VERSION ""

NS_ :

BS_:

BU_: ATCM_FFSM GENERIC_GWMWakeup IPMB Generic_BCM GWM _delete ABS_ESC HUD IPMA CCM PSCM SCCM TBM OCS TCCM TSTR RCM

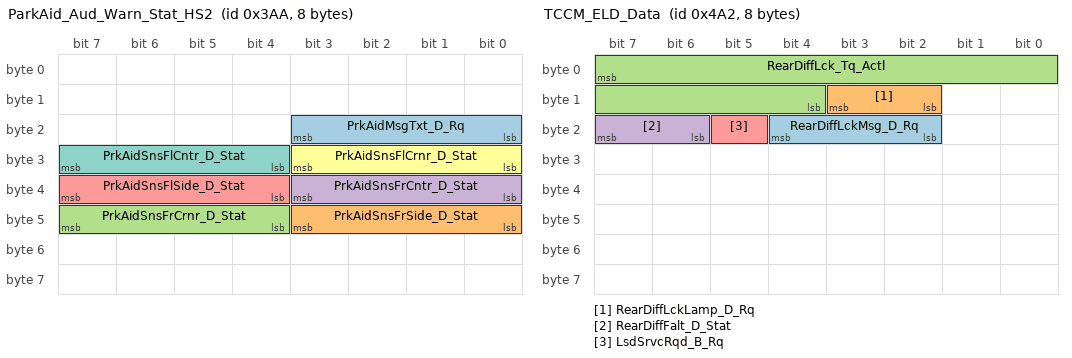
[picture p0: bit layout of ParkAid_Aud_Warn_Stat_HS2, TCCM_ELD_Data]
BO_ 938 ParkAid_Aud_Warn_Stat_HS2: 8 GWM
 SG_ PrkAidMsgTxt_D_Rq : 19|4@0+ (1,0) [0|15] "SED"  IPMB
 SG_ PrkAidSnsFrSide_D_Stat : 43|4@0+ (1,0) [0|15] "SED"  IPMB
 SG_ PrkAidSnsFrCrnr_D_Stat : 47|4@0+ (1,0) [0|15] "SED"  IPMB
 SG_ PrkAidSnsFrCntr_D_Stat : 35|4@0+ (1,0) [0|15] "SED"  IPMB
 SG_ PrkAidSnsFlSide_D_Stat : 39|4@0+ (1,0) [0|15] "SED"  IPMB
 SG_ PrkAidSnsFlCrnr_D_Stat : 27|4@0+ (1,0) [0|15] "SED"  IPMB
 SG_ PrkAidSnsFlCntr_D_Stat : 31|4@0+ (1,0) [0|15] "SED"  IPMB

BO_ 1441 TCCM_AutoSar_Network_Mgmt: 8 TCCM
 SG_ TCCM_AutoSar_Network_Mgmt : 7|64@0+ (1,0) [0|1.844674407371E+019] "unitless"  ABS_ESC,SCCM,TBM,GWM

BO_ 1472 TBM_AutoSar_Network_Mgmt: 8 TBM
 SG_ TBM_AutoSar_Network_Mgmt : 7|64@0+ (1,0) [0|1.844674407371E+019] "unitless"  TCCM,GWM,ABS_ESC

BO_ 1186 TCCM_ELD_Data: 8 TCCM
 SG_ RearDiffLckMsg_D_Rq : 20|3@0+ (1,0) [0|7] "SED"  GWM
 SG_ RearDiffLckLamp_D_Rq : 11|2@0+ (1,0) [0|3] "SED"  ATCM_FFSM,GWM
 SG_ RearDiffLck_Tq_Actl : 7|12@0+ (1,0) [0|4093] "Nm"  ABS_ESC,GWM
 SG_ RearDiffFalt_D_Stat : 23|2@0+ (1,0) [0|3] "SED"  GWM,ABS_ESC
 SG_ LsdSrvcRqd_B_Rq : 21|1@0+ (1,0) [0|1] "SED"  GWM

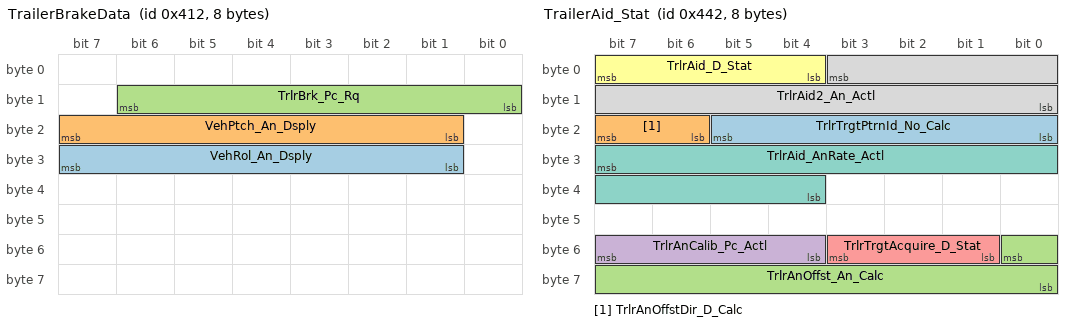
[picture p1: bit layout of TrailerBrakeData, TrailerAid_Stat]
BO_ 1042 TrailerBrakeData: 8 ABS_ESC
 SG_ VehRol_An_Dsply : 31|7@0+ (1,-64) [-64|61] "degrees"  GWM
 SG_ VehPtch_An_Dsply : 23|7@0+ (1,-64) [-64|61] "degrees"  GWM
 SG_ TrlrBrk_Pc_Rq : 14|7@0+ (1,0) [0|127] "percent"  TBM

BO_ 1090 TrailerAid_Stat: 8 IPMB
 SG_ TrlrTrgtPtrnId_No_Calc : 21|6@0+ (1,0) [0|63] "unitless"  GWM
 SG_ TrlrAnOffstDir_D_Calc : 23|2@0+ (1,0) [0|3] "SED"  PSCM,GWM
 SG_ TrlrAnOffst_An_Calc : 48|9@0+ (0.1,0) [0|51.1] "degrees"  PSCM,GWM
 SG_ TrlrAnCalib_Pc_Actl : 55|4@0+ (10,0) [0|140] "percent"  PSCM,GWM
 SG_ TrlrTrgtAcquire_D_Stat : 51|3@0+ (1,0) [0|7] "SED"  PSCM,GWM
 SG_ TrlrAid_D_Stat : 7|4@0+ (1,0) [0|15] "SED"  PSCM
 SG_ TrlrAid_AnRate_Actl : 31|12@0+ (0.1,-50) [-50|359.4] "degrees/sec"  PSCM
 SG_ TrlrAid2_An_Actl : 3|12@0+ (0.1,-90) [-90|319.4] "degrees"  PSCM

BO_ 1977 TesterPhysicalResIPMB: 8 IPMB
 SG_ TesterPhysicalResIPMB : 7|64@0+ (1,0) [0|1.84467E+019] "unitless"  TSTR

BO_ 1969 TesterPhysicalReqIPMB: 8 TSTR
 SG_ TesterPhysicalReqIPMB : 7|64@0+ (1,0) [0|1.84467E+019] "unitless"  IPMB

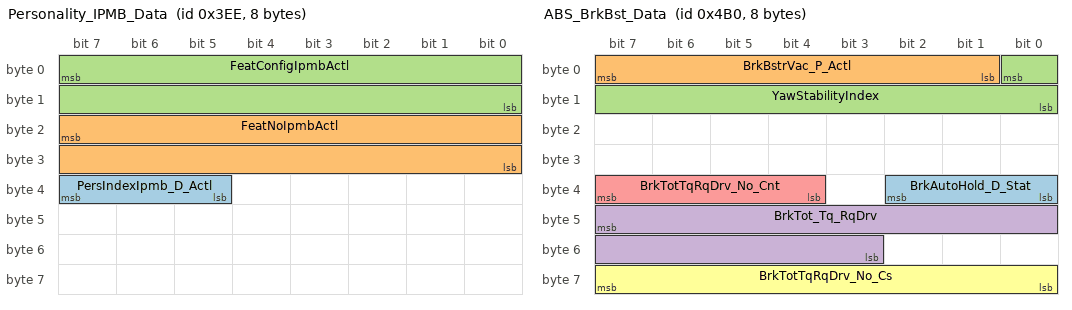
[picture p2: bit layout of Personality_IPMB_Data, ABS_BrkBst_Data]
BO_ 1006 Personality_IPMB_Data: 8 IPMB
 SG_ PersIndexIpmb_D_Actl : 39|3@0+ (1,0) [0|7] "SED"  GWM
 SG_ FeatNoIpmbActl : 23|16@0+ (1,0) [0|65535] "Number"  GWM
 SG_ FeatConfigIpmbActl : 7|16@0+ (1,0) [0|65535] "Undefined"  GWM

BO_ 1200 ABS_BrkBst_Data: 8 ABS_ESC
 SG_ BrkAutoHold_D_Stat : 34|3@0+ (1,0) [0|7] "SED"  GWM
 SG_ BrkBstrVac_P_Actl : 7|7@0+ (8,0) [0|1008] "Millibar"  GWM
 SG_ YawStabilityIndex : 0|9@0+ (1,-256) [-256|255] "%"  GWM,PSCM
 SG_ BrkTot_Tq_RqDrv : 47|13@0+ (4,0) [0|32760] "Nm"  IPMA,GWM
 SG_ BrkTotTqRqDrv_No_Cnt : 39|4@0+ (1,0) [0|15] "unitless"  GWM
 SG_ BrkTotTqRqDrv_No_Cs : 63|8@0+ (1,0) [0|255] "unitless"  GWM

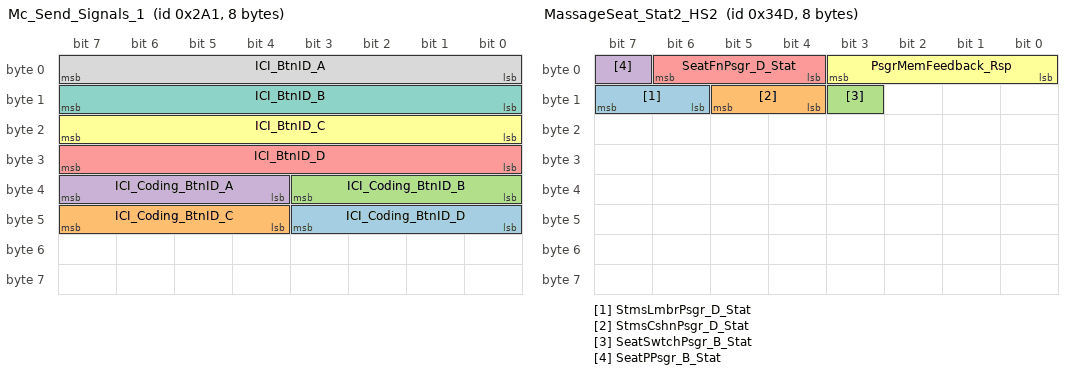
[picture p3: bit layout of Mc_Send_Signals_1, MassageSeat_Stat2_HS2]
BO_ 673 Mc_Send_Signals_1: 8 SCCM
 SG_ ICI_Coding_BtnID_D : 43|4@0+ (1,0) [0|15] "SED"  GWM
 SG_ ICI_Coding_BtnID_C : 47|4@0+ (1,0) [0|15] "SED"  GWM
 SG_ ICI_Coding_BtnID_B : 35|4@0+ (1,0) [0|15] "SED"  GWM
 SG_ ICI_Coding_BtnID_A : 39|4@0+ (1,0) [0|15] "SED"  GWM
 SG_ ICI_BtnID_D : 31|8@0+ (1,0) [0|255] "unitless"  GWM
 SG_ ICI_BtnID_C : 23|8@0+ (1,0) [0|255] "unitless"  GWM
 SG_ ICI_BtnID_B : 15|8@0+ (1,0) [0|255] "unitless"  GWM
 SG_ ICI_BtnID_A : 7|8@0+ (1,0) [0|255] "unitless"  GWM

BO_ 845 MassageSeat_Stat2_HS2: 8 GWM
 SG_ StmsLmbrPsgr_D_Stat : 15|2@0+ (1,0) [0|3] "SED"  OCS
 SG_ StmsCshnPsgr_D_Stat : 13|2@0+ (1,0) [0|3] "SED"  OCS
 SG_ SeatSwtchPsgr_B_Stat : 11|1@0+ (1,0) [0|1] "SED"  OCS
 SG_ SeatPPsgr_B_Stat : 7|1@0+ (1,0) [0|1] "SED"  OCS
 SG_ SeatFnPsgr_D_Stat : 6|3@0+ (1,0) [0|7] "SED"  OCS
 SG_ PsgrMemFeedback_Rsp : 3|4@0+ (1,0) [0|15] "SED" Vector__XXX

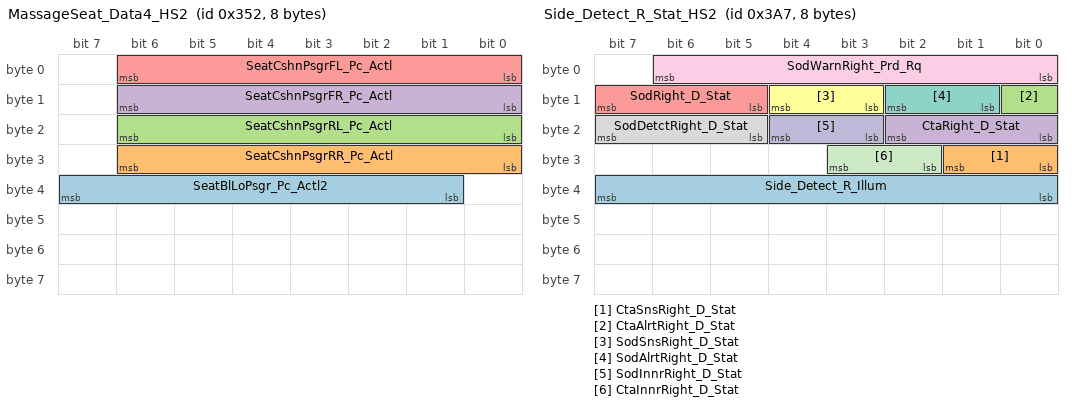
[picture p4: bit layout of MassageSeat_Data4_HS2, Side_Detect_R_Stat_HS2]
BO_ 850 MassageSeat_Data4_HS2: 8 GWM
 SG_ SeatBlLoPsgr_Pc_Actl2 : 39|7@0+ (1,0) [0|126] "Percent"  OCS
 SG_ SeatCshnPsgrRR_Pc_Actl : 30|7@0+ (1,0) [0|126] "Percent"  OCS
 SG_ SeatCshnPsgrRL_Pc_Actl : 22|7@0+ (1,0) [0|126] "Percent"  OCS
 SG_ SeatCshnPsgrFR_Pc_Actl : 14|7@0+ (1,0) [0|126] "Percent"  OCS
 SG_ SeatCshnPsgrFL_Pc_Actl : 6|7@0+ (1,0) [0|126] "Percent"  OCS

BO_ 935 Side_Detect_R_Stat_HS2: 8 GWM
 SG_ Side_Detect_R_Illum : 39|8@0+ (1,0) [0|255] "Percent" Vector__XXX
 SG_ CtaSnsRight_D_Stat : 25|2@0+ (1,0) [0|3] "SED" Vector__XXX
 SG_ CtaAlrtRight_D_Stat : 8|1@0+ (1,0) [0|1] "SED" Vector__XXX
 SG_ CtaRight_D_Stat : 18|3@0+ (1,0) [0|7] "SED" Vector__XXX
 SG_ SodRight_D_Stat : 15|3@0+ (1,0) [0|7] "SED" Vector__XXX
 SG_ SodSnsRight_D_Stat : 12|2@0+ (1,0) [0|3] "SED" Vector__XXX
 SG_ SodAlrtRight_D_Stat : 10|2@0+ (1,0) [0|3] "SED" Vector__XXX
 SG_ SodDetctRight_D_Stat : 23|3@0+ (1,0) [0|7] "SED" Vector__XXX
 SG_ SodWarnRight_Prd_Rq : 6|7@0+ (1,0) [0|127] "millisecond" Vector__XXX
 SG_ SodInnrRight_D_Stat : 20|2@0+ (1,0) [0|3] "SED" Vector__XXX
 SG_ CtaInnrRight_D_Stat : 27|2@0+ (1,0) [0|3] "SED" Vector__XXX

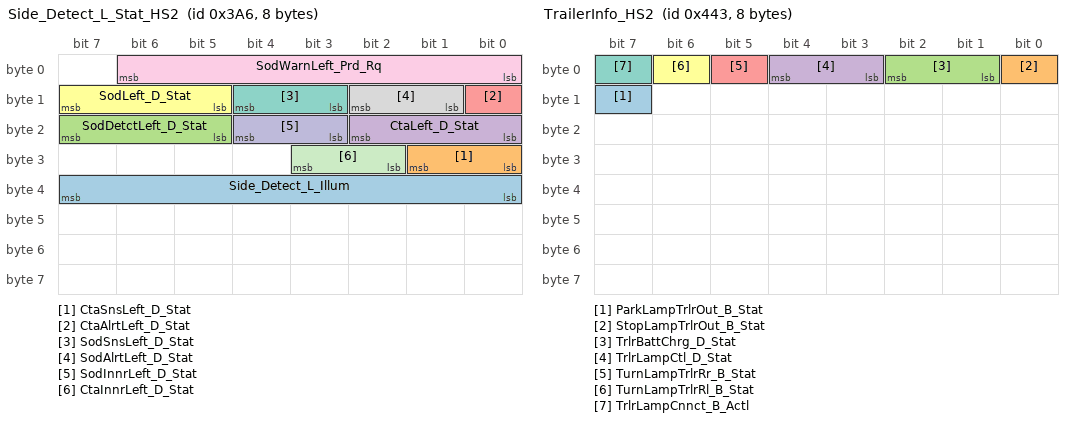
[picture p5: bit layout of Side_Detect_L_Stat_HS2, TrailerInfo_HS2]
BO_ 934 Side_Detect_L_Stat_HS2: 8 GWM
 SG_ Side_Detect_L_Illum : 39|8@0+ (1,0) [0|255] "Percent" Vector__XXX
 SG_ CtaSnsLeft_D_Stat : 25|2@0+ (1,0) [0|3] "SED" Vector__XXX
 SG_ SodDetctLeft_D_Stat : 23|3@0+ (1,0) [0|7] "SED" Vector__XXX
 SG_ CtaLeft_D_Stat : 18|3@0+ (1,0) [0|7] "SED" Vector__XXX
 SG_ CtaAlrtLeft_D_Stat : 8|1@0+ (1,0) [0|1] "SED" Vector__XXX
 SG_ SodLeft_D_Stat : 15|3@0+ (1,0) [0|7] "SED" Vector__XXX
 SG_ SodSnsLeft_D_Stat : 12|2@0+ (1,0) [0|3] "SED" Vector__XXX
 SG_ SodAlrtLeft_D_Stat : 10|2@0+ (1,0) [0|3] "SED" Vector__XXX
 SG_ SodWarnLeft_Prd_Rq : 6|7@0+ (1,0) [0|127] "millisecond" Vector__XXX
 SG_ SodInnrLeft_D_Stat : 20|2@0+ (1,0) [0|3] "SED" Vector__XXX
 SG_ CtaInnrLeft_D_Stat : 27|2@0+ (1,0) [0|3] "SED" Vector__XXX

BO_ 1091 TrailerInfo_HS2: 8 GWM
 SG_ ParkLampTrlrOut_B_Stat : 15|1@0+ (1,0) [0|1] "SED" Vector__XXX
 SG_ StopLampTrlrOut_B_Stat : 0|1@0+ (1,0) [0|1] "SED" Vector__XXX
 SG_ TrlrBattChrg_D_Stat : 2|2@0+ (1,0) [0|3] "SED" Vector__XXX
 SG_ TrlrLampCtl_D_Stat : 4|2@0+ (1,0) [0|3] "SED" Vector__XXX
 SG_ TurnLampTrlrRr_B_Stat : 5|1@0+ (1,0) [0|1] "SED" Vector__XXX
 SG_ TurnLampTrlrRl_B_Stat : 6|1@0+ (1,0) [0|1] "SED" Vector__XXX
 SG_ TrlrLampCnnct_B_Actl : 7|1@0+ (1,0) [0|1] "SED"  SCCM,PSCM,IPMB,IPMA

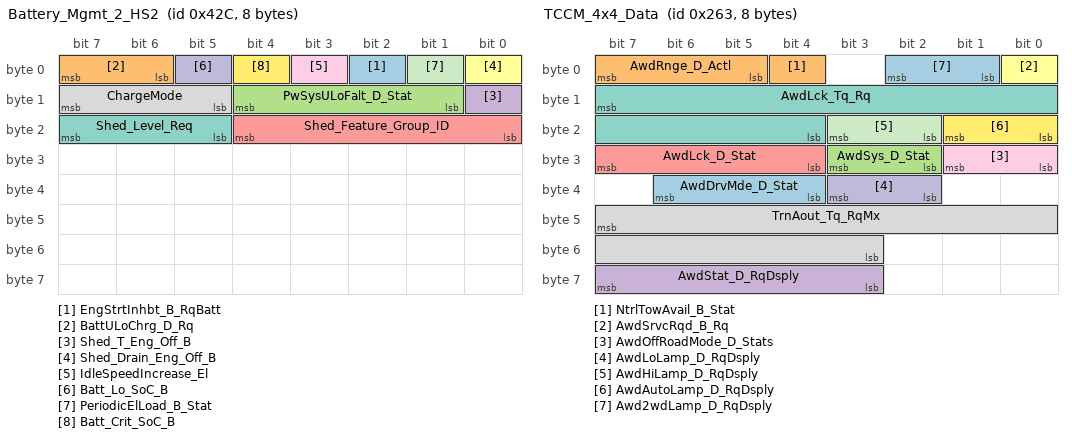
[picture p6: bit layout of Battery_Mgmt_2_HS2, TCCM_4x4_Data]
BO_ 1068 Battery_Mgmt_2_HS2: 8 GWM
 SG_ EngStrtInhbt_B_RqBatt : 2|1@0+ (1,0) [0|1] "SED" Vector__XXX
 SG_ BattULoChrg_D_Rq : 7|2@0+ (1,0) [0|3] "SED" Vector__XXX
 SG_ PwSysULoFalt_D_Stat : 12|4@0+ (1,0) [0|15] "SED"  PSCM
 SG_ Shed_T_Eng_Off_B : 8|1@0+ (1,0) [0|1] "SED"  SCCM
 SG_ Shed_Feature_Group_ID : 20|5@0+ (1,0) [0|31] "SED"  SCCM
 SG_ Shed_Drain_Eng_Off_B : 0|1@0+ (1,0) [0|1] "SED"  SCCM
 SG_ Shed_Level_Req : 23|3@0+ (1,0) [0|7] "SED"  SCCM
 SG_ ChargeMode : 15|3@0+ (1,0) [0|7] "SED" Vector__XXX
 SG_ IdleSpeedIncrease_El : 3|1@0+ (1,0) [0|1] "SED" Vector__XXX
 SG_ Batt_Lo_SoC_B : 5|1@0+ (1,0) [0|1] "SED" Vector__XXX
 SG_ PeriodicElLoad_B_Stat : 1|1@0+ (1,0) [0|1] "SED" Vector__XXX
 SG_ Batt_Crit_SoC_B : 4|1@0+ (1,0) [0|1] "SED" Vector__XXX

BO_ 611 TCCM_4x4_Data: 8 TCCM
 SG_ AwdDrvMde_D_Stat : 38|3@0+ (1,0) [0|7] "SED"  GWM
 SG_ NtrlTowAvail_B_Stat : 4|1@0+ (1,0) [0|1] "SED"  GWM
 SG_ AwdSys_D_Stat : 27|2@0+ (1,0) [0|3] "SED"  GWM
 SG_ AwdStat_D_RqDsply : 63|5@0+ (1,0) [0|31] "SED"  ABS_ESC,GWM
 SG_ AwdLck_D_Stat : 31|4@0+ (1,0) [0|15] "SED"  GWM,ABS_ESC
 SG_ AwdSrvcRqd_B_Rq : 0|1@0+ (1,0) [0|1] "SED"  ABS_ESC,GWM,RCM
 SG_ AwdLck_Tq_Rq : 15|12@0+ (1,0) [0|4093] "Nm"  ABS_ESC,GWM
 SG_ TrnAout_Tq_RqMx : 47|13@0+ (1,-1250) [-1250|6941] "Nm"  GWM
 SG_ AwdOffRoadMode_D_Stats : 25|2@0+ (1,0) [0|3] "SED"  IPMB,GWM
 SG_ AwdLoLamp_D_RqDsply : 35|2@0+ (1,0) [0|3] "SED"  ATCM_FFSM,GWM
 SG_ AwdHiLamp_D_RqDsply : 19|2@0+ (1,0) [0|3] "SED"  ATCM_FFSM,GWM
 SG_ AwdAutoLamp_D_RqDsply : 17|2@0+ (1,0) [0|3] "SED"  ATCM_FFSM,GWM
 SG_ Awd2wdLamp_D_RqDsply : 2|2@0+ (1,0) [0|3] "SED"  ATCM_FFSM,GWM
 SG_ AwdRnge_D_Actl : 7|3@0+ (1,0) [0|7] "SED"  IPMB,PSCM,ABS_ESC,GWM

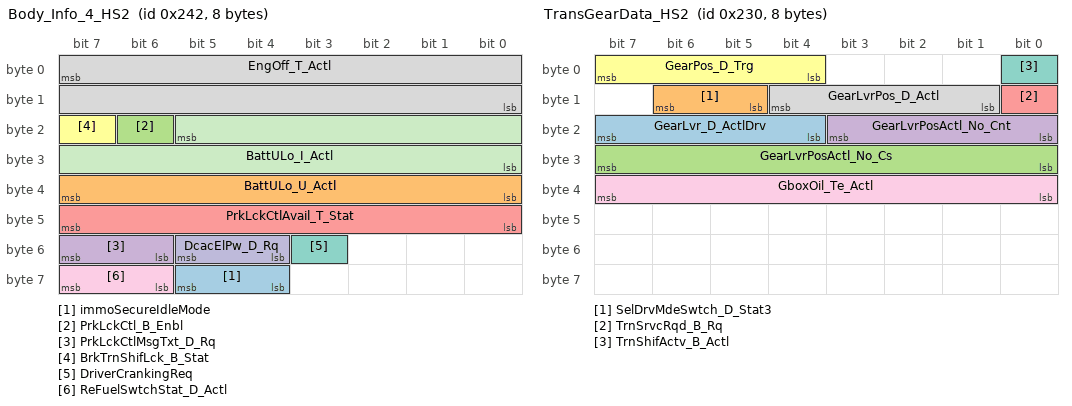
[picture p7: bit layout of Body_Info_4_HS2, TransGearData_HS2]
BO_ 578 Body_Info_4_HS2: 8 GWM
 SG_ immoSecureIdleMode : 61|2@0+ (1,0) [0|3] "SED" Vector__XXX
 SG_ BattULo_U_Actl : 39|8@0+ (0.0625,0) [0|15.875] "volt"  IPMA
 SG_ PrkLckCtl_B_Enbl : 22|1@0+ (1,0) [0|1] "SED" Vector__XXX
 SG_ PrkLckCtlMsgTxt_D_Rq : 55|2@0+ (1,0) [0|3] "SED" Vector__XXX
 SG_ PrkLckCtlAvail_T_Stat : 47|8@0+ (1,0) [0|255] "second" Vector__XXX
 SG_ BrkTrnShifLck_B_Stat : 23|1@0+ (1,0) [0|1] "SED" Vector__XXX
 SG_ DriverCrankingReq : 51|1@0+ (1,0) [0|1] "SED" Vector__XXX
 SG_ EngOff_T_Actl : 7|16@0+ (1,0) [0|65534] "second^0.5"  ABS_ESC,IPMA
 SG_ ReFuelSwtchStat_D_Actl : 63|2@0+ (1,0) [0|3] "SED" Vector__XXX
 SG_ DcacElPw_D_Rq : 53|2@0+ (1,0) [0|3] "SED" Vector__XXX
 SG_ BattULo_I_Actl : 21|14@0+ (0.0625,-512) [-512|511.875] "ampere" Vector__XXX

BO_ 560 TransGearData_HS2: 8 GWM
 SG_ GearLvr_D_ActlDrv : 23|4@0+ (1,0) [0|15] "SED"  IPMB
 SG_ SelDrvMdeSwtch_D_Stat3 : 14|2@0+ (1,0) [0|3] "SED"  ABS_ESC
 SG_ GearLvrPosActl_No_Cs : 31|8@0+ (1,0) [0|255] "Unitless" Vector__XXX
 SG_ GearLvrPosActl_No_Cnt : 19|4@0+ (1,0) [0|15] "Unitless" Vector__XXX
 SG_ TrnSrvcRqd_B_Rq : 8|1@0+ (1,0) [0|1] "SED"  RCM
 SG_ GearPos_D_Trg : 7|4@0+ (1,0) [0|15] "SED"  ABS_ESC,TCCM
 SG_ TrnShifActv_B_Actl : 0|1@0+ (1,0) [0|1] "SED"  ABS_ESC
 SG_ GearLvrPos_D_Actl : 12|4@0+ (1,0) [0|15] "SED"  IPMB,IPMA,PSCM,SCCM,RCM,CCM,ABS_ESC,TCCM
 SG_ GboxOil_Te_Actl : 39|8@0+ (1,-60) [-60|193] "degC"  TCCM

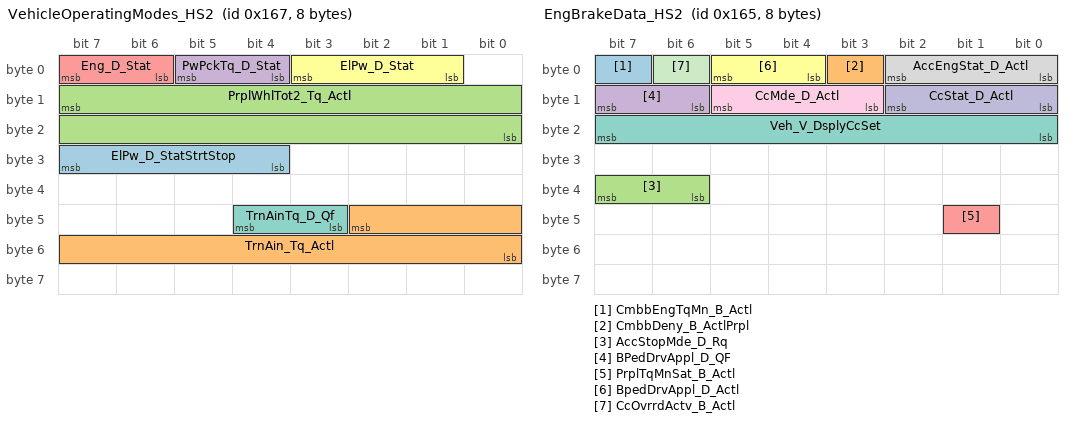
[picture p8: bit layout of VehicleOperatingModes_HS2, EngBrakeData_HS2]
BO_ 359 VehicleOperatingModes_HS2: 8 GWM
 SG_ ElPw_D_StatStrtStop : 31|4@0+ (1,0) [0|15] "SED"  SCCM,PSCM
 SG_ TrnAin_Tq_Actl : 42|11@0+ (1,-500) [-500|1547] "Nm" Vector__XXX
 SG_ PrplWhlTot2_Tq_Actl : 15|16@0+ (4,-131072) [-131072|131060] "Nm"  RCM,ABS_ESC,TCCM
 SG_ PwPckTq_D_Stat : 5|2@0+ (1,0) [0|3] "SED"  IPMB,TCCM,TBM,SCCM,PSCM,OCS,IPMA,HUD,CCM,ABS_ESC
 SG_ Eng_D_Stat : 7|2@0+ (1,0) [0|3] "SED"  ABS_ESC
 SG_ ElPw_D_Stat : 3|3@0+ (1,0) [0|7] "SED"  IPMA,PSCM,ABS_ESC,CCM,HUD,OCS,SCCM,TBM,TCCM
 SG_ TrnAinTq_D_Qf : 44|2@0+ (1,0) [0|3] "SED" Vector__XXX

BO_ 357 EngBrakeData_HS2: 8 GWM
 SG_ CmbbEngTqMn_B_Actl : 7|1@0+ (1,0) [0|1] "SED"  IPMA
 SG_ CmbbDeny_B_ActlPrpl : 3|1@0+ (1,0) [0|1] "SED"  IPMA
 SG_ AccStopMde_D_Rq : 39|2@0+ (1,0) [0|3] "SED"  ABS_ESC,IPMA
 SG_ BPedDrvAppl_D_QF : 15|2@0+ (1,0) [0|3] "SED"  OCS,RCM,ABS_ESC,CCM
 SG_ PrplTqMnSat_B_Actl : 41|1@0+ (1,0) [0|1] "SED"  IPMA,CCM
 SG_ BpedDrvAppl_D_Actl : 5|2@0+ (1,0) [0|3] "SED"  IPMA,OCS,TBM,TCCM,ABS_ESC,CCM,RCM
 SG_ Veh_V_DsplyCcSet : 23|8@0+ (1,0) [0|253] "Unitless" Vector__XXX
 SG_ AccEngStat_D_Actl : 2|3@0+ (1,0) [0|7] "SED"  IPMA,CCM
 SG_ CcMde_D_Actl : 13|3@0+ (1,0) [0|7] "SED"  ABS_ESC
 SG_ CcStat_D_Actl : 10|3@0+ (1,0) [0|7] "SED"  IPMA,TCCM,ABS_ESC,CCM,OCS,RCM
 SG_ CcOvrrdActv_B_Actl : 6|1@0+ (1,0) [0|1] "SED"  IPMA,TCCM,ABS_ESC,CCM,RCM

BO_ 1461 PSCM_AutoSar_Network_Mgmt: 8 PSCM
 SG_ PSCM_AutoSar_Network_Mgmt : 7|64@0+ (1,0) [0|1.844674407371E+019] "unitless"  TCCM,SCCM,GWM,ABS_ESC

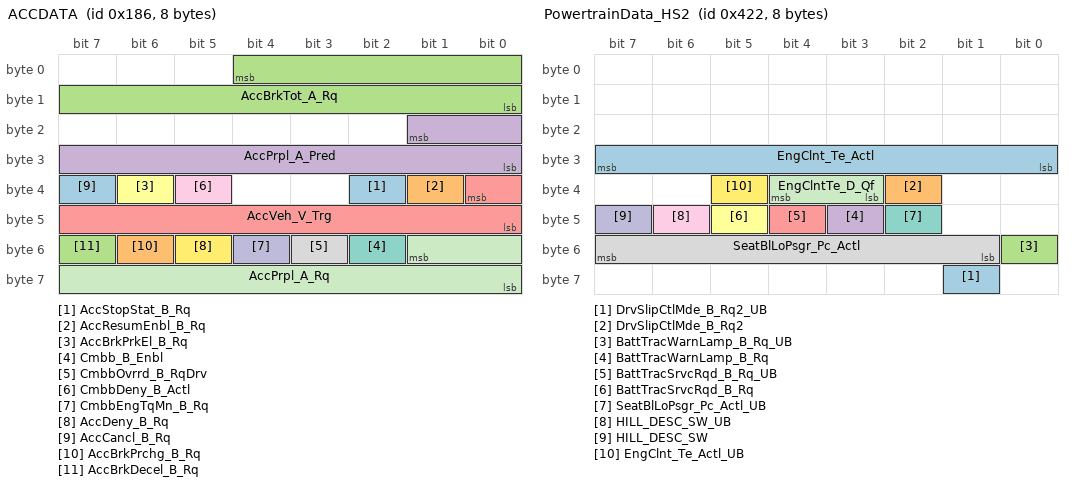
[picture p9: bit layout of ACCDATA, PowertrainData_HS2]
BO_ 390 ACCDATA: 8 CCM
 SG_ AccStopStat_B_Rq : 34|1@0+ (1,0) [0|1] "SED"  ABS_ESC,GWM
 SG_ AccResumEnbl_B_Rq : 33|1@0+ (1,0) [0|1] "SED"  GWM
 SG_ AccBrkTot_A_Rq : 4|13@0+ (0.0039,-20) [-20|11.9449] "m/s^2"  ABS_ESC,GWM
 SG_ AccPrpl_A_Pred : 17|10@0+ (0.01,-5) [-5|5.23] "m/s^2"  GWM
 SG_ AccVeh_V_Trg : 32|9@0+ (0.5,0) [0|255.5] "kph"  GWM
 SG_ AccBrkPrkEl_B_Rq : 38|1@0+ (1,0) [0|1] "SED"  ABS_ESC,GWM
 SG_ Cmbb_B_Enbl : 50|1@0+ (1,0) [0|1] "SED"  RCM,GWM
 SG_ CmbbOvrrd_B_RqDrv : 51|1@0+ (1,0) [0|1] "SED"  RCM,GWM
 SG_ CmbbDeny_B_Actl : 37|1@0+ (1,0) [0|1] "SED"  ABS_ESC,RCM,GWM
 SG_ CmbbEngTqMn_B_Rq : 52|1@0+ (1,0) [0|1] "SED"  GWM
 SG_ AccPrpl_A_Rq : 49|10@0+ (0.01,-5) [-5|5.23] "m/s^2"  GWM
 SG_ AccDeny_B_Rq : 53|1@0+ (1,0) [0|1] "SED"  GWM
 SG_ AccCancl_B_Rq : 39|1@0+ (1,0) [0|1] "SED"  ABS_ESC,GWM
 SG_ AccBrkPrchg_B_Rq : 54|1@0+ (1,0) [0|1] "SED"  ABS_ESC,GWM
 SG_ AccBrkDecel_B_Rq : 55|1@0+ (1,0) [0|1] "SED"  GWM,ABS_ESC

BO_ 1072 Cluster_Info1_HS2: 8 GWM
 SG_ TrlrAidCancl_B_Rq_UB : 56|1@0+ (1,0) [0|1] "SED"  PSCM
 SG_ TrlrAidCancl_B_Rq : 57|1@0+ (1,0) [0|1] "SED"  IPMB,PSCM
 SG_ HsaMde_D_Rq : 51|2@0+ (1,0) [0|3] "SED" Vector__XXX
 SG_ HsaMde_D_Rq_UB : 49|1@0+ (1,0) [0|1] "SED" Vector__XXX
 SG_ Multimedia_System_UB : 55|1@0+ (1,0) [0|1] "SED" Vector__XXX
 SG_ Multimedia_System : 39|1@0+ (1,0) [0|1] "SED" Vector__XXX
 SG_ LscmbbStat_B_Actl : 53|1@0+ (1,0) [0|1] "SED" Vector__XXX
 SG_ LscmbbStat_B_Actl_UB : 52|1@0+ (1,0) [0|1] "SED" Vector__XXX
 SG_ Outside_Air_Temp_Stat_UB : 3|1@0+ (1,0) [0|1] "SED"  IPMA,CCM
 SG_ Outside_Air_Temp_Stat : 47|8@0+ (0.5,-40) [-40|86.5] "Degrees C"  IPMA,CCM
 SG_ BulbChkActv_B_Stat_UB : 5|1@0+ (1,0) [0|1] "SED"  HUD
 SG_ BulbChkActv_B_Stat : 6|1@0+ (1,0) [0|1] "SED"  HUD
 SG_ Fda_B_Stat_UB : 4|1@0+ (1,0) [0|1] "SED"  IPMA,CCM
 SG_ AccEnbl_B_RqDrv_UB : 2|1@0+ (1,0) [0|1] "SED"  IPMA,CCM
 SG_ AccDeny_B_RqIpc_UB : 1|1@0+ (1,0) [0|1] "SED"  IPMA,CCM
 SG_ OdometerMasterValue_UB : 0|1@0+ (1,0) [0|1] "SED"  ABS_ESC,IPMA,PSCM
 SG_ OdometerMasterValue : 15|24@0+ (1,0) [0|16777214] "km"  ABS_ESC,IPMA,PSCM
 SG_ Fda_B_Stat : 36|1@0+ (1,0) [0|1] "SED"  IPMA,CCM
 SG_ AccDeny_B_RqIpc : 7|1@0+ (1,0) [0|1] "SED"  IPMA,CCM
 SG_ AccEnbl_B_RqDrv : 35|1@0+ (1,0) [0|1] "SED"  IPMA,CCM
 SG_ DrvSlipCtlMde_D_Rq_UB : 38|1@0+ (1,0) [0|1] "SED" Vector__XXX
 SG_ DrvSlipCtlMde_D_Rq : 33|2@0+ (1,0) [0|3] "SED" Vector__XXX
 SG_ DrvSlipCtlMde_B_Rq_UB : 37|1@0+ (1,0) [0|1] "SED" Vector__XXX
 SG_ DrvSlipCtlMde_B_Rq : 34|1@0+ (1,0) [0|1] "SED"  ABS_ESC
 SG_ ePRNDL_MODE_UB : 48|1@0+ (1,0) [0|1] "SED" Vector__XXX
 SG_ ePRNDL_MODE : 54|1@0+ (1,0) [0|1] "SED" Vector__XXX
 SG_ TrlrBrkMde_D_Rq : 63|1@0+ (1,0) [0|1] "SED"  TBM
 SG_ TRLR_SWAY_CONFIG_CMD : 62|1@0+ (1,0) [0|1] "SED"  ABS_ESC
 SG_ TRAILER_BRAKE_CONFIG : 61|1@0+ (1,0) [0|1] "SED"  TBM
 SG_ TrlrBrkMde_D_Rq_UB : 60|1@0+ (1,0) [0|1] "SED"  TBM
 SG_ TRLR_SWAY_CONFIG_CMD_UB : 59|1@0+ (1,0) [0|1] "SED"  ABS_ESC
 SG_ TRAILER_BRAKE_CONFIG_UB : 58|1@0+ (1,0) [0|1] "SED"  TBM

BO_ 1058 PowertrainData_HS2: 8 GWM
 SG_ DrvSlipCtlMde_B_Rq2_UB : 57|1@0+ (1,0) [0|1] "SED"  ABS_ESC
 SG_ DrvSlipCtlMde_B_Rq2 : 34|1@0+ (1,0) [0|1] "SED"  ABS_ESC
 SG_ BattTracWarnLamp_B_Rq_UB : 48|1@0+ (1,0) [0|1] "SED" Vector__XXX
 SG_ BattTracWarnLamp_B_Rq : 43|1@0+ (1,0) [0|1] "SED" Vector__XXX
 SG_ BattTracSrvcRqd_B_Rq_UB : 44|1@0+ (1,0) [0|1] "SED" Vector__XXX
 SG_ BattTracSrvcRqd_B_Rq : 45|1@0+ (1,0) [0|1] "SED" Vector__XXX
 SG_ SeatBlLoPsgr_Pc_Actl_UB : 42|1@0+ (1,0) [0|1] "SED" Vector__XXX
 SG_ SeatBlLoPsgr_Pc_Actl : 55|7@0+ (1,0) [0|126] "Percent" Vector__XXX
 SG_ HILL_DESC_SW_UB : 46|1@0+ (1,0) [0|1] "SED"  ABS_ESC
 SG_ HILL_DESC_SW : 47|1@0+ (1,0) [0|1] "SED"  ABS_ESC
 SG_ EngClntTe_D_Qf : 36|2@0+ (1,0) [0|3] "SED" Vector__XXX
 SG_ EngClnt_Te_Actl_UB : 37|1@0+ (1,0) [0|1] "SED" Vector__XXX
 SG_ EngClnt_Te_Actl : 31|8@0+ (1,-60) [-60|195] "degC" Vector__XXX

BO_ 1430 ABS_AutoSar_Network_Mgmt: 8 ABS_ESC
 SG_ ABS_AutoSar_Network_Mgmt : 7|64@0+ (1,0) [0|1.844674407371E+019] "unitless"  TCCM,TBM,SCCM,GWM

BO_ 1889 TesterPhysicalReqTCCM: 8 TSTR
 SG_ TesterPhysicalReqTCCM : 7|64@0+ (1,0) [0|1.84467E+019] "unitless"  TCCM

BO_ 1897 TesterPhysicalResTCCM: 8 TCCM
 SG_ TesterPhysicalResTCCM : 7|64@0+ (1,0) [0|1.84467E+019] "unitless"  TSTR

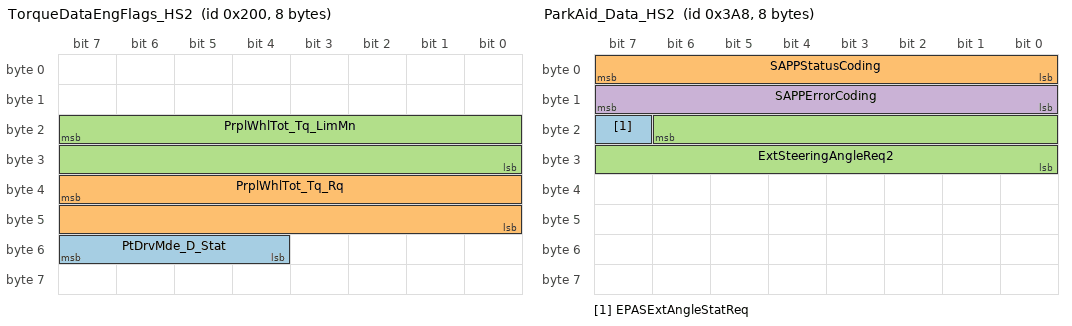
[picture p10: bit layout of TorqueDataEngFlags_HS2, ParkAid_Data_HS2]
BO_ 512 TorqueDataEngFlags_HS2: 8 GWM
 SG_ PtDrvMde_D_Stat : 55|4@0+ (1,0) [0|15] "SED"  IPMA
 SG_ PrplWhlTot_Tq_Rq : 39|16@0+ (4,-131072) [-131072|131068] "Nm"  TCCM,ABS_ESC
 SG_ PrplWhlTot_Tq_LimMn : 23|16@0+ (4,-131072) [-131072|131068] "Nm" Vector__XXX

BO_ 936 ParkAid_Data_HS2: 8 GWM
 SG_ EPASExtAngleStatReq : 23|1@0+ (1,0) [0|1] "SED"  ABS_ESC,PSCM
 SG_ SAPPStatusCoding : 7|8@0+ (1,0) [0|255] "unitless"  IPMB,PSCM
 SG_ ExtSteeringAngleReq2 : 22|15@0+ (0.1,-1000) [-1000|2276.5] "Degrees"  PSCM
 SG_ SAPPErrorCoding : 15|8@0+ (1,0) [0|255] "SED" Vector__XXX

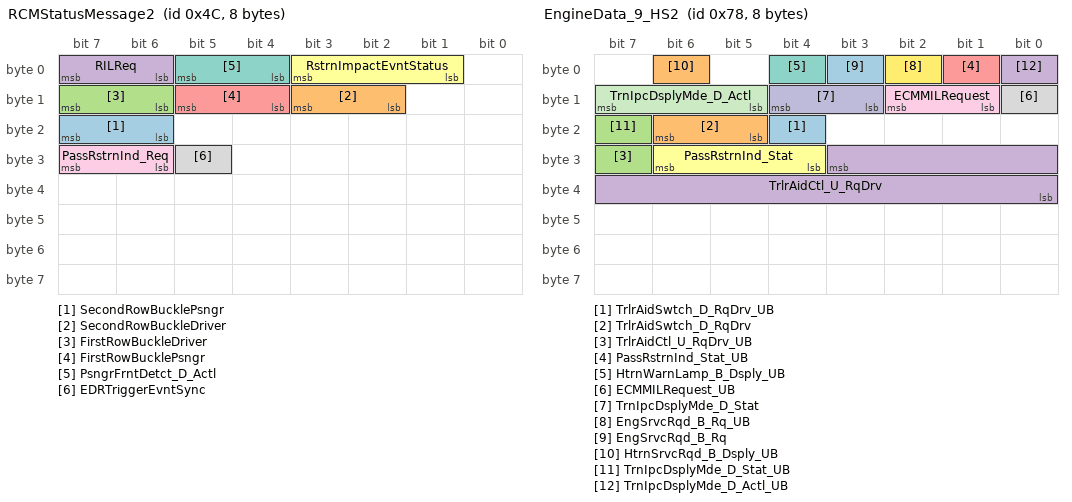
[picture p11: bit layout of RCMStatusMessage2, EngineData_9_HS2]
BO_ 76 RCMStatusMessage2: 8 RCM
 SG_ SecondRowBucklePsngr : 23|2@0+ (1,0) [0|3] "SED"  GWM
 SG_ SecondRowBuckleDriver : 11|2@0+ (1,0) [0|3] "SED"  GWM
 SG_ FirstRowBuckleDriver : 15|2@0+ (1,0) [0|3] "SED"  ABS_ESC,IPMA,CCM,GWM
 SG_ RILReq : 7|2@0+ (1,0) [0|3] "SED"  GWM
 SG_ FirstRowBucklePsngr : 13|2@0+ (1,0) [0|3] "SED"  OCS,GWM
 SG_ RstrnImpactEvntStatus : 3|3@0+ (1,0) [0|7] "SED"  OCS,CCM,GWM,IPMA
 SG_ PsngrFrntDetct_D_Actl : 5|2@0+ (1,0) [0|3] "SED"  GWM
 SG_ EDRTriggerEvntSync : 29|1@0+ (1,0) [0|1] "SED"  IPMA,GWM,CCM
 SG_ PassRstrnInd_Req : 31|2@0+ (1,0) [0|3] "SED"  GWM

BO_ 120 EngineData_9_HS2: 8 GWM
 SG_ TrlrAidSwtch_D_RqDrv_UB : 20|1@0+ (1,0) [0|1] "SED"  PSCM
 SG_ TrlrAidSwtch_D_RqDrv : 22|2@0+ (1,0) [0|3] "SED"  PSCM
 SG_ TrlrAidCtl_U_RqDrv_UB : 31|1@0+ (1,0) [0|1] "SED"  PSCM
 SG_ TrlrAidCtl_U_RqDrv : 27|12@0+ (0.00125,0) [0|5.11625] "volt"  PSCM
 SG_ PassRstrnInd_Stat_UB : 1|1@0+ (1,0) [0|1] "SED"  RCM
 SG_ PassRstrnInd_Stat : 30|3@0+ (1,0) [0|7] "SED"  RCM
 SG_ HtrnWarnLamp_B_Dsply_UB : 4|1@0+ (1,0) [0|1] "SED" Vector__XXX
 SG_ ECMMILRequest_UB : 8|1@0+ (1,0) [0|1] "SED"  RCM
 SG_ ECMMILRequest : 10|2@0+ (1,0) [0|3] "SED"  RCM
 SG_ TrnIpcDsplyMde_D_Stat : 12|2@0+ (1,0) [0|3] "SED" Vector__XXX
 SG_ TrnIpcDsplyMde_D_Actl : 15|3@0+ (1,0) [0|7] "SED" Vector__XXX
 SG_ EngSrvcRqd_B_Rq_UB : 2|1@0+ (1,0) [0|1] "SED" Vector__XXX
 SG_ EngSrvcRqd_B_Rq : 3|1@0+ (1,0) [0|1] "SED"  RCM
 SG_ HtrnSrvcRqd_B_Dsply_UB : 6|1@0+ (1,0) [0|1] "SED" Vector__XXX
 SG_ TrnIpcDsplyMde_D_Stat_UB : 23|1@0+ (1,0) [0|1] "SED" Vector__XXX
 SG_ TrnIpcDsplyMde_D_Actl_UB : 0|1@0+ (1,0) [0|1] "SED" Vector__XXX

BO_ 1665 RCM_Rapid_Data_Response_2: 8 RCM
 SG_ UUDTRCMResponse2 : 7|64@0+ (1,0) [0|1.844674407371E+019] "unitless"  TSTR

BO_ 2041 TesterPhysicalResPCU: 8 RCM
 SG_ TesterPhysicalResPCU : 7|64@0+ (1,0) [0|1.84467E+019] "unitless"  TSTR

BO_ 1438 GWM_AutoSar_NetMgmt_HS2: 8 GWM
 SG_ GWM_AutoSar_NetworkMgmt_H2 : 7|64@0+ (1,0) [0|1.844674407371E+019] "unitless"  ATCM_FFSM,TCCM,TBM,ABS_ESC,SCCM

BO_ 1034 GGCC_Config_Mgmt_ID_1_HS2: 8 GWM
 SG_ VehicleGGCCData : 7|64@0+ (1,0) [0|1.84467E+019] "mixed"  IPMA,TCCM,ABS_ESC,OCS,RCM,CCM,TBM,HUD,PSCM,SCCM

BO_TX_BU_ 390 : IPMA,CCM;
CM_ BO_ 673 "Do not use this Frame for other Cluster Interaction";
CM_ SG_ 673 ICI_Coding_BtnID_D "Object InputControlInterface ICI ButtonCoding_D
(Parameter2)";
CM_ SG_ 673 ICI_Coding_BtnID_C "Object InputControlInterface ICI ButtonCoding_C
(Parameter2)";
CM_ SG_ 673 ICI_Coding_BtnID_B "Object InputControlInterface ICI ButtonCoding_B
(Parameter2)";
CM_ SG_ 673 ICI_Coding_BtnID_A "Object InputControlInterface ICI ButtonCoding_A
(Parameter2)";
CM_ SG_ 673 ICI_BtnID_D "Object InputControlInterface ICI ButtonID_D
(Parameter1)
for detailed Information refer to ICI Reference document";
CM_ SG_ 673 ICI_BtnID_C "Object InputControlInterface ICI ButtonID_C
(Parameter1)
for detailed Information refer to ICI Reference document";
CM_ SG_ 673 ICI_BtnID_B "Object InputControlInterface ICI ButtonID_B
(Parameter1)
for detailed Information refer to ICI Reference document";
CM_ SG_ 673 ICI_BtnID_A "Object InputControlInterface ICI ButtonID_A
(Parameter1)
for detailed Information refer to ICI Reference document";
CM_ SG_ 935 Side_Detect_R_Illum "DDMGenSigTimeoutTime=2000";
CM_ SG_ 935 SodRight_D_Stat "IPCGenSigTimeoutTime=1600";
CM_ SG_ 935 SodSnsRight_D_Stat "IPCGenSigTimeoutTime=1600";
CM_ SG_ 935 SodAlrtRight_D_Stat "DDMGenSigTimeoutTime=2000";
CM_ SG_ 935 CtaInnrRight_D_Stat "IPCGenSigTimeoutTime=1600";
CM_ SG_ 934 Side_Detect_L_Illum "DDMGenSigTimeoutTime=2000";
CM_ SG_ 934 SodLeft_D_Stat "IPCGenSigTimeoutTime=1600";
CM_ SG_ 934 SodSnsLeft_D_Stat "IPCGenSigTimeoutTime=1600";
CM_ SG_ 934 SodAlrtLeft_D_Stat "DDMGenSigTimeoutTime=2000";
CM_ SG_ 934 CtaInnrLeft_D_Stat "IPCGenSigTimeoutTime=1600";
CM_ SG_ 1091 TrlrLampCnnct_B_Actl "Not supported on CD4 M1";
CM_ BO_ 611 "Used on Applications with 4x4 supplied by Motorola.";
CM_ SG_ 611 AwdStat_D_RqDsply "Signal not transmitted on programs that do not have AWD.";
CM_ SG_ 611 AwdSrvcRqd_B_Rq "Signal not transmitted on programs that do not have AWD.";
CM_ SG_ 611 AwdLck_Tq_Rq "Signal not transmitted on programs that do not have AWD.";
CM_ SG_ 560 GearLvrPosActl_No_Cs "Signal not transmitted on gas and HEV variants.";
CM_ SG_ 560 GearLvrPosActl_No_Cnt "Signal not transmitted on gas and HEV variants.";
CM_ SG_ 560 TrnSrvcRqd_B_Rq "Signal not transmitted on Diesel and HEV variants.";
CM_ SG_ 560 GearPos_D_Trg "Signal not transmitted on HEV variants.";
CM_ SG_ 560 TrnShifActv_B_Actl "Signal not transmitted on HEV variants.";
CM_ SG_ 560 GboxOil_Te_Actl "Signal not transmitted on HEV variants.";
CM_ SG_ 359 TrnAin_Tq_Actl "Signal not transmitted on HEV variances.";
CM_ SG_ 359 TrnAinTq_D_Qf "Signal not transmitted on HEV variances.";
CM_ SG_ 357 AccStopMde_D_Rq "ABSGenSigTimeoutTime=1000";
CM_ SG_ 357 BpedDrvAppl_D_Actl "CCMGenSigTimeoutTime=1000";
CM_ SG_ 357 CcStat_D_Actl "ABSGenSigTimeoutTime=1000";
CM_ SG_ 390 AccStopStat_B_Rq "ABSGenSigTimeoutTime=1000";
CM_ SG_ 390 AccBrkTot_A_Rq "ABSGenSigTimeoutTime=1000";
CM_ SG_ 390 AccBrkPrkEl_B_Rq "ABSGenSigTimeoutTime=1000";
CM_ SG_ 390 AccPrpl_A_Rq "PCMGenSigTimeoutTime=1000";
CM_ SG_ 390 AccBrkPrchg_B_Rq "ABSGenSigTimeoutTime=1000";
CM_ SG_ 390 AccBrkDecel_B_Rq "ABSGenSigTimeoutTime=1000";
CM_ SG_ 1072 Outside_Air_Temp_Stat "Filtered value, i.e. same as disply for customer";
CM_ SG_ 1034 VehicleGGCCData "RCMGenSigTimeout=6000";
BA_DEF_ SG_  "U_UP375_MY19_Gas_Rx" ENUM  "No","Yes";
BA_DEF_ SG_  "U_UP375_MY19_Diesel_Rx" ENUM  "No","Yes";
BA_DEF_ SG_  "U_V36X_MY19_Rx" ENUM  "No","Yes";
BA_DEF_ SG_  "U_UP375_MY19_Gas_Tx" ENUM  "No","Yes";
BA_DEF_ SG_  "U_UP375_MY19_Diesel_Tx" ENUM  "No","Yes";
BA_DEF_ SG_  "U_V36X_MY19_Tx" ENUM  "No","Yes";
BA_DEF_ SG_  "U_UP375_MY18_Gas_Rx" ENUM  "No","Yes";
BA_DEF_ SG_  "U_UP375_MY18_Diesel_Rx" ENUM  "No","Yes";
BA_DEF_ SG_  "U_V36X_MY18_5_Gas_Rx" ENUM  "No","Yes";
BA_DEF_ SG_  "U_V36X_MY18_5_Hev_Rx" ENUM  "No","Yes";
BA_DEF_ SG_  "U_UP375_MY18_Gas_Tx" ENUM  "No","Yes";
BA_DEF_ SG_  "U_UP375_MY18_Diesel_Tx" ENUM  "No","Yes";
BA_DEF_ SG_  "U_V36X_MY18_5_Gas_Tx" ENUM  "No","Yes";
BA_DEF_ SG_  "U_V36X_MY18_5_Hev_Tx" ENUM  "No","Yes";
BA_DEF_ SG_  "GenSigTimeoutTime_HCM_HS2" INT 0 100000;
BA_DEF_ SG_  "U_V36X_MY19_5_Diesel_Rx" ENUM  "No","Yes";
BA_DEF_ SG_  "U_V363E_N_MY19_5_20_Gas_Rx" ENUM  "No","Yes";
BA_DEF_ SG_  "U_V363E_N_MY19_5_20_Diesel_Rx" ENUM  "No","Yes";
BA_DEF_ SG_  "U_CD42_MY19_Diesel_Rx" ENUM  "No","Yes";
BA_DEF_ SG_  "U_CD42_MY19_Gas_Rx" ENUM  "No","Yes";
BA_DEF_ SG_  "U_V36X_MY19_5_Diesel_Tx" ENUM  "No","Yes";
BA_DEF_ SG_  "U_V363E_N_MY19_5_20_Gas_Tx" ENUM  "No","Yes";
BA_DEF_ SG_  "U_V363E_N_MY19_5_20_Diesel_Tx" ENUM  "No","Yes";
BA_DEF_ SG_  "U_CD42_MY19_Diesel_Tx" ENUM  "No","Yes";
BA_DEF_ SG_  "U_CD42_MY19_Gas_Tx" ENUM  "No","Yes";
BA_DEF_ BO_  "FrameGatewayNetworkold" ENUM  "None","HS1_CAN","HS2_CAN","HS3_CAN","MS1_CAN";
BA_DEF_ SG_  "U_B562_MY18_Gas_Rx" ENUM  "No","Yes";
BA_DEF_ SG_  "U_C490_MY18_Diesel_Rx" ENUM  "No","Yes";
BA_DEF_ SG_  "U_C490_MY18_Gas_Rx" ENUM  "No","Yes";
BA_DEF_ SG_  "U_V408_MY18_Gas_Rx" ENUM  "No","Yes";
BA_DEF_ SG_  "U_V408_MY18_Diesel_Rx" ENUM  "No","Yes";
BA_DEF_ SG_  "U_V36X_MY18_5_Diesel_Rx" ENUM  "No","Yes";
BA_DEF_ SG_  "U_V408_MY18_Gas_Tx" ENUM  "No","Yes";
BA_DEF_ SG_  "U_V408_MY18_Diesel_Tx" ENUM  "No","Yes";
BA_DEF_ SG_  "U_V36X_MY18_5_Diesel_Tx" ENUM  "No","Yes";
BA_DEF_ SG_  "U_P552_MY18_5_Gas_Tx" ENUM  "No","Yes";
BA_DEF_ SG_  "U_P552_MY18_5_Diesel_Tx" ENUM  "No","Yes";
BA_DEF_ SG_  "U_U502_MY17_Gas_Rx" ENUM  "No","Yes";
BA_DEF_ SG_  "U_S550_MY18_Gas_Rx" ENUM  "No","Yes";
BA_DEF_ SG_  "U_U502_MY17_Gas_Tx" ENUM  "No","Yes";
BA_DEF_ SG_  "U_S550_MY18_Gas_Tx" ENUM  "No","Yes";
BA_DEF_ SG_  "GenSigTimeoutTime_ATCM_FFSM" INT 0 100000;
BA_DEF_ SG_  "GenSigTimeoutTime_ATCM_DMSM" INT 0 100000;
BA_DEF_ SG_  "U_C489_MY17_Gas_Rx" ENUM  "No","Yes";
BA_DEF_ SG_  "U_P552_MY18_Gas_Rx" ENUM  "No","Yes";
BA_DEF_ SG_  "U_U55x_MY18_Gas_Rx" ENUM  "No","Yes";
BA_DEF_ SG_  "U_C489_MY17_Gas_Tx" ENUM  "No","Yes";
BA_DEF_ SG_  "U_P552_MY18_Gas_Tx" ENUM  "No","Yes";
BA_DEF_ SG_  "U_U55x_MY18_Gas_Tx" ENUM  "No","Yes";
BA_DEF_ BO_  "FrameGatewayNetwork" STRING ;
BA_DEF_ SG_  "U_CD43_MY17_Gas_Rx" ENUM  "No","Yes";
BA_DEF_ SG_  "U_P552_MY17_Gas_Rx" ENUM  "No","Yes";
BA_DEF_ SG_  "U_P552_MY17_Diesel_Rx" ENUM  "No","Yes";
BA_DEF_ SG_  "U_B515_MCA_MY17_Diesel_Rx" ENUM  "No","Yes";
BA_DEF_ SG_  "U_B515_MCA_MY17_Gas_Rx" ENUM  "No","Yes";
BA_DEF_ SG_  "U_CD43_MY17_Gas_Tx" ENUM  "No","Yes";
BA_DEF_ SG_  "U_P552_MY17_Gas_Tx" ENUM  "No","Yes";
BA_DEF_ SG_  "U_P552_MY17_Diesel_Tx" ENUM  "No","Yes";
BA_DEF_ SG_  "U_B515_MCA_MY17_Diesel_Tx" ENUM  "No","Yes";
BA_DEF_ SG_  "U_B515_MCA_MY17_Gas_Tx" ENUM  "No","Yes";
BA_DEF_ SG_  "U_B562LC_MY15_Diesel_Rx" ENUM  "No","Yes";
BA_DEF_ SG_  "U_B562LC_MY15_Gas_Rx" ENUM  "No","Yes";
BA_DEF_ SG_  "U_B479_MY17_Gas_Rx" ENUM  "No","Yes";
BA_DEF_ SG_  "U_B479_MY17_Diesel_Rx" ENUM  "No","Yes";
BA_DEF_ SG_  "U_CD4_MY17_Diesel_Rx" ENUM  "No","Yes";
BA_DEF_ SG_  "U_CD4_MY17_Gas_Rx" ENUM  "No","Yes";
BA_DEF_ SG_  "U_CD4_MY17_Hev_Rx" ENUM  "No","Yes";
BA_DEF_ SG_  "U_CD4_MY17_Phev_Rx" ENUM  "No","Yes";
BA_DEF_ SG_  "U_CD42_MY16_Diesel_Rx" ENUM  "No","Yes";
BA_DEF_ SG_  "U_CD42_MY16_Gas_Rx" ENUM  "No","Yes";
BA_DEF_ SG_  "U_B562LC_MY15_Diesel_Tx" ENUM  "No","Yes";
BA_DEF_ SG_  "U_B562LC_MY15_Gas_Tx" ENUM  "No","Yes";
BA_DEF_ SG_  "U_CD4_MY17_Diesel_Tx" ENUM  "No","Yes";
BA_DEF_ SG_  "U_CD4_MY17_Gas_Tx" ENUM  "No","Yes";
BA_DEF_ SG_  "U_CD4_MY17_Hev_Tx" ENUM  "No","Yes";
BA_DEF_ SG_  "U_CD4_MY17_Phev_Tx" ENUM  "No","Yes";
BA_DEF_ SG_  "U_CD42_MY16_Diesel_Tx" ENUM  "No","Yes";
BA_DEF_ SG_  "U_CD42_MY16_Gas_Tx" ENUM  "No","Yes";
BA_DEF_ SG_  "GenSigTimeoutTime_SECM" INT 0 100000;
BA_DEF_ BO_  "MessageGateway" ENUM  "No","Yes";
BA_DEF_ SG_  "U_CD42_MY15_Diesel_Rx" ENUM  "No","Yes";
BA_DEF_ SG_  "U_CD42_MY15_Gas_Rx" ENUM  "No","Yes";
BA_DEF_ SG_  "U_U502_MY16_Gas_Rx" ENUM  "No","Yes";
BA_DEF_ SG_  "U_P558_MY17_Gas_Rx" ENUM  "No","Yes";
BA_DEF_ SG_  "U_P558_MY17_Diesel_Rx" ENUM  "No","Yes";
BA_DEF_ SG_  "U_V36X_MY16_5_Diesel_Rx" ENUM  "No","Yes";
BA_DEF_ SG_  "U_CD42_MY15_Diesel_Tx" ENUM  "No","Yes";
BA_DEF_ SG_  "U_CD42_MY15_Gas_Tx" ENUM  "No","Yes";
BA_DEF_ SG_  "U_U502_MY16_Gas_Tx" ENUM  "No","Yes";
BA_DEF_ SG_  "U_P558_MY17_Gas_Tx" ENUM  "No","Yes";
BA_DEF_ SG_  "U_P558_MY17_Diesel_Tx" ENUM  "No","Yes";
BA_DEF_ SG_  "U_V36X_MY16_5_Diesel_Tx" ENUM  "No","Yes";
BA_DEF_ SG_  "GenSigTimeoutTime_VDM" INT 0 100000;
BA_DEF_ SG_  "GenSigTimeoutTime_ATCM" INT 0 100000;
BA_DEF_ SG_  "GenSigTimeoutTime_GENERIC" INT 0 100000;
BA_DEF_ SG_  "GenSigTimeoutTime_TRCM" INT 0 100000;
BA_DEF_ SG_  "GenSigTimeoutTime_GSM" INT 0 100000;
BA_DEF_ SG_  "GenSigTimeoutTime_FDSM" INT 0 100000;
BA_DEF_ SG_  "GenSigTimeoutTime_PCU" INT 0 100000;
BA_DEF_ SG_  "GenSigTimeoutTime_SASM" INT 0 100000;
BA_DEF_ SG_  "GenSigTimeoutTime_TCU_TBS" INT 0 100000;
BA_DEF_ SG_  "Gateway_ID" INT 0 0;
BA_DEF_ SG_  "GenSigTimeoutTime_IPMB" INT 0 100000;
BA_DEF_ SG_  "GenSigTimeoutTime__delete" INT 0 100000;
BA_DEF_ SG_  "GenSigTimeoutTime_PBM" INT 0 100000;
BA_DEF_ SG_  "GenSigTimeoutTime_TCCM" INT 0 100000;
BA_DEF_ SG_  "GenSigTimeoutTime_HUD" INT 0 100000;
BA_DEF_ SG_  "GenSigTimeoutTime_PSCM" INT 0 100000;
BA_DEF_ SG_  "GenSigTimeoutTime_SCCM" INT 0 100000;
BA_DEF_ SG_  "GenSigTimeoutTime_TBM" INT 0 100000;
BA_DEF_ SG_  "GenSigTimeoutTime_TSTR" INT 0 100000;
BA_DEF_ SG_  "GenSigTimeoutTime_IPMA" INT 0 100000;
BA_DEF_ SG_  "GenSigTimeoutTime_CCM" INT 0 100000;
BA_DEF_ SG_  "GenSigTimeoutTime_ABS_ESC" INT 0 100000;
BA_DEF_ SG_  "GenSigTimeoutTime_OCS" INT 0 100000;
BA_DEF_ SG_  "GenSigTimeoutTime_GWM" INT 0 100000;
BA_DEF_ SG_  "GenSigTimeoutTime_RCM" INT 0 100000;
BA_DEF_ BO_  "FrameGatewayMS1" HEX 0 1407;
BA_DEF_ BO_  "FrameGatewayHS3" HEX 0 1407;
BA_DEF_ BO_  "FrameGatewayHS1" HEX 0 1407;
BA_DEF_ BO_  "NetworkInitialization" ENUM  "No","Yes";
BA_DEF_ BO_  "FrameGatewayId" HEX 0 1407;
BA_DEF_ BO_  "EventRateOfChange" INT 10 10000;
BA_DEF_ BO_  "GenMsgStartDelayTime" INT 0 10000;
BA_DEF_ BO_  "GenMsgNrOfRepetition" INT 0 100;
BA_DEF_ BO_  "GenMsgDelayTime" INT 0 1000;
BA_DEF_ BO_  "GenMsgCycleTime" INT 0 100000;
BA_DEF_ BO_  "GenMsgSendType" ENUM  "FixedPeriodic","Event","EnabledPeriodic","NotUsed","NotUsed","EventPeriodic","NotUsed","NotUsed","NoMsgSendType";
BA_DEF_ SG_  "U_CD4_MY14_Phev_Tx" ENUM  "No","Yes";
BA_DEF_ SG_  "U_CD4_MY14_Hev_Tx" ENUM  "No","Yes";
BA_DEF_ SG_  "U_CD4_MY14_Gas_Tx" ENUM  "No","Yes";
BA_DEF_ SG_  "U_CD4_MY14_Diesel_Tx" ENUM  "No","Yes";
BA_DEF_ SG_  "U_CD43_MY16_Gas_Tx" ENUM  "No","Yes";
BA_DEF_ SG_  "U_C490LC_MY15_Gas_Tx" ENUM  "No","Yes";
BA_DEF_ SG_  "U_UP375_MY15_Diesel_Tx" ENUM  "No","Yes";
BA_DEF_ SG_  "U_UP375_MY15_Gas_Tx" ENUM  "No","Yes";
BA_DEF_ SG_  "U_U502_MY15_Gas_Tx" ENUM  "No","Yes";
BA_DEF_ SG_  "U_B562LC_MY14_Gas_Tx" ENUM  "No","Yes";
BA_DEF_ SG_  "U_B562LC_MY14_Diesel_Tx" ENUM  "No","Yes";
BA_DEF_ SG_  "U_C489_MY14_Gas_Tx" ENUM  "No","Yes";
BA_DEF_ SG_  "U_S550_MY15_Gas_Tx" ENUM  "No","Yes";
BA_DEF_ SG_  "U_P552_MY15_Gas_Tx" ENUM  "No","Yes";
BA_DEF_ SG_  "U_CD42_MY14_Gas_Tx" ENUM  "No","Yes";
BA_DEF_ SG_  "U_CD42_MY14_Diesel_Tx" ENUM  "No","Yes";
BA_DEF_ SG_  "U_CD4_MY13_Phev_Tx" ENUM  "No","Yes";
BA_DEF_ SG_  "U_CD4_MY13_Hev_Tx" ENUM  "No","Yes";
BA_DEF_ SG_  "U_CD4_MY13_Gas_Tx" ENUM  "No","Yes";
BA_DEF_ SG_  "U_CD4_MY13_Diesel_Tx" ENUM  "No","Yes";
BA_DEF_ SG_  "U_CD4_MY14_Phev_Rx" ENUM  "No","Yes";
BA_DEF_ SG_  "U_CD4_MY14_Hev_Rx" ENUM  "No","Yes";
BA_DEF_ SG_  "U_CD4_MY14_Gas_Rx" ENUM  "No","Yes";
BA_DEF_ SG_  "U_CD4_MY14_Diesel_Rx" ENUM  "No","Yes";
BA_DEF_ SG_  "U_CD43_MY16_Gas_Rx" ENUM  "No","Yes";
BA_DEF_ SG_  "U_UP375_MY15_Diesel_Rx" ENUM  "No","Yes";
BA_DEF_ SG_  "U_UP375_MY15_Gas_Rx" ENUM  "No","Yes";
BA_DEF_ SG_  "U_B479_MY15_Gas_Rx" ENUM  "No","Yes";
BA_DEF_ SG_  "U_U502_MY15_Gas_Rx" ENUM  "No","Yes";
BA_DEF_ SG_  "U_B562LC_MY14_Gas_Rx" ENUM  "No","Yes";
BA_DEF_ SG_  "U_B562LC_MY14_Diesel_Rx" ENUM  "No","Yes";
BA_DEF_ SG_  "U_C489_MY14_Gas_Rx" ENUM  "No","Yes";
BA_DEF_ SG_  "U_S550_MY15_Gas_Rx" ENUM  "No","Yes";
BA_DEF_ SG_  "U_P552_MY15_Gas_Rx" ENUM  "No","Yes";
BA_DEF_ SG_  "U_CD42_MY14_Gas_Rx" ENUM  "No","Yes";
BA_DEF_ SG_  "U_CD42_MY14_Diesel_Rx" ENUM  "No","Yes";
BA_DEF_ SG_  "U_CD4_MY13_Phev_Rx" ENUM  "No","Yes";
BA_DEF_ SG_  "U_CD4_MY13_Hev_Rx" ENUM  "No","Yes";
BA_DEF_ SG_  "U_CD4_MY13_Gas_Rx" ENUM  "No","Yes";
BA_DEF_ SG_  "U_CD4_MY13_Diesel_Rx" ENUM  "No","Yes";
BA_DEF_ SG_  "ContentDependant" ENUM  "No","Yes";
BA_DEF_ SG_  "GenSigStartValue" INT 0 1000000000;
BA_DEF_ SG_  "UsedOnPgmDBC" ENUM  "No","Yes";
BA_DEF_ SG_  "CrossOver_LIN" ENUM  "No","Yes";
BA_DEF_ SG_  "CrossOver_InfoCAN" ENUM  "No","Yes";
BA_DEF_ SG_  "WakeupSignal" ENUM  "No","Yes";
BA_DEF_ SG_  "FMC_SIG_SSPEC" STRING ;
BA_DEF_ SG_  "GenSigMissingSourceValue" INT 0 1000000000;
BA_DEF_ SG_  "GenSigSendType" ENUM  "Cyclic","OnWrite","vector_leerstring","OnChange","vector_leerstring","IfActive","vector_leerstring","NoSigSendType";
BA_DEF_ BO_  "NmAsrMessage" ENUM  "No","Yes";
BA_DEF_ BO_  "TpApplType" STRING ;
BA_DEF_ BO_  "DiagState" ENUM  "No","Yes";
BA_DEF_ BO_  "DiagRequest" ENUM  "No","Yes";
BA_DEF_ BO_  "DiagResponse" ENUM  "No","Yes";
BA_DEF_ BO_  "GenMsgILSupport" ENUM  "No","Yes";
BA_DEF_DEF_  "U_UP375_MY19_Gas_Rx" "No";
BA_DEF_DEF_  "U_UP375_MY19_Diesel_Rx" "No";
BA_DEF_DEF_  "U_V36X_MY19_Rx" "No";
BA_DEF_DEF_  "U_UP375_MY19_Gas_Tx" "No";
BA_DEF_DEF_  "U_UP375_MY19_Diesel_Tx" "No";
BA_DEF_DEF_  "U_V36X_MY19_Tx" "No";
BA_DEF_DEF_  "U_UP375_MY18_Gas_Rx" "No";
BA_DEF_DEF_  "U_UP375_MY18_Diesel_Rx" "No";
BA_DEF_DEF_  "U_V36X_MY18_5_Gas_Rx" "No";
BA_DEF_DEF_  "U_V36X_MY18_5_Hev_Rx" "No";
BA_DEF_DEF_  "U_UP375_MY18_Gas_Tx" "No";
BA_DEF_DEF_  "U_UP375_MY18_Diesel_Tx" "No";
BA_DEF_DEF_  "U_V36X_MY18_5_Gas_Tx" "No";
BA_DEF_DEF_  "U_V36X_MY18_5_Hev_Tx" "No";
BA_DEF_DEF_  "GenSigTimeoutTime_HCM_HS2" 5000;
BA_DEF_DEF_  "U_V36X_MY19_5_Diesel_Rx" "No";
BA_DEF_DEF_  "U_V363E_N_MY19_5_20_Gas_Rx" "No";
BA_DEF_DEF_  "U_V363E_N_MY19_5_20_Diesel_Rx" "No";
BA_DEF_DEF_  "U_CD42_MY19_Diesel_Rx" "No";
BA_DEF_DEF_  "U_CD42_MY19_Gas_Rx" "No";
BA_DEF_DEF_  "U_V36X_MY19_5_Diesel_Tx" "No";
BA_DEF_DEF_  "U_V363E_N_MY19_5_20_Gas_Tx" "No";
BA_DEF_DEF_  "U_V363E_N_MY19_5_20_Diesel_Tx" "No";
BA_DEF_DEF_  "U_CD42_MY19_Diesel_Tx" "No";
BA_DEF_DEF_  "U_CD42_MY19_Gas_Tx" "No";
BA_DEF_DEF_  "FrameGatewayNetworkold" "None";
BA_DEF_DEF_  "U_B562_MY18_Gas_Rx" "No";
BA_DEF_DEF_  "U_C490_MY18_Diesel_Rx" "No";
BA_DEF_DEF_  "U_C490_MY18_Gas_Rx" "No";
BA_DEF_DEF_  "U_V408_MY18_Gas_Rx" "No";
BA_DEF_DEF_  "U_V408_MY18_Diesel_Rx" "No";
BA_DEF_DEF_  "U_V36X_MY18_5_Diesel_Rx" "No";
BA_DEF_DEF_  "U_V408_MY18_Gas_Tx" "No";
BA_DEF_DEF_  "U_V408_MY18_Diesel_Tx" "No";
BA_DEF_DEF_  "U_V36X_MY18_5_Diesel_Tx" "No";
BA_DEF_DEF_  "U_P552_MY18_5_Gas_Tx" "No";
BA_DEF_DEF_  "U_P552_MY18_5_Diesel_Tx" "No";
BA_DEF_DEF_  "U_U502_MY17_Gas_Rx" "No";
BA_DEF_DEF_  "U_S550_MY18_Gas_Rx" "No";
BA_DEF_DEF_  "U_U502_MY17_Gas_Tx" "No";
BA_DEF_DEF_  "U_S550_MY18_Gas_Tx" "No";
BA_DEF_DEF_  "GenSigTimeoutTime_ATCM_FFSM" 5000;
BA_DEF_DEF_  "GenSigTimeoutTime_ATCM_DMSM" 5000;
BA_DEF_DEF_  "U_C489_MY17_Gas_Rx" "No";
BA_DEF_DEF_  "U_P552_MY18_Gas_Rx" "No";
BA_DEF_DEF_  "U_U55x_MY18_Gas_Rx" "No";
BA_DEF_DEF_  "U_C489_MY17_Gas_Tx" "No";
BA_DEF_DEF_  "U_P552_MY18_Gas_Tx" "No";
BA_DEF_DEF_  "U_U55x_MY18_Gas_Tx" "No";
BA_DEF_DEF_  "FrameGatewayNetwork" "NONE";
BA_DEF_DEF_  "U_CD43_MY17_Gas_Rx" "No";
BA_DEF_DEF_  "U_P552_MY17_Gas_Rx" "No";
BA_DEF_DEF_  "U_P552_MY17_Diesel_Rx" "No";
BA_DEF_DEF_  "U_B515_MCA_MY17_Diesel_Rx" "No";
BA_DEF_DEF_  "U_B515_MCA_MY17_Gas_Rx" "No";
BA_DEF_DEF_  "U_CD43_MY17_Gas_Tx" "No";
BA_DEF_DEF_  "U_P552_MY17_Gas_Tx" "No";
BA_DEF_DEF_  "U_P552_MY17_Diesel_Tx" "No";
BA_DEF_DEF_  "U_B515_MCA_MY17_Diesel_Tx" "No";
BA_DEF_DEF_  "U_B515_MCA_MY17_Gas_Tx" "No";
BA_DEF_DEF_  "U_B562LC_MY15_Diesel_Rx" "No";
BA_DEF_DEF_  "U_B562LC_MY15_Gas_Rx" "No";
BA_DEF_DEF_  "U_B479_MY17_Gas_Rx" "No";
BA_DEF_DEF_  "U_B479_MY17_Diesel_Rx" "No";
BA_DEF_DEF_  "U_CD4_MY17_Diesel_Rx" "No";
BA_DEF_DEF_  "U_CD4_MY17_Gas_Rx" "No";
BA_DEF_DEF_  "U_CD4_MY17_Hev_Rx" "No";
BA_DEF_DEF_  "U_CD4_MY17_Phev_Rx" "No";
BA_DEF_DEF_  "U_CD42_MY16_Diesel_Rx" "No";
BA_DEF_DEF_  "U_CD42_MY16_Gas_Rx" "No";
BA_DEF_DEF_  "U_B562LC_MY15_Diesel_Tx" "No";
BA_DEF_DEF_  "U_B562LC_MY15_Gas_Tx" "No";
BA_DEF_DEF_  "U_CD4_MY17_Diesel_Tx" "No";
BA_DEF_DEF_  "U_CD4_MY17_Gas_Tx" "No";
BA_DEF_DEF_  "U_CD4_MY17_Hev_Tx" "No";
BA_DEF_DEF_  "U_CD4_MY17_Phev_Tx" "No";
BA_DEF_DEF_  "U_CD42_MY16_Diesel_Tx" "No";
BA_DEF_DEF_  "U_CD42_MY16_Gas_Tx" "No";
BA_DEF_DEF_  "GenSigTimeoutTime_SECM" 5000;
BA_DEF_DEF_  "MessageGateway" "No";
BA_DEF_DEF_  "U_CD42_MY15_Diesel_Rx" "No";
BA_DEF_DEF_  "U_CD42_MY15_Gas_Rx" "No";
BA_DEF_DEF_  "U_U502_MY16_Gas_Rx" "No";
BA_DEF_DEF_  "U_P558_MY17_Gas_Rx" "No";
BA_DEF_DEF_  "U_P558_MY17_Diesel_Rx" "No";
BA_DEF_DEF_  "U_V36X_MY16_5_Diesel_Rx" "No";
BA_DEF_DEF_  "U_CD42_MY15_Diesel_Tx" "No";
BA_DEF_DEF_  "U_CD42_MY15_Gas_Tx" "No";
BA_DEF_DEF_  "U_U502_MY16_Gas_Tx" "No";
BA_DEF_DEF_  "U_P558_MY17_Gas_Tx" "No";
BA_DEF_DEF_  "U_P558_MY17_Diesel_Tx" "No";
BA_DEF_DEF_  "U_V36X_MY16_5_Diesel_Tx" "No";
BA_DEF_DEF_  "GenSigTimeoutTime_VDM" 5000;
BA_DEF_DEF_  "GenSigTimeoutTime_ATCM" 5000;
BA_DEF_DEF_  "GenSigTimeoutTime_GENERIC" 5000;
BA_DEF_DEF_  "GenSigTimeoutTime_TRCM" 5000;
BA_DEF_DEF_  "GenSigTimeoutTime_GSM" 5000;
BA_DEF_DEF_  "GenSigTimeoutTime_FDSM" 5000;
BA_DEF_DEF_  "GenSigTimeoutTime_PCU" 5000;
BA_DEF_DEF_  "GenSigTimeoutTime_SASM" 5000;
BA_DEF_DEF_  "GenSigTimeoutTime_TCU_TBS" 5000;
BA_DEF_DEF_  "Gateway_ID" 0;
BA_DEF_DEF_  "GenSigTimeoutTime_IPMB" 5000;
BA_DEF_DEF_  "GenSigTimeoutTime__delete" 5000;
BA_DEF_DEF_  "GenSigTimeoutTime_PBM" 5000;
BA_DEF_DEF_  "GenSigTimeoutTime_TCCM" 5000;
BA_DEF_DEF_  "GenSigTimeoutTime_HUD" 5000;
BA_DEF_DEF_  "GenSigTimeoutTime_PSCM" 5000;
BA_DEF_DEF_  "GenSigTimeoutTime_SCCM" 5000;
BA_DEF_DEF_  "GenSigTimeoutTime_TBM" 5000;
BA_DEF_DEF_  "GenSigTimeoutTime_TSTR" 5000;
BA_DEF_DEF_  "GenSigTimeoutTime_IPMA" 5000;
BA_DEF_DEF_  "GenSigTimeoutTime_CCM" 5000;
BA_DEF_DEF_  "GenSigTimeoutTime_ABS_ESC" 5000;
BA_DEF_DEF_  "GenSigTimeoutTime_OCS" 5000;
BA_DEF_DEF_  "GenSigTimeoutTime_GWM" 5000;
BA_DEF_DEF_  "GenSigTimeoutTime_RCM" 5000;
BA_DEF_DEF_  "FrameGatewayMS1" 0;
BA_DEF_DEF_  "FrameGatewayHS3" 0;
BA_DEF_DEF_  "FrameGatewayHS1" 0;
BA_DEF_DEF_  "NetworkInitialization" "No";
BA_DEF_DEF_  "FrameGatewayId" 0;
BA_DEF_DEF_  "EventRateOfChange" 10000;
BA_DEF_DEF_  "GenMsgStartDelayTime" 0;
BA_DEF_DEF_  "GenMsgNrOfRepetition" 1;
BA_DEF_DEF_  "GenMsgDelayTime" 20;
BA_DEF_DEF_  "GenMsgCycleTime" 0;
BA_DEF_DEF_  "GenMsgSendType" "NoMsgSendType";
BA_DEF_DEF_  "U_CD4_MY14_Phev_Tx" "No";
BA_DEF_DEF_  "U_CD4_MY14_Hev_Tx" "No";
BA_DEF_DEF_  "U_CD4_MY14_Gas_Tx" "No";
BA_DEF_DEF_  "U_CD4_MY14_Diesel_Tx" "No";
BA_DEF_DEF_  "U_CD43_MY16_Gas_Tx" "No";
BA_DEF_DEF_  "U_C490LC_MY15_Gas_Tx" "No";
BA_DEF_DEF_  "U_UP375_MY15_Diesel_Tx" "No";
BA_DEF_DEF_  "U_UP375_MY15_Gas_Tx" "No";
BA_DEF_DEF_  "U_U502_MY15_Gas_Tx" "No";
BA_DEF_DEF_  "U_B562LC_MY14_Gas_Tx" "No";
BA_DEF_DEF_  "U_B562LC_MY14_Diesel_Tx" "No";
BA_DEF_DEF_  "U_C489_MY14_Gas_Tx" "No";
BA_DEF_DEF_  "U_S550_MY15_Gas_Tx" "No";
BA_DEF_DEF_  "U_P552_MY15_Gas_Tx" "No";
BA_DEF_DEF_  "U_CD42_MY14_Gas_Tx" "No";
BA_DEF_DEF_  "U_CD42_MY14_Diesel_Tx" "No";
BA_DEF_DEF_  "U_CD4_MY13_Phev_Tx" "No";
BA_DEF_DEF_  "U_CD4_MY13_Hev_Tx" "No";
BA_DEF_DEF_  "U_CD4_MY13_Gas_Tx" "No";
BA_DEF_DEF_  "U_CD4_MY13_Diesel_Tx" "No";
BA_DEF_DEF_  "U_CD4_MY14_Phev_Rx" "No";
BA_DEF_DEF_  "U_CD4_MY14_Hev_Rx" "No";
BA_DEF_DEF_  "U_CD4_MY14_Gas_Rx" "No";
BA_DEF_DEF_  "U_CD4_MY14_Diesel_Rx" "No";
BA_DEF_DEF_  "U_CD43_MY16_Gas_Rx" "No";
BA_DEF_DEF_  "U_UP375_MY15_Diesel_Rx" "No";
BA_DEF_DEF_  "U_UP375_MY15_Gas_Rx" "No";
BA_DEF_DEF_  "U_B479_MY15_Gas_Rx" "No";
BA_DEF_DEF_  "U_U502_MY15_Gas_Rx" "No";
BA_DEF_DEF_  "U_B562LC_MY14_Gas_Rx" "No";
BA_DEF_DEF_  "U_B562LC_MY14_Diesel_Rx" "No";
BA_DEF_DEF_  "U_C489_MY14_Gas_Rx" "No";
BA_DEF_DEF_  "U_S550_MY15_Gas_Rx" "No";
BA_DEF_DEF_  "U_P552_MY15_Gas_Rx" "No";
BA_DEF_DEF_  "U_CD42_MY14_Gas_Rx" "No";
BA_DEF_DEF_  "U_CD42_MY14_Diesel_Rx" "No";
BA_DEF_DEF_  "U_CD4_MY13_Phev_Rx" "No";
BA_DEF_DEF_  "U_CD4_MY13_Hev_Rx" "No";
BA_DEF_DEF_  "U_CD4_MY13_Gas_Rx" "No";
BA_DEF_DEF_  "U_CD4_MY13_Diesel_Rx" "No";
BA_DEF_DEF_  "ContentDependant" "No";
BA_DEF_DEF_  "GenSigStartValue" 0;
BA_DEF_DEF_  "UsedOnPgmDBC" "Yes";
BA_DEF_DEF_  "CrossOver_LIN" "No";
BA_DEF_DEF_  "CrossOver_InfoCAN" "No";
BA_DEF_DEF_  "WakeupSignal" "No";
BA_DEF_DEF_  "FMC_SIG_SSPEC" "Unknown";
BA_DEF_DEF_  "GenSigMissingSourceValue" 0;
BA_DEF_DEF_  "GenSigSendType" "NoSigSendType";
BA_DEF_DEF_  "NmAsrMessage" "No";
BA_DEF_DEF_  "TpApplType" "";
BA_DEF_DEF_  "DiagState" "No";
BA_DEF_DEF_  "DiagRequest" "No";
BA_DEF_DEF_  "DiagResponse" "No";
BA_DEF_DEF_  "GenMsgILSupport" "Yes";
BA_ "NetworkInitialization" BO_ 938 1;
BA_ "FrameGatewayId" BO_ 938 938;
BA_ "FrameGatewayHS1" BO_ 938 938;
BA_ "FrameGatewayNetwork" BO_ 938 "HS1_CAN";
BA_ "GenMsgILSupport" BO_ 1441 0;
BA_ "NmAsrMessage" BO_ 1441 1;
BA_ "GenMsgSendType" BO_ 1441 1;
BA_ "GenMsgILSupport" BO_ 1472 0;
BA_ "NmAsrMessage" BO_ 1472 1;
BA_ "GenMsgSendType" BO_ 1472 1;
BA_ "GenMsgSendType" BO_ 1186 0;
BA_ "GenMsgCycleTime" BO_ 1186 100;
BA_ "GenMsgSendType" BO_ 1042 0;
BA_ "GenMsgCycleTime" BO_ 1042 50;
BA_ "GenMsgSendType" BO_ 1090 0;
BA_ "GenMsgCycleTime" BO_ 1090 50;
BA_ "NetworkInitialization" BO_ 1090 1;
BA_ "GenMsgILSupport" BO_ 1977 0;
BA_ "DiagResponse" BO_ 1977 1;
BA_ "GenMsgSendType" BO_ 1977 1;
BA_ "GenMsgDelayTime" BO_ 1977 0;
BA_ "GenMsgILSupport" BO_ 1969 0;
BA_ "DiagRequest" BO_ 1969 1;
BA_ "GenMsgSendType" BO_ 1969 1;
BA_ "GenMsgDelayTime" BO_ 1969 0;
BA_ "GenMsgSendType" BO_ 1006 5;
BA_ "GenMsgCycleTime" BO_ 1006 1000;
BA_ "GenMsgSendType" BO_ 1200 0;
BA_ "GenMsgCycleTime" BO_ 1200 20;
BA_ "GenMsgDelayTime" BO_ 1200 10;
BA_ "NetworkInitialization" BO_ 1200 1;
BA_ "GenMsgSendType" BO_ 673 5;
BA_ "GenMsgCycleTime" BO_ 673 100;
BA_ "FrameGatewayId" BO_ 845 845;
BA_ "FrameGatewayMS1" BO_ 845 845;
BA_ "FrameGatewayNetwork" BO_ 845 "MS1_CAN";
BA_ "FrameGatewayId" BO_ 850 850;
BA_ "FrameGatewayMS1" BO_ 850 850;
BA_ "FrameGatewayNetwork" BO_ 850 "MS1_CAN";
BA_ "FrameGatewayId" BO_ 935 935;
BA_ "FrameGatewayMS1" BO_ 935 935;
BA_ "FrameGatewayNetwork" BO_ 935 "MS1_CAN";
BA_ "FrameGatewayId" BO_ 934 934;
BA_ "FrameGatewayMS1" BO_ 934 934;
BA_ "FrameGatewayNetwork" BO_ 934 "MS1_CAN";
BA_ "FrameGatewayId" BO_ 1091 1091;
BA_ "FrameGatewayMS1" BO_ 1091 1091;
BA_ "FrameGatewayNetwork" BO_ 1091 "MS1_CAN";
BA_ "FrameGatewayId" BO_ 1068 1068;
BA_ "FrameGatewayHS1" BO_ 1068 1068;
BA_ "NetworkInitialization" BO_ 1068 1;
BA_ "FrameGatewayNetwork" BO_ 1068 "HS1_CAN";
BA_ "GenMsgSendType" BO_ 611 0;
BA_ "GenMsgCycleTime" BO_ 611 100;
BA_ "NetworkInitialization" BO_ 611 1;
BA_ "FrameGatewayId" BO_ 578 578;
BA_ "FrameGatewayHS1" BO_ 578 578;
BA_ "FrameGatewayNetwork" BO_ 578 "HS1_CAN";
BA_ "FrameGatewayId" BO_ 560 560;
BA_ "FrameGatewayHS1" BO_ 560 560;
BA_ "FrameGatewayNetwork" BO_ 560 "HS1_CAN";
BA_ "NetworkInitialization" BO_ 560 1;
BA_ "FrameGatewayId" BO_ 359 359;
BA_ "FrameGatewayHS1" BO_ 359 359;
BA_ "FrameGatewayNetwork" BO_ 359 "HS1_CAN";
BA_ "GenMsgDelayTime" BO_ 357 10;
BA_ "FrameGatewayId" BO_ 357 357;
BA_ "FrameGatewayHS1" BO_ 357 357;
BA_ "FrameGatewayNetwork" BO_ 357 "HS1_CAN";
BA_ "NetworkInitialization" BO_ 357 1;
BA_ "GenMsgILSupport" BO_ 1461 0;
BA_ "NmAsrMessage" BO_ 1461 1;
BA_ "GenMsgSendType" BO_ 1461 1;
BA_ "GenMsgSendType" BO_ 390 0;
BA_ "GenMsgCycleTime" BO_ 390 20;
BA_ "GenMsgDelayTime" BO_ 390 10;
BA_ "NetworkInitialization" BO_ 1072 1;
BA_ "GenMsgSendType" BO_ 1072 5;
BA_ "GenMsgCycleTime" BO_ 1072 100;
BA_ "GenMsgStartDelayTime" BO_ 1072 200;
BA_ "GenMsgSendType" BO_ 1058 0;
BA_ "GenMsgCycleTime" BO_ 1058 100;
BA_ "GenMsgILSupport" BO_ 1430 0;
BA_ "NmAsrMessage" BO_ 1430 1;
BA_ "GenMsgSendType" BO_ 1430 1;
BA_ "GenMsgILSupport" BO_ 1889 0;
BA_ "DiagRequest" BO_ 1889 1;
BA_ "GenMsgSendType" BO_ 1889 1;
BA_ "GenMsgDelayTime" BO_ 1889 0;
BA_ "GenMsgILSupport" BO_ 1897 0;
BA_ "DiagResponse" BO_ 1897 1;
BA_ "GenMsgSendType" BO_ 1897 1;
BA_ "GenMsgDelayTime" BO_ 1897 0;
BA_ "FrameGatewayId" BO_ 512 512;
BA_ "FrameGatewayHS1" BO_ 512 512;
BA_ "FrameGatewayNetwork" BO_ 512 "HS1_CAN";
BA_ "GenMsgDelayTime" BO_ 936 10;
BA_ "FrameGatewayId" BO_ 936 936;
BA_ "FrameGatewayHS1" BO_ 936 936;
BA_ "FrameGatewayNetwork" BO_ 936 "HS1_CAN";
BA_ "GenMsgSendType" BO_ 76 5;
BA_ "GenMsgCycleTime" BO_ 76 100;
BA_ "GenMsgDelayTime" BO_ 76 10;
BA_ "GenMsgStartDelayTime" BO_ 76 70;
BA_ "GenMsgSendType" BO_ 120 0;
BA_ "GenMsgCycleTime" BO_ 120 20;
BA_ "GenMsgDelayTime" BO_ 120 10;
BA_ "GenMsgILSupport" BO_ 1665 0;
BA_ "TpApplType" BO_ 1665 "DiagUUDTResponse";
BA_ "GenMsgSendType" BO_ 1665 1;
BA_ "GenMsgILSupport" BO_ 2041 0;
BA_ "GenMsgSendType" BO_ 2041 1;
BA_ "GenMsgDelayTime" BO_ 2041 0;
BA_ "GenMsgILSupport" BO_ 1438 0;
BA_ "NmAsrMessage" BO_ 1438 1;
BA_ "GenMsgSendType" BO_ 1438 1;
BA_ "FrameGatewayId" BO_ 1034 1034;
BA_ "FrameGatewayHS1" BO_ 1034 1034;
BA_ "FrameGatewayNetwork" BO_ 1034 "HS1_CAN";
BA_ "U_P558_MY17_Diesel_Rx" SG_ 938 PrkAidMsgTxt_D_Rq 1;
BA_ "U_P558_MY17_Gas_Rx" SG_ 938 PrkAidMsgTxt_D_Rq 1;
BA_ "U_CD42_MY15_Gas_Rx" SG_ 938 PrkAidMsgTxt_D_Rq 1;
BA_ "U_CD42_MY15_Diesel_Rx" SG_ 938 PrkAidMsgTxt_D_Rq 1;
BA_ "CrossOver_InfoCAN" SG_ 938 PrkAidMsgTxt_D_Rq 1;
BA_ "CrossOver_InfoCAN" SG_ 938 PrkAidSnsFrSide_D_Stat 1;
BA_ "U_P552_MY15_Gas_Rx" SG_ 938 PrkAidSnsFrSide_D_Stat 1;
BA_ "CrossOver_InfoCAN" SG_ 938 PrkAidSnsFrCrnr_D_Stat 1;
BA_ "U_P552_MY15_Gas_Rx" SG_ 938 PrkAidSnsFrCrnr_D_Stat 1;
BA_ "CrossOver_InfoCAN" SG_ 938 PrkAidSnsFrCntr_D_Stat 1;
BA_ "U_P552_MY15_Gas_Rx" SG_ 938 PrkAidSnsFrCntr_D_Stat 1;
BA_ "CrossOver_InfoCAN" SG_ 938 PrkAidSnsFlSide_D_Stat 1;
BA_ "U_P552_MY15_Gas_Rx" SG_ 938 PrkAidSnsFlSide_D_Stat 1;
BA_ "CrossOver_InfoCAN" SG_ 938 PrkAidSnsFlCrnr_D_Stat 1;
BA_ "U_P552_MY15_Gas_Rx" SG_ 938 PrkAidSnsFlCrnr_D_Stat 1;
BA_ "CrossOver_InfoCAN" SG_ 938 PrkAidSnsFlCntr_D_Stat 1;
BA_ "U_P552_MY15_Gas_Rx" SG_ 938 PrkAidSnsFlCntr_D_Stat 1;
BA_ "GenSigSendType" SG_ 1441 TCCM_AutoSar_Network_Mgmt 3;
BA_ "U_P552_MY15_Gas_Rx" SG_ 1441 TCCM_AutoSar_Network_Mgmt 1;
BA_ "U_P552_MY15_Gas_Tx" SG_ 1441 TCCM_AutoSar_Network_Mgmt 1;
BA_ "U_UP375_MY15_Gas_Tx" SG_ 1441 TCCM_AutoSar_Network_Mgmt 1;
BA_ "U_UP375_MY15_Diesel_Tx" SG_ 1441 TCCM_AutoSar_Network_Mgmt 1;
BA_ "GenSigSendType" SG_ 1472 TBM_AutoSar_Network_Mgmt 3;
BA_ "U_P552_MY15_Gas_Rx" SG_ 1472 TBM_AutoSar_Network_Mgmt 1;
BA_ "U_P552_MY15_Gas_Tx" SG_ 1472 TBM_AutoSar_Network_Mgmt 1;
BA_ "U_P552_MY15_Gas_Tx" SG_ 1186 RearDiffLckMsg_D_Rq 1;
BA_ "U_UP375_MY15_Gas_Tx" SG_ 1186 RearDiffLckMsg_D_Rq 1;
BA_ "U_UP375_MY15_Diesel_Tx" SG_ 1186 RearDiffLckMsg_D_Rq 1;
BA_ "U_P552_MY15_Gas_Tx" SG_ 1186 RearDiffLckLamp_D_Rq 1;
BA_ "U_UP375_MY15_Gas_Tx" SG_ 1186 RearDiffLckLamp_D_Rq 1;
BA_ "U_UP375_MY15_Diesel_Tx" SG_ 1186 RearDiffLckLamp_D_Rq 1;
BA_ "U_P552_MY18_Gas_Tx" SG_ 1186 RearDiffLckLamp_D_Rq 1;
BA_ "U_P552_MY17_Gas_Tx" SG_ 1186 RearDiffLckLamp_D_Rq 1;
BA_ "U_V36X_MY16_5_Diesel_Tx" SG_ 1186 RearDiffLckLamp_D_Rq 1;
BA_ "U_P558_MY17_Diesel_Tx" SG_ 1186 RearDiffLckLamp_D_Rq 1;
BA_ "U_P558_MY17_Gas_Tx" SG_ 1186 RearDiffLckLamp_D_Rq 1;
BA_ "U_U55x_MY18_Gas_Rx" SG_ 1186 RearDiffLckLamp_D_Rq 1;
BA_ "U_P552_MY18_Gas_Rx" SG_ 1186 RearDiffLckLamp_D_Rq 1;
BA_ "U_P552_MY17_Gas_Rx" SG_ 1186 RearDiffLckLamp_D_Rq 1;
BA_ "U_P552_MY15_Gas_Rx" SG_ 1186 RearDiffLck_Tq_Actl 1;
BA_ "U_UP375_MY15_Gas_Rx" SG_ 1186 RearDiffLck_Tq_Actl 1;
BA_ "U_UP375_MY15_Diesel_Rx" SG_ 1186 RearDiffLck_Tq_Actl 1;
BA_ "U_P552_MY15_Gas_Tx" SG_ 1186 RearDiffLck_Tq_Actl 1;
BA_ "U_UP375_MY15_Gas_Tx" SG_ 1186 RearDiffLck_Tq_Actl 1;
BA_ "U_UP375_MY15_Diesel_Tx" SG_ 1186 RearDiffLck_Tq_Actl 1;
BA_ "U_P552_MY15_Gas_Rx" SG_ 1186 RearDiffFalt_D_Stat 1;
BA_ "U_UP375_MY15_Gas_Rx" SG_ 1186 RearDiffFalt_D_Stat 1;
BA_ "U_UP375_MY15_Diesel_Rx" SG_ 1186 RearDiffFalt_D_Stat 1;
BA_ "U_P552_MY15_Gas_Tx" SG_ 1186 RearDiffFalt_D_Stat 1;
BA_ "U_UP375_MY15_Gas_Tx" SG_ 1186 RearDiffFalt_D_Stat 1;
BA_ "U_UP375_MY15_Diesel_Tx" SG_ 1186 RearDiffFalt_D_Stat 1;
BA_ "CrossOver_InfoCAN" SG_ 1186 LsdSrvcRqd_B_Rq 1;
BA_ "U_P552_MY15_Gas_Tx" SG_ 1186 LsdSrvcRqd_B_Rq 1;
BA_ "U_UP375_MY15_Gas_Tx" SG_ 1186 LsdSrvcRqd_B_Rq 1;
BA_ "U_UP375_MY15_Diesel_Tx" SG_ 1186 LsdSrvcRqd_B_Rq 1;
BA_ "GenSigStartValue" SG_ 1042 VehRol_An_Dsply 64;
BA_ "U_P552_MY15_Gas_Tx" SG_ 1042 VehRol_An_Dsply 1;
BA_ "U_UP375_MY15_Gas_Tx" SG_ 1042 VehRol_An_Dsply 1;
BA_ "U_UP375_MY15_Diesel_Tx" SG_ 1042 VehRol_An_Dsply 1;
BA_ "GenSigStartValue" SG_ 1042 VehPtch_An_Dsply 64;
BA_ "U_P552_MY15_Gas_Tx" SG_ 1042 VehPtch_An_Dsply 1;
BA_ "U_UP375_MY15_Gas_Tx" SG_ 1042 VehPtch_An_Dsply 1;
BA_ "U_UP375_MY15_Diesel_Tx" SG_ 1042 VehPtch_An_Dsply 1;
BA_ "U_P552_MY15_Gas_Rx" SG_ 1042 TrlrBrk_Pc_Rq 1;
BA_ "U_P552_MY15_Gas_Tx" SG_ 1042 TrlrBrk_Pc_Rq 1;
BA_ "U_UP375_MY15_Gas_Tx" SG_ 1042 TrlrBrk_Pc_Rq 1;
BA_ "U_UP375_MY15_Diesel_Tx" SG_ 1042 TrlrBrk_Pc_Rq 1;
BA_ "U_P552_MY17_Gas_Tx" SG_ 1090 TrlrTrgtPtrnId_No_Calc 1;
BA_ "U_P552_MY15_Gas_Rx" SG_ 1090 TrlrAnCalib_Pc_Actl 1;
BA_ "U_P552_MY15_Gas_Rx" SG_ 1090 TrlrAid_D_Stat 1;
BA_ "U_P552_MY15_Gas_Tx" SG_ 1090 TrlrAid_D_Stat 1;
BA_ "U_U502_MY15_Gas_Tx" SG_ 1090 TrlrAid_D_Stat 1;
BA_ "U_CD43_MY16_Gas_Tx" SG_ 1090 TrlrAid_D_Stat 1;
BA_ "GenSigStartValue" SG_ 1090 TrlrAid_AnRate_Actl 500;
BA_ "U_P552_MY15_Gas_Rx" SG_ 1090 TrlrAid_AnRate_Actl 1;
BA_ "U_P552_MY15_Gas_Tx" SG_ 1090 TrlrAid_AnRate_Actl 1;
BA_ "U_U502_MY15_Gas_Tx" SG_ 1090 TrlrAid_AnRate_Actl 1;
BA_ "U_CD43_MY16_Gas_Tx" SG_ 1090 TrlrAid_AnRate_Actl 1;
BA_ "GenSigStartValue" SG_ 1090 TrlrAid2_An_Actl 900;
BA_ "U_P552_MY15_Gas_Rx" SG_ 1090 TrlrAid2_An_Actl 1;
BA_ "GenSigSendType" SG_ 1977 TesterPhysicalResIPMB 3;
BA_ "U_P552_MY15_Gas_Tx" SG_ 1977 TesterPhysicalResIPMB 1;
BA_ "U_U502_MY15_Gas_Tx" SG_ 1977 TesterPhysicalResIPMB 1;
BA_ "U_CD43_MY16_Gas_Tx" SG_ 1977 TesterPhysicalResIPMB 1;
BA_ "GenSigSendType" SG_ 1969 TesterPhysicalReqIPMB 3;
BA_ "U_P552_MY15_Gas_Rx" SG_ 1969 TesterPhysicalReqIPMB 1;
BA_ "U_U502_MY15_Gas_Rx" SG_ 1969 TesterPhysicalReqIPMB 1;
BA_ "U_CD43_MY16_Gas_Rx" SG_ 1969 TesterPhysicalReqIPMB 1;
BA_ "CrossOver_InfoCAN" SG_ 1006 PersIndexIpmb_D_Actl 1;
BA_ "GenSigStartValue" SG_ 1006 PersIndexIpmb_D_Actl 4;
BA_ "GenSigSendType" SG_ 1006 PersIndexIpmb_D_Actl 3;
BA_ "U_P552_MY15_Gas_Tx" SG_ 1006 PersIndexIpmb_D_Actl 1;
BA_ "CrossOver_InfoCAN" SG_ 1006 FeatNoIpmbActl 1;
BA_ "GenSigSendType" SG_ 1006 FeatNoIpmbActl 3;
BA_ "U_P552_MY15_Gas_Tx" SG_ 1006 FeatNoIpmbActl 1;
BA_ "CrossOver_InfoCAN" SG_ 1006 FeatConfigIpmbActl 1;
BA_ "GenSigSendType" SG_ 1006 FeatConfigIpmbActl 3;
BA_ "U_P552_MY15_Gas_Tx" SG_ 1006 FeatConfigIpmbActl 1;
BA_ "U_V408_MY18_Diesel_Tx" SG_ 1200 BrkAutoHold_D_Stat 1;
BA_ "U_V408_MY18_Gas_Tx" SG_ 1200 BrkAutoHold_D_Stat 1;
BA_ "U_U55x_MY18_Gas_Tx" SG_ 1200 BrkAutoHold_D_Stat 1;
BA_ "U_CD43_MY17_Gas_Tx" SG_ 1200 BrkAutoHold_D_Stat 1;
BA_ "U_CD42_MY16_Gas_Tx" SG_ 1200 BrkAutoHold_D_Stat 1;
BA_ "U_CD42_MY16_Diesel_Tx" SG_ 1200 BrkAutoHold_D_Stat 1;
BA_ "U_C489_MY17_Gas_Tx" SG_ 1200 BrkAutoHold_D_Stat 1;
BA_ "U_CD4_MY17_Phev_Tx" SG_ 1200 BrkAutoHold_D_Stat 1;
BA_ "U_CD4_MY17_Hev_Tx" SG_ 1200 BrkAutoHold_D_Stat 1;
BA_ "U_CD4_MY17_Gas_Tx" SG_ 1200 BrkAutoHold_D_Stat 1;
BA_ "U_CD4_MY17_Diesel_Tx" SG_ 1200 BrkAutoHold_D_Stat 1;
BA_ "U_CD43_MY16_Gas_Tx" SG_ 1200 BrkAutoHold_D_Stat 1;
BA_ "GenSigStartValue" SG_ 1200 BrkBstrVac_P_Actl 127;
BA_ "U_CD4_MY13_Diesel_Tx" SG_ 1200 BrkBstrVac_P_Actl 1;
BA_ "U_CD4_MY13_Gas_Tx" SG_ 1200 BrkBstrVac_P_Actl 1;
BA_ "U_CD4_MY13_Hev_Tx" SG_ 1200 BrkBstrVac_P_Actl 1;
BA_ "U_CD4_MY13_Phev_Tx" SG_ 1200 BrkBstrVac_P_Actl 1;
BA_ "U_CD42_MY14_Diesel_Tx" SG_ 1200 BrkBstrVac_P_Actl 1;
BA_ "U_CD42_MY14_Gas_Tx" SG_ 1200 BrkBstrVac_P_Actl 1;
BA_ "U_P552_MY15_Gas_Tx" SG_ 1200 BrkBstrVac_P_Actl 1;
BA_ "U_S550_MY15_Gas_Tx" SG_ 1200 BrkBstrVac_P_Actl 1;
BA_ "U_C489_MY14_Gas_Tx" SG_ 1200 BrkBstrVac_P_Actl 1;
BA_ "U_B562LC_MY14_Diesel_Tx" SG_ 1200 BrkBstrVac_P_Actl 1;
BA_ "U_B562LC_MY14_Gas_Tx" SG_ 1200 BrkBstrVac_P_Actl 1;
BA_ "U_U502_MY15_Gas_Tx" SG_ 1200 BrkBstrVac_P_Actl 1;
BA_ "U_UP375_MY15_Gas_Tx" SG_ 1200 BrkBstrVac_P_Actl 1;
BA_ "U_UP375_MY15_Diesel_Tx" SG_ 1200 BrkBstrVac_P_Actl 1;
BA_ "U_CD43_MY16_Gas_Tx" SG_ 1200 BrkBstrVac_P_Actl 1;
BA_ "GenSigStartValue" SG_ 1200 YawStabilityIndex 256;
BA_ "U_CD4_MY13_Phev_Rx" SG_ 1200 YawStabilityIndex 1;
BA_ "U_CD42_MY14_Diesel_Rx" SG_ 1200 YawStabilityIndex 1;
BA_ "U_CD42_MY14_Gas_Rx" SG_ 1200 YawStabilityIndex 1;
BA_ "U_P552_MY15_Gas_Rx" SG_ 1200 YawStabilityIndex 1;
BA_ "U_C489_MY14_Gas_Rx" SG_ 1200 YawStabilityIndex 1;
BA_ "U_U502_MY15_Gas_Rx" SG_ 1200 YawStabilityIndex 1;
BA_ "U_CD43_MY16_Gas_Rx" SG_ 1200 YawStabilityIndex 1;
BA_ "U_CD4_MY13_Diesel_Tx" SG_ 1200 YawStabilityIndex 1;
BA_ "U_CD4_MY13_Gas_Tx" SG_ 1200 YawStabilityIndex 1;
BA_ "U_CD4_MY13_Hev_Tx" SG_ 1200 YawStabilityIndex 1;
BA_ "U_CD4_MY13_Phev_Tx" SG_ 1200 YawStabilityIndex 1;
BA_ "U_CD42_MY14_Diesel_Tx" SG_ 1200 YawStabilityIndex 1;
BA_ "U_CD42_MY14_Gas_Tx" SG_ 1200 YawStabilityIndex 1;
BA_ "U_P552_MY15_Gas_Tx" SG_ 1200 YawStabilityIndex 1;
BA_ "U_S550_MY15_Gas_Tx" SG_ 1200 YawStabilityIndex 1;
BA_ "U_C489_MY14_Gas_Tx" SG_ 1200 YawStabilityIndex 1;
BA_ "U_B562LC_MY14_Diesel_Tx" SG_ 1200 YawStabilityIndex 1;
BA_ "U_B562LC_MY14_Gas_Tx" SG_ 1200 YawStabilityIndex 1;
BA_ "U_U502_MY15_Gas_Tx" SG_ 1200 YawStabilityIndex 1;
BA_ "U_UP375_MY15_Gas_Tx" SG_ 1200 YawStabilityIndex 1;
BA_ "U_UP375_MY15_Diesel_Tx" SG_ 1200 YawStabilityIndex 1;
BA_ "U_CD43_MY16_Gas_Tx" SG_ 1200 YawStabilityIndex 1;
BA_ "U_P552_MY15_Gas_Rx" SG_ 1200 BrkTot_Tq_RqDrv 1;
BA_ "U_CD4_MY13_Diesel_Tx" SG_ 1200 BrkTot_Tq_RqDrv 1;
BA_ "U_CD4_MY13_Gas_Tx" SG_ 1200 BrkTot_Tq_RqDrv 1;
BA_ "U_CD4_MY13_Hev_Tx" SG_ 1200 BrkTot_Tq_RqDrv 1;
BA_ "U_CD4_MY13_Phev_Tx" SG_ 1200 BrkTot_Tq_RqDrv 1;
BA_ "U_CD42_MY14_Diesel_Tx" SG_ 1200 BrkTot_Tq_RqDrv 1;
BA_ "U_CD42_MY14_Gas_Tx" SG_ 1200 BrkTot_Tq_RqDrv 1;
BA_ "U_P552_MY15_Gas_Tx" SG_ 1200 BrkTot_Tq_RqDrv 1;
BA_ "U_S550_MY15_Gas_Tx" SG_ 1200 BrkTot_Tq_RqDrv 1;
BA_ "U_C489_MY14_Gas_Tx" SG_ 1200 BrkTot_Tq_RqDrv 1;
BA_ "U_B562LC_MY14_Diesel_Tx" SG_ 1200 BrkTot_Tq_RqDrv 1;
BA_ "U_B562LC_MY14_Gas_Tx" SG_ 1200 BrkTot_Tq_RqDrv 1;
BA_ "U_U502_MY15_Gas_Tx" SG_ 1200 BrkTot_Tq_RqDrv 1;
BA_ "U_UP375_MY15_Gas_Tx" SG_ 1200 BrkTot_Tq_RqDrv 1;
BA_ "U_UP375_MY15_Diesel_Tx" SG_ 1200 BrkTot_Tq_RqDrv 1;
BA_ "U_CD43_MY16_Gas_Tx" SG_ 1200 BrkTot_Tq_RqDrv 1;
BA_ "U_P552_MY15_Gas_Rx" SG_ 1200 BrkTotTqRqDrv_No_Cnt 1;
BA_ "U_CD4_MY13_Diesel_Tx" SG_ 1200 BrkTotTqRqDrv_No_Cnt 1;
BA_ "U_CD4_MY13_Gas_Tx" SG_ 1200 BrkTotTqRqDrv_No_Cnt 1;
BA_ "U_CD4_MY13_Hev_Tx" SG_ 1200 BrkTotTqRqDrv_No_Cnt 1;
BA_ "U_CD4_MY13_Phev_Tx" SG_ 1200 BrkTotTqRqDrv_No_Cnt 1;
BA_ "U_CD42_MY14_Diesel_Tx" SG_ 1200 BrkTotTqRqDrv_No_Cnt 1;
BA_ "U_CD42_MY14_Gas_Tx" SG_ 1200 BrkTotTqRqDrv_No_Cnt 1;
BA_ "U_P552_MY15_Gas_Tx" SG_ 1200 BrkTotTqRqDrv_No_Cnt 1;
BA_ "U_S550_MY15_Gas_Tx" SG_ 1200 BrkTotTqRqDrv_No_Cnt 1;
BA_ "U_C489_MY14_Gas_Tx" SG_ 1200 BrkTotTqRqDrv_No_Cnt 1;
BA_ "U_B562LC_MY14_Diesel_Tx" SG_ 1200 BrkTotTqRqDrv_No_Cnt 1;
BA_ "U_B562LC_MY14_Gas_Tx" SG_ 1200 BrkTotTqRqDrv_No_Cnt 1;
BA_ "U_U502_MY15_Gas_Tx" SG_ 1200 BrkTotTqRqDrv_No_Cnt 1;
BA_ "U_UP375_MY15_Gas_Tx" SG_ 1200 BrkTotTqRqDrv_No_Cnt 1;
BA_ "U_UP375_MY15_Diesel_Tx" SG_ 1200 BrkTotTqRqDrv_No_Cnt 1;
BA_ "U_CD43_MY16_Gas_Tx" SG_ 1200 BrkTotTqRqDrv_No_Cnt 1;
BA_ "U_P552_MY15_Gas_Rx" SG_ 1200 BrkTotTqRqDrv_No_Cs 1;
BA_ "U_CD4_MY13_Diesel_Tx" SG_ 1200 BrkTotTqRqDrv_No_Cs 1;
BA_ "U_CD4_MY13_Gas_Tx" SG_ 1200 BrkTotTqRqDrv_No_Cs 1;
BA_ "U_CD4_MY13_Hev_Tx" SG_ 1200 BrkTotTqRqDrv_No_Cs 1;
BA_ "U_CD4_MY13_Phev_Tx" SG_ 1200 BrkTotTqRqDrv_No_Cs 1;
BA_ "U_CD42_MY14_Diesel_Tx" SG_ 1200 BrkTotTqRqDrv_No_Cs 1;
BA_ "U_CD42_MY14_Gas_Tx" SG_ 1200 BrkTotTqRqDrv_No_Cs 1;
BA_ "U_P552_MY15_Gas_Tx" SG_ 1200 BrkTotTqRqDrv_No_Cs 1;
BA_ "U_S550_MY15_Gas_Tx" SG_ 1200 BrkTotTqRqDrv_No_Cs 1;
BA_ "U_C489_MY14_Gas_Tx" SG_ 1200 BrkTotTqRqDrv_No_Cs 1;
BA_ "U_B562LC_MY14_Diesel_Tx" SG_ 1200 BrkTotTqRqDrv_No_Cs 1;
BA_ "U_B562LC_MY14_Gas_Tx" SG_ 1200 BrkTotTqRqDrv_No_Cs 1;
BA_ "U_U502_MY15_Gas_Tx" SG_ 1200 BrkTotTqRqDrv_No_Cs 1;
BA_ "U_UP375_MY15_Gas_Tx" SG_ 1200 BrkTotTqRqDrv_No_Cs 1;
BA_ "U_UP375_MY15_Diesel_Tx" SG_ 1200 BrkTotTqRqDrv_No_Cs 1;
BA_ "U_CD43_MY16_Gas_Tx" SG_ 1200 BrkTotTqRqDrv_No_Cs 1;
BA_ "CrossOver_InfoCAN" SG_ 673 ICI_Coding_BtnID_D 1;
BA_ "GenSigSendType" SG_ 673 ICI_Coding_BtnID_D 3;
BA_ "U_CD4_MY13_Diesel_Tx" SG_ 673 ICI_Coding_BtnID_D 1;
BA_ "U_CD4_MY13_Gas_Tx" SG_ 673 ICI_Coding_BtnID_D 1;
BA_ "U_CD4_MY13_Hev_Tx" SG_ 673 ICI_Coding_BtnID_D 1;
BA_ "U_CD4_MY13_Phev_Tx" SG_ 673 ICI_Coding_BtnID_D 1;
BA_ "U_CD42_MY14_Diesel_Tx" SG_ 673 ICI_Coding_BtnID_D 1;
BA_ "U_CD42_MY14_Gas_Tx" SG_ 673 ICI_Coding_BtnID_D 1;
BA_ "U_P552_MY15_Gas_Tx" SG_ 673 ICI_Coding_BtnID_D 1;
BA_ "U_S550_MY15_Gas_Tx" SG_ 673 ICI_Coding_BtnID_D 1;
BA_ "U_C489_MY14_Gas_Tx" SG_ 673 ICI_Coding_BtnID_D 1;
BA_ "U_U502_MY15_Gas_Tx" SG_ 673 ICI_Coding_BtnID_D 1;
BA_ "U_UP375_MY15_Gas_Tx" SG_ 673 ICI_Coding_BtnID_D 1;
BA_ "U_UP375_MY15_Diesel_Tx" SG_ 673 ICI_Coding_BtnID_D 1;
BA_ "U_CD43_MY16_Gas_Tx" SG_ 673 ICI_Coding_BtnID_D 1;
BA_ "CrossOver_InfoCAN" SG_ 673 ICI_Coding_BtnID_C 1;
BA_ "GenSigSendType" SG_ 673 ICI_Coding_BtnID_C 3;
BA_ "U_CD4_MY13_Diesel_Tx" SG_ 673 ICI_Coding_BtnID_C 1;
BA_ "U_CD4_MY13_Gas_Tx" SG_ 673 ICI_Coding_BtnID_C 1;
BA_ "U_CD4_MY13_Hev_Tx" SG_ 673 ICI_Coding_BtnID_C 1;
BA_ "U_CD4_MY13_Phev_Tx" SG_ 673 ICI_Coding_BtnID_C 1;
BA_ "U_CD42_MY14_Diesel_Tx" SG_ 673 ICI_Coding_BtnID_C 1;
BA_ "U_CD42_MY14_Gas_Tx" SG_ 673 ICI_Coding_BtnID_C 1;
BA_ "U_P552_MY15_Gas_Tx" SG_ 673 ICI_Coding_BtnID_C 1;
BA_ "U_S550_MY15_Gas_Tx" SG_ 673 ICI_Coding_BtnID_C 1;
BA_ "U_C489_MY14_Gas_Tx" SG_ 673 ICI_Coding_BtnID_C 1;
BA_ "U_U502_MY15_Gas_Tx" SG_ 673 ICI_Coding_BtnID_C 1;
BA_ "U_UP375_MY15_Gas_Tx" SG_ 673 ICI_Coding_BtnID_C 1;
BA_ "U_UP375_MY15_Diesel_Tx" SG_ 673 ICI_Coding_BtnID_C 1;
BA_ "U_CD43_MY16_Gas_Tx" SG_ 673 ICI_Coding_BtnID_C 1;
BA_ "CrossOver_InfoCAN" SG_ 673 ICI_Coding_BtnID_B 1;
BA_ "GenSigSendType" SG_ 673 ICI_Coding_BtnID_B 3;
BA_ "U_CD4_MY13_Diesel_Tx" SG_ 673 ICI_Coding_BtnID_B 1;
BA_ "U_CD4_MY13_Gas_Tx" SG_ 673 ICI_Coding_BtnID_B 1;
BA_ "U_CD4_MY13_Hev_Tx" SG_ 673 ICI_Coding_BtnID_B 1;
BA_ "U_CD4_MY13_Phev_Tx" SG_ 673 ICI_Coding_BtnID_B 1;
BA_ "U_CD42_MY14_Diesel_Tx" SG_ 673 ICI_Coding_BtnID_B 1;
BA_ "U_CD42_MY14_Gas_Tx" SG_ 673 ICI_Coding_BtnID_B 1;
BA_ "U_P552_MY15_Gas_Tx" SG_ 673 ICI_Coding_BtnID_B 1;
BA_ "U_S550_MY15_Gas_Tx" SG_ 673 ICI_Coding_BtnID_B 1;
BA_ "U_C489_MY14_Gas_Tx" SG_ 673 ICI_Coding_BtnID_B 1;
BA_ "U_U502_MY15_Gas_Tx" SG_ 673 ICI_Coding_BtnID_B 1;
BA_ "U_UP375_MY15_Gas_Tx" SG_ 673 ICI_Coding_BtnID_B 1;
BA_ "U_UP375_MY15_Diesel_Tx" SG_ 673 ICI_Coding_BtnID_B 1;
BA_ "U_CD43_MY16_Gas_Tx" SG_ 673 ICI_Coding_BtnID_B 1;
BA_ "CrossOver_InfoCAN" SG_ 673 ICI_Coding_BtnID_A 1;
BA_ "GenSigSendType" SG_ 673 ICI_Coding_BtnID_A 3;
BA_ "U_CD4_MY13_Diesel_Tx" SG_ 673 ICI_Coding_BtnID_A 1;
BA_ "U_CD4_MY13_Gas_Tx" SG_ 673 ICI_Coding_BtnID_A 1;
BA_ "U_CD4_MY13_Hev_Tx" SG_ 673 ICI_Coding_BtnID_A 1;
BA_ "U_CD4_MY13_Phev_Tx" SG_ 673 ICI_Coding_BtnID_A 1;
BA_ "U_CD42_MY14_Diesel_Tx" SG_ 673 ICI_Coding_BtnID_A 1;
BA_ "U_CD42_MY14_Gas_Tx" SG_ 673 ICI_Coding_BtnID_A 1;
BA_ "U_P552_MY15_Gas_Tx" SG_ 673 ICI_Coding_BtnID_A 1;
BA_ "U_S550_MY15_Gas_Tx" SG_ 673 ICI_Coding_BtnID_A 1;
BA_ "U_C489_MY14_Gas_Tx" SG_ 673 ICI_Coding_BtnID_A 1;
BA_ "U_U502_MY15_Gas_Tx" SG_ 673 ICI_Coding_BtnID_A 1;
BA_ "U_UP375_MY15_Gas_Tx" SG_ 673 ICI_Coding_BtnID_A 1;
BA_ "U_UP375_MY15_Diesel_Tx" SG_ 673 ICI_Coding_BtnID_A 1;
BA_ "U_CD43_MY16_Gas_Tx" SG_ 673 ICI_Coding_BtnID_A 1;
BA_ "CrossOver_InfoCAN" SG_ 673 ICI_BtnID_D 1;
BA_ "GenSigSendType" SG_ 673 ICI_BtnID_D 3;
BA_ "U_CD4_MY13_Diesel_Tx" SG_ 673 ICI_BtnID_D 1;
BA_ "U_CD4_MY13_Gas_Tx" SG_ 673 ICI_BtnID_D 1;
BA_ "U_CD4_MY13_Hev_Tx" SG_ 673 ICI_BtnID_D 1;
BA_ "U_CD4_MY13_Phev_Tx" SG_ 673 ICI_BtnID_D 1;
BA_ "U_CD42_MY14_Diesel_Tx" SG_ 673 ICI_BtnID_D 1;
BA_ "U_CD42_MY14_Gas_Tx" SG_ 673 ICI_BtnID_D 1;
BA_ "U_P552_MY15_Gas_Tx" SG_ 673 ICI_BtnID_D 1;
BA_ "U_S550_MY15_Gas_Tx" SG_ 673 ICI_BtnID_D 1;
BA_ "U_C489_MY14_Gas_Tx" SG_ 673 ICI_BtnID_D 1;
BA_ "U_U502_MY15_Gas_Tx" SG_ 673 ICI_BtnID_D 1;
BA_ "U_UP375_MY15_Gas_Tx" SG_ 673 ICI_BtnID_D 1;
BA_ "U_UP375_MY15_Diesel_Tx" SG_ 673 ICI_BtnID_D 1;
BA_ "U_CD43_MY16_Gas_Tx" SG_ 673 ICI_BtnID_D 1;
BA_ "CrossOver_InfoCAN" SG_ 673 ICI_BtnID_C 1;
BA_ "GenSigSendType" SG_ 673 ICI_BtnID_C 3;
BA_ "U_CD4_MY13_Diesel_Tx" SG_ 673 ICI_BtnID_C 1;
BA_ "U_CD4_MY13_Gas_Tx" SG_ 673 ICI_BtnID_C 1;
BA_ "U_CD4_MY13_Hev_Tx" SG_ 673 ICI_BtnID_C 1;
BA_ "U_CD4_MY13_Phev_Tx" SG_ 673 ICI_BtnID_C 1;
BA_ "U_CD42_MY14_Diesel_Tx" SG_ 673 ICI_BtnID_C 1;
BA_ "U_CD42_MY14_Gas_Tx" SG_ 673 ICI_BtnID_C 1;
BA_ "U_P552_MY15_Gas_Tx" SG_ 673 ICI_BtnID_C 1;
BA_ "U_S550_MY15_Gas_Tx" SG_ 673 ICI_BtnID_C 1;
BA_ "U_C489_MY14_Gas_Tx" SG_ 673 ICI_BtnID_C 1;
BA_ "U_U502_MY15_Gas_Tx" SG_ 673 ICI_BtnID_C 1;
BA_ "U_UP375_MY15_Gas_Tx" SG_ 673 ICI_BtnID_C 1;
BA_ "U_UP375_MY15_Diesel_Tx" SG_ 673 ICI_BtnID_C 1;
BA_ "U_CD43_MY16_Gas_Tx" SG_ 673 ICI_BtnID_C 1;
BA_ "CrossOver_InfoCAN" SG_ 673 ICI_BtnID_B 1;
BA_ "GenSigSendType" SG_ 673 ICI_BtnID_B 3;
BA_ "U_CD4_MY13_Diesel_Tx" SG_ 673 ICI_BtnID_B 1;
BA_ "U_CD4_MY13_Gas_Tx" SG_ 673 ICI_BtnID_B 1;
BA_ "U_CD4_MY13_Hev_Tx" SG_ 673 ICI_BtnID_B 1;
BA_ "U_CD4_MY13_Phev_Tx" SG_ 673 ICI_BtnID_B 1;
BA_ "U_CD42_MY14_Diesel_Tx" SG_ 673 ICI_BtnID_B 1;
BA_ "U_CD42_MY14_Gas_Tx" SG_ 673 ICI_BtnID_B 1;
BA_ "U_P552_MY15_Gas_Tx" SG_ 673 ICI_BtnID_B 1;
BA_ "U_S550_MY15_Gas_Tx" SG_ 673 ICI_BtnID_B 1;
BA_ "U_C489_MY14_Gas_Tx" SG_ 673 ICI_BtnID_B 1;
BA_ "U_U502_MY15_Gas_Tx" SG_ 673 ICI_BtnID_B 1;
BA_ "U_UP375_MY15_Gas_Tx" SG_ 673 ICI_BtnID_B 1;
BA_ "U_UP375_MY15_Diesel_Tx" SG_ 673 ICI_BtnID_B 1;
BA_ "U_CD43_MY16_Gas_Tx" SG_ 673 ICI_BtnID_B 1;
BA_ "CrossOver_InfoCAN" SG_ 673 ICI_BtnID_A 1;
BA_ "GenSigSendType" SG_ 673 ICI_BtnID_A 3;
BA_ "U_CD4_MY13_Diesel_Tx" SG_ 673 ICI_BtnID_A 1;
BA_ "U_CD4_MY13_Gas_Tx" SG_ 673 ICI_BtnID_A 1;
BA_ "U_CD4_MY13_Hev_Tx" SG_ 673 ICI_BtnID_A 1;
BA_ "U_CD4_MY13_Phev_Tx" SG_ 673 ICI_BtnID_A 1;
BA_ "U_CD42_MY14_Diesel_Tx" SG_ 673 ICI_BtnID_A 1;
BA_ "U_CD42_MY14_Gas_Tx" SG_ 673 ICI_BtnID_A 1;
BA_ "U_P552_MY15_Gas_Tx" SG_ 673 ICI_BtnID_A 1;
BA_ "U_S550_MY15_Gas_Tx" SG_ 673 ICI_BtnID_A 1;
BA_ "U_C489_MY14_Gas_Tx" SG_ 673 ICI_BtnID_A 1;
BA_ "U_U502_MY15_Gas_Tx" SG_ 673 ICI_BtnID_A 1;
BA_ "U_UP375_MY15_Gas_Tx" SG_ 673 ICI_BtnID_A 1;
BA_ "U_UP375_MY15_Diesel_Tx" SG_ 673 ICI_BtnID_A 1;
BA_ "U_CD43_MY16_Gas_Tx" SG_ 673 ICI_BtnID_A 1;
BA_ "CrossOver_InfoCAN" SG_ 845 StmsLmbrPsgr_D_Stat 1;
BA_ "U_CD4_MY13_Diesel_Rx" SG_ 845 StmsLmbrPsgr_D_Stat 1;
BA_ "U_CD4_MY13_Gas_Rx" SG_ 845 StmsLmbrPsgr_D_Stat 1;
BA_ "U_CD4_MY13_Hev_Rx" SG_ 845 StmsLmbrPsgr_D_Stat 1;
BA_ "U_CD4_MY13_Phev_Rx" SG_ 845 StmsLmbrPsgr_D_Stat 1;
BA_ "U_CD42_MY14_Diesel_Rx" SG_ 845 StmsLmbrPsgr_D_Stat 1;
BA_ "U_CD42_MY14_Gas_Rx" SG_ 845 StmsLmbrPsgr_D_Stat 1;
BA_ "U_P552_MY15_Gas_Rx" SG_ 845 StmsLmbrPsgr_D_Stat 1;
BA_ "U_U502_MY15_Gas_Rx" SG_ 845 StmsLmbrPsgr_D_Stat 1;
BA_ "U_CD43_MY16_Gas_Rx" SG_ 845 StmsLmbrPsgr_D_Stat 1;
BA_ "U_CD4_MY14_Diesel_Rx" SG_ 845 StmsLmbrPsgr_D_Stat 1;
BA_ "U_CD4_MY14_Gas_Rx" SG_ 845 StmsLmbrPsgr_D_Stat 1;
BA_ "U_CD4_MY14_Hev_Rx" SG_ 845 StmsLmbrPsgr_D_Stat 1;
BA_ "U_CD4_MY14_Phev_Rx" SG_ 845 StmsLmbrPsgr_D_Stat 1;
BA_ "GenSigTimeoutTime_OCS" SG_ 845 StmsLmbrPsgr_D_Stat 6000;
BA_ "CrossOver_InfoCAN" SG_ 845 StmsCshnPsgr_D_Stat 1;
BA_ "U_CD4_MY13_Diesel_Rx" SG_ 845 StmsCshnPsgr_D_Stat 1;
BA_ "U_CD4_MY13_Gas_Rx" SG_ 845 StmsCshnPsgr_D_Stat 1;
BA_ "U_CD4_MY13_Hev_Rx" SG_ 845 StmsCshnPsgr_D_Stat 1;
BA_ "U_CD4_MY13_Phev_Rx" SG_ 845 StmsCshnPsgr_D_Stat 1;
BA_ "U_CD42_MY14_Diesel_Rx" SG_ 845 StmsCshnPsgr_D_Stat 1;
BA_ "U_CD42_MY14_Gas_Rx" SG_ 845 StmsCshnPsgr_D_Stat 1;
BA_ "U_P552_MY15_Gas_Rx" SG_ 845 StmsCshnPsgr_D_Stat 1;
BA_ "U_U502_MY15_Gas_Rx" SG_ 845 StmsCshnPsgr_D_Stat 1;
BA_ "U_CD43_MY16_Gas_Rx" SG_ 845 StmsCshnPsgr_D_Stat 1;
BA_ "U_CD4_MY14_Diesel_Rx" SG_ 845 StmsCshnPsgr_D_Stat 1;
BA_ "U_CD4_MY14_Gas_Rx" SG_ 845 StmsCshnPsgr_D_Stat 1;
BA_ "U_CD4_MY14_Hev_Rx" SG_ 845 StmsCshnPsgr_D_Stat 1;
BA_ "U_CD4_MY14_Phev_Rx" SG_ 845 StmsCshnPsgr_D_Stat 1;
BA_ "GenSigTimeoutTime_OCS" SG_ 845 StmsCshnPsgr_D_Stat 6000;
BA_ "CrossOver_InfoCAN" SG_ 845 SeatSwtchPsgr_B_Stat 1;
BA_ "U_CD4_MY13_Diesel_Rx" SG_ 845 SeatSwtchPsgr_B_Stat 1;
BA_ "U_CD4_MY13_Gas_Rx" SG_ 845 SeatSwtchPsgr_B_Stat 1;
BA_ "U_CD4_MY13_Hev_Rx" SG_ 845 SeatSwtchPsgr_B_Stat 1;
BA_ "U_CD4_MY13_Phev_Rx" SG_ 845 SeatSwtchPsgr_B_Stat 1;
BA_ "U_CD42_MY14_Diesel_Rx" SG_ 845 SeatSwtchPsgr_B_Stat 1;
BA_ "U_CD42_MY14_Gas_Rx" SG_ 845 SeatSwtchPsgr_B_Stat 1;
BA_ "U_P552_MY15_Gas_Rx" SG_ 845 SeatSwtchPsgr_B_Stat 1;
BA_ "U_U502_MY15_Gas_Rx" SG_ 845 SeatSwtchPsgr_B_Stat 1;
BA_ "U_CD43_MY16_Gas_Rx" SG_ 845 SeatSwtchPsgr_B_Stat 1;
BA_ "U_CD4_MY14_Diesel_Rx" SG_ 845 SeatSwtchPsgr_B_Stat 1;
BA_ "U_CD4_MY14_Gas_Rx" SG_ 845 SeatSwtchPsgr_B_Stat 1;
BA_ "U_CD4_MY14_Hev_Rx" SG_ 845 SeatSwtchPsgr_B_Stat 1;
BA_ "U_CD4_MY14_Phev_Rx" SG_ 845 SeatSwtchPsgr_B_Stat 1;
BA_ "GenSigTimeoutTime_OCS" SG_ 845 SeatSwtchPsgr_B_Stat 6000;
BA_ "CrossOver_InfoCAN" SG_ 845 SeatPPsgr_B_Stat 1;
BA_ "U_CD4_MY13_Diesel_Rx" SG_ 845 SeatPPsgr_B_Stat 1;
BA_ "U_CD4_MY13_Gas_Rx" SG_ 845 SeatPPsgr_B_Stat 1;
BA_ "U_CD4_MY13_Hev_Rx" SG_ 845 SeatPPsgr_B_Stat 1;
BA_ "U_CD4_MY13_Phev_Rx" SG_ 845 SeatPPsgr_B_Stat 1;
BA_ "U_CD42_MY14_Diesel_Rx" SG_ 845 SeatPPsgr_B_Stat 1;
BA_ "U_CD42_MY14_Gas_Rx" SG_ 845 SeatPPsgr_B_Stat 1;
BA_ "U_P552_MY15_Gas_Rx" SG_ 845 SeatPPsgr_B_Stat 1;
BA_ "U_U502_MY15_Gas_Rx" SG_ 845 SeatPPsgr_B_Stat 1;
BA_ "U_CD43_MY16_Gas_Rx" SG_ 845 SeatPPsgr_B_Stat 1;
BA_ "U_CD4_MY14_Diesel_Rx" SG_ 845 SeatPPsgr_B_Stat 1;
BA_ "U_CD4_MY14_Gas_Rx" SG_ 845 SeatPPsgr_B_Stat 1;
BA_ "U_CD4_MY14_Hev_Rx" SG_ 845 SeatPPsgr_B_Stat 1;
BA_ "U_CD4_MY14_Phev_Rx" SG_ 845 SeatPPsgr_B_Stat 1;
BA_ "GenSigTimeoutTime_OCS" SG_ 845 SeatPPsgr_B_Stat 6000;
BA_ "CrossOver_InfoCAN" SG_ 845 SeatFnPsgr_D_Stat 1;
BA_ "U_CD4_MY13_Diesel_Rx" SG_ 845 SeatFnPsgr_D_Stat 1;
BA_ "U_CD4_MY13_Gas_Rx" SG_ 845 SeatFnPsgr_D_Stat 1;
BA_ "U_CD4_MY13_Hev_Rx" SG_ 845 SeatFnPsgr_D_Stat 1;
BA_ "U_CD4_MY13_Phev_Rx" SG_ 845 SeatFnPsgr_D_Stat 1;
BA_ "U_CD42_MY14_Diesel_Rx" SG_ 845 SeatFnPsgr_D_Stat 1;
BA_ "U_CD42_MY14_Gas_Rx" SG_ 845 SeatFnPsgr_D_Stat 1;
BA_ "U_P552_MY15_Gas_Rx" SG_ 845 SeatFnPsgr_D_Stat 1;
BA_ "U_U502_MY15_Gas_Rx" SG_ 845 SeatFnPsgr_D_Stat 1;
BA_ "U_CD43_MY16_Gas_Rx" SG_ 845 SeatFnPsgr_D_Stat 1;
BA_ "U_CD4_MY14_Diesel_Rx" SG_ 845 SeatFnPsgr_D_Stat 1;
BA_ "U_CD4_MY14_Gas_Rx" SG_ 845 SeatFnPsgr_D_Stat 1;
BA_ "U_CD4_MY14_Hev_Rx" SG_ 845 SeatFnPsgr_D_Stat 1;
BA_ "U_CD4_MY14_Phev_Rx" SG_ 845 SeatFnPsgr_D_Stat 1;
BA_ "GenSigTimeoutTime_OCS" SG_ 845 SeatFnPsgr_D_Stat 6000;
BA_ "CrossOver_InfoCAN" SG_ 845 PsgrMemFeedback_Rsp 1;
BA_ "CrossOver_InfoCAN" SG_ 850 SeatBlLoPsgr_Pc_Actl2 1;
BA_ "GenSigStartValue" SG_ 850 SeatBlLoPsgr_Pc_Actl2 127;
BA_ "CrossOver_InfoCAN" SG_ 850 SeatCshnPsgrRR_Pc_Actl 1;
BA_ "GenSigStartValue" SG_ 850 SeatCshnPsgrRR_Pc_Actl 127;
BA_ "U_CD4_MY13_Diesel_Rx" SG_ 850 SeatCshnPsgrRR_Pc_Actl 1;
BA_ "U_CD4_MY13_Gas_Rx" SG_ 850 SeatCshnPsgrRR_Pc_Actl 1;
BA_ "U_CD4_MY13_Hev_Rx" SG_ 850 SeatCshnPsgrRR_Pc_Actl 1;
BA_ "U_CD4_MY13_Phev_Rx" SG_ 850 SeatCshnPsgrRR_Pc_Actl 1;
BA_ "U_CD42_MY14_Diesel_Rx" SG_ 850 SeatCshnPsgrRR_Pc_Actl 1;
BA_ "U_CD42_MY14_Gas_Rx" SG_ 850 SeatCshnPsgrRR_Pc_Actl 1;
BA_ "U_P552_MY15_Gas_Rx" SG_ 850 SeatCshnPsgrRR_Pc_Actl 1;
BA_ "U_U502_MY15_Gas_Rx" SG_ 850 SeatCshnPsgrRR_Pc_Actl 1;
BA_ "U_CD43_MY16_Gas_Rx" SG_ 850 SeatCshnPsgrRR_Pc_Actl 1;
BA_ "U_CD4_MY14_Diesel_Rx" SG_ 850 SeatCshnPsgrRR_Pc_Actl 1;
BA_ "U_CD4_MY14_Gas_Rx" SG_ 850 SeatCshnPsgrRR_Pc_Actl 1;
BA_ "U_CD4_MY14_Hev_Rx" SG_ 850 SeatCshnPsgrRR_Pc_Actl 1;
BA_ "U_CD4_MY14_Phev_Rx" SG_ 850 SeatCshnPsgrRR_Pc_Actl 1;
BA_ "GenSigTimeoutTime_OCS" SG_ 850 SeatCshnPsgrRR_Pc_Actl 6000;
BA_ "CrossOver_InfoCAN" SG_ 850 SeatCshnPsgrRL_Pc_Actl 1;
BA_ "GenSigStartValue" SG_ 850 SeatCshnPsgrRL_Pc_Actl 127;
BA_ "U_CD4_MY13_Diesel_Rx" SG_ 850 SeatCshnPsgrRL_Pc_Actl 1;
BA_ "U_CD4_MY13_Gas_Rx" SG_ 850 SeatCshnPsgrRL_Pc_Actl 1;
BA_ "U_CD4_MY13_Hev_Rx" SG_ 850 SeatCshnPsgrRL_Pc_Actl 1;
BA_ "U_CD4_MY13_Phev_Rx" SG_ 850 SeatCshnPsgrRL_Pc_Actl 1;
BA_ "U_CD42_MY14_Diesel_Rx" SG_ 850 SeatCshnPsgrRL_Pc_Actl 1;
BA_ "U_CD42_MY14_Gas_Rx" SG_ 850 SeatCshnPsgrRL_Pc_Actl 1;
BA_ "U_P552_MY15_Gas_Rx" SG_ 850 SeatCshnPsgrRL_Pc_Actl 1;
BA_ "U_U502_MY15_Gas_Rx" SG_ 850 SeatCshnPsgrRL_Pc_Actl 1;
BA_ "U_CD43_MY16_Gas_Rx" SG_ 850 SeatCshnPsgrRL_Pc_Actl 1;
BA_ "U_CD4_MY14_Diesel_Rx" SG_ 850 SeatCshnPsgrRL_Pc_Actl 1;
BA_ "U_CD4_MY14_Gas_Rx" SG_ 850 SeatCshnPsgrRL_Pc_Actl 1;
BA_ "U_CD4_MY14_Hev_Rx" SG_ 850 SeatCshnPsgrRL_Pc_Actl 1;
BA_ "U_CD4_MY14_Phev_Rx" SG_ 850 SeatCshnPsgrRL_Pc_Actl 1;
BA_ "GenSigTimeoutTime_OCS" SG_ 850 SeatCshnPsgrRL_Pc_Actl 6000;
BA_ "CrossOver_InfoCAN" SG_ 850 SeatCshnPsgrFR_Pc_Actl 1;
BA_ "GenSigStartValue" SG_ 850 SeatCshnPsgrFR_Pc_Actl 127;
BA_ "U_CD4_MY13_Diesel_Rx" SG_ 850 SeatCshnPsgrFR_Pc_Actl 1;
BA_ "U_CD4_MY13_Gas_Rx" SG_ 850 SeatCshnPsgrFR_Pc_Actl 1;
BA_ "U_CD4_MY13_Hev_Rx" SG_ 850 SeatCshnPsgrFR_Pc_Actl 1;
BA_ "U_CD4_MY13_Phev_Rx" SG_ 850 SeatCshnPsgrFR_Pc_Actl 1;
BA_ "U_CD42_MY14_Diesel_Rx" SG_ 850 SeatCshnPsgrFR_Pc_Actl 1;
BA_ "U_CD42_MY14_Gas_Rx" SG_ 850 SeatCshnPsgrFR_Pc_Actl 1;
BA_ "U_P552_MY15_Gas_Rx" SG_ 850 SeatCshnPsgrFR_Pc_Actl 1;
BA_ "U_U502_MY15_Gas_Rx" SG_ 850 SeatCshnPsgrFR_Pc_Actl 1;
BA_ "U_CD43_MY16_Gas_Rx" SG_ 850 SeatCshnPsgrFR_Pc_Actl 1;
BA_ "U_CD4_MY14_Diesel_Rx" SG_ 850 SeatCshnPsgrFR_Pc_Actl 1;
BA_ "U_CD4_MY14_Gas_Rx" SG_ 850 SeatCshnPsgrFR_Pc_Actl 1;
BA_ "U_CD4_MY14_Hev_Rx" SG_ 850 SeatCshnPsgrFR_Pc_Actl 1;
BA_ "U_CD4_MY14_Phev_Rx" SG_ 850 SeatCshnPsgrFR_Pc_Actl 1;
BA_ "GenSigTimeoutTime_OCS" SG_ 850 SeatCshnPsgrFR_Pc_Actl 6000;
BA_ "CrossOver_InfoCAN" SG_ 850 SeatCshnPsgrFL_Pc_Actl 1;
BA_ "GenSigStartValue" SG_ 850 SeatCshnPsgrFL_Pc_Actl 127;
BA_ "U_CD4_MY13_Diesel_Rx" SG_ 850 SeatCshnPsgrFL_Pc_Actl 1;
BA_ "U_CD4_MY13_Gas_Rx" SG_ 850 SeatCshnPsgrFL_Pc_Actl 1;
BA_ "U_CD4_MY13_Hev_Rx" SG_ 850 SeatCshnPsgrFL_Pc_Actl 1;
BA_ "U_CD4_MY13_Phev_Rx" SG_ 850 SeatCshnPsgrFL_Pc_Actl 1;
BA_ "U_CD42_MY14_Diesel_Rx" SG_ 850 SeatCshnPsgrFL_Pc_Actl 1;
BA_ "U_CD42_MY14_Gas_Rx" SG_ 850 SeatCshnPsgrFL_Pc_Actl 1;
BA_ "U_P552_MY15_Gas_Rx" SG_ 850 SeatCshnPsgrFL_Pc_Actl 1;
BA_ "U_U502_MY15_Gas_Rx" SG_ 850 SeatCshnPsgrFL_Pc_Actl 1;
BA_ "U_CD43_MY16_Gas_Rx" SG_ 850 SeatCshnPsgrFL_Pc_Actl 1;
BA_ "U_CD4_MY14_Diesel_Rx" SG_ 850 SeatCshnPsgrFL_Pc_Actl 1;
BA_ "U_CD4_MY14_Gas_Rx" SG_ 850 SeatCshnPsgrFL_Pc_Actl 1;
BA_ "U_CD4_MY14_Hev_Rx" SG_ 850 SeatCshnPsgrFL_Pc_Actl 1;
BA_ "U_CD4_MY14_Phev_Rx" SG_ 850 SeatCshnPsgrFL_Pc_Actl 1;
BA_ "GenSigTimeoutTime_OCS" SG_ 850 SeatCshnPsgrFL_Pc_Actl 6000;
BA_ "CrossOver_InfoCAN" SG_ 935 Side_Detect_R_Illum 1;
BA_ "GenSigStartValue" SG_ 935 Side_Detect_R_Illum 100;
BA_ "CrossOver_InfoCAN" SG_ 935 CtaSnsRight_D_Stat 1;
BA_ "CrossOver_InfoCAN" SG_ 935 CtaAlrtRight_D_Stat 1;
BA_ "CrossOver_InfoCAN" SG_ 935 CtaRight_D_Stat 1;
BA_ "CrossOver_InfoCAN" SG_ 935 SodRight_D_Stat 1;
BA_ "GenSigStartValue" SG_ 935 SodRight_D_Stat 2;
BA_ "CrossOver_InfoCAN" SG_ 935 SodSnsRight_D_Stat 1;
BA_ "CrossOver_InfoCAN" SG_ 935 SodAlrtRight_D_Stat 1;
BA_ "CrossOver_InfoCAN" SG_ 935 SodDetctRight_D_Stat 1;
BA_ "U_CD4_MY13_Diesel_Rx" SG_ 935 SodDetctRight_D_Stat 1;
BA_ "U_CD4_MY13_Gas_Rx" SG_ 935 SodDetctRight_D_Stat 1;
BA_ "U_CD4_MY13_Hev_Rx" SG_ 935 SodDetctRight_D_Stat 1;
BA_ "U_CD4_MY13_Phev_Rx" SG_ 935 SodDetctRight_D_Stat 1;
BA_ "U_CD42_MY14_Diesel_Rx" SG_ 935 SodDetctRight_D_Stat 1;
BA_ "U_CD42_MY14_Gas_Rx" SG_ 935 SodDetctRight_D_Stat 1;
BA_ "U_P552_MY15_Gas_Rx" SG_ 935 SodDetctRight_D_Stat 1;
BA_ "U_C489_MY14_Gas_Rx" SG_ 935 SodDetctRight_D_Stat 1;
BA_ "U_U502_MY15_Gas_Rx" SG_ 935 SodDetctRight_D_Stat 1;
BA_ "U_UP375_MY15_Gas_Rx" SG_ 935 SodDetctRight_D_Stat 1;
BA_ "U_UP375_MY15_Diesel_Rx" SG_ 935 SodDetctRight_D_Stat 1;
BA_ "U_CD43_MY16_Gas_Rx" SG_ 935 SodDetctRight_D_Stat 1;
BA_ "U_CD4_MY14_Diesel_Rx" SG_ 935 SodDetctRight_D_Stat 1;
BA_ "U_CD4_MY14_Gas_Rx" SG_ 935 SodDetctRight_D_Stat 1;
BA_ "U_CD4_MY14_Hev_Rx" SG_ 935 SodDetctRight_D_Stat 1;
BA_ "U_CD4_MY14_Phev_Rx" SG_ 935 SodDetctRight_D_Stat 1;
BA_ "CrossOver_InfoCAN" SG_ 935 SodWarnRight_Prd_Rq 1;
BA_ "GenSigStartValue" SG_ 935 SodWarnRight_Prd_Rq 14;
BA_ "CrossOver_InfoCAN" SG_ 935 SodInnrRight_D_Stat 1;
BA_ "CrossOver_InfoCAN" SG_ 935 CtaInnrRight_D_Stat 1;
BA_ "CrossOver_InfoCAN" SG_ 934 Side_Detect_L_Illum 1;
BA_ "GenSigStartValue" SG_ 934 Side_Detect_L_Illum 100;
BA_ "CrossOver_InfoCAN" SG_ 934 CtaSnsLeft_D_Stat 1;
BA_ "CrossOver_InfoCAN" SG_ 934 SodDetctLeft_D_Stat 1;
BA_ "U_CD4_MY13_Diesel_Rx" SG_ 934 SodDetctLeft_D_Stat 1;
BA_ "U_CD4_MY13_Gas_Rx" SG_ 934 SodDetctLeft_D_Stat 1;
BA_ "U_CD4_MY13_Hev_Rx" SG_ 934 SodDetctLeft_D_Stat 1;
BA_ "U_CD4_MY13_Phev_Rx" SG_ 934 SodDetctLeft_D_Stat 1;
BA_ "U_CD42_MY14_Diesel_Rx" SG_ 934 SodDetctLeft_D_Stat 1;
BA_ "U_CD42_MY14_Gas_Rx" SG_ 934 SodDetctLeft_D_Stat 1;
BA_ "U_P552_MY15_Gas_Rx" SG_ 934 SodDetctLeft_D_Stat 1;
BA_ "U_C489_MY14_Gas_Rx" SG_ 934 SodDetctLeft_D_Stat 1;
BA_ "U_U502_MY15_Gas_Rx" SG_ 934 SodDetctLeft_D_Stat 1;
BA_ "U_UP375_MY15_Gas_Rx" SG_ 934 SodDetctLeft_D_Stat 1;
BA_ "U_UP375_MY15_Diesel_Rx" SG_ 934 SodDetctLeft_D_Stat 1;
BA_ "U_CD43_MY16_Gas_Rx" SG_ 934 SodDetctLeft_D_Stat 1;
BA_ "U_CD4_MY14_Diesel_Rx" SG_ 934 SodDetctLeft_D_Stat 1;
BA_ "U_CD4_MY14_Gas_Rx" SG_ 934 SodDetctLeft_D_Stat 1;
BA_ "U_CD4_MY14_Hev_Rx" SG_ 934 SodDetctLeft_D_Stat 1;
BA_ "U_CD4_MY14_Phev_Rx" SG_ 934 SodDetctLeft_D_Stat 1;
BA_ "CrossOver_InfoCAN" SG_ 934 CtaLeft_D_Stat 1;
BA_ "CrossOver_InfoCAN" SG_ 934 CtaAlrtLeft_D_Stat 1;
BA_ "CrossOver_InfoCAN" SG_ 934 SodLeft_D_Stat 1;
BA_ "GenSigStartValue" SG_ 934 SodLeft_D_Stat 2;
BA_ "CrossOver_InfoCAN" SG_ 934 SodSnsLeft_D_Stat 1;
BA_ "CrossOver_InfoCAN" SG_ 934 SodAlrtLeft_D_Stat 1;
BA_ "CrossOver_InfoCAN" SG_ 934 SodWarnLeft_Prd_Rq 1;
BA_ "GenSigStartValue" SG_ 934 SodWarnLeft_Prd_Rq 14;
BA_ "CrossOver_InfoCAN" SG_ 934 SodInnrLeft_D_Stat 1;
BA_ "CrossOver_InfoCAN" SG_ 934 CtaInnrLeft_D_Stat 1;
BA_ "CrossOver_InfoCAN" SG_ 1091 ParkLampTrlrOut_B_Stat 1;
BA_ "CrossOver_InfoCAN" SG_ 1091 StopLampTrlrOut_B_Stat 1;
BA_ "CrossOver_InfoCAN" SG_ 1091 TrlrBattChrg_D_Stat 1;
BA_ "CrossOver_InfoCAN" SG_ 1091 TrlrLampCtl_D_Stat 1;
BA_ "CrossOver_InfoCAN" SG_ 1091 TurnLampTrlrRr_B_Stat 1;
BA_ "CrossOver_InfoCAN" SG_ 1091 TurnLampTrlrRl_B_Stat 1;
BA_ "CrossOver_InfoCAN" SG_ 1091 TrlrLampCnnct_B_Actl 1;
BA_ "U_CD4_MY13_Diesel_Rx" SG_ 1091 TrlrLampCnnct_B_Actl 1;
BA_ "U_CD4_MY13_Gas_Rx" SG_ 1091 TrlrLampCnnct_B_Actl 1;
BA_ "U_CD4_MY13_Hev_Rx" SG_ 1091 TrlrLampCnnct_B_Actl 1;
BA_ "U_CD4_MY13_Phev_Rx" SG_ 1091 TrlrLampCnnct_B_Actl 1;
BA_ "U_CD42_MY14_Diesel_Rx" SG_ 1091 TrlrLampCnnct_B_Actl 1;
BA_ "U_CD42_MY14_Gas_Rx" SG_ 1091 TrlrLampCnnct_B_Actl 1;
BA_ "U_P552_MY15_Gas_Rx" SG_ 1091 TrlrLampCnnct_B_Actl 1;
BA_ "U_C489_MY14_Gas_Rx" SG_ 1091 TrlrLampCnnct_B_Actl 1;
BA_ "U_UP375_MY15_Gas_Rx" SG_ 1091 TrlrLampCnnct_B_Actl 1;
BA_ "U_UP375_MY15_Diesel_Rx" SG_ 1091 TrlrLampCnnct_B_Actl 1;
BA_ "U_CD4_MY14_Diesel_Rx" SG_ 1091 TrlrLampCnnct_B_Actl 1;
BA_ "U_CD4_MY14_Gas_Rx" SG_ 1091 TrlrLampCnnct_B_Actl 1;
BA_ "U_CD4_MY14_Hev_Rx" SG_ 1091 TrlrLampCnnct_B_Actl 1;
BA_ "U_CD4_MY14_Phev_Rx" SG_ 1091 TrlrLampCnnct_B_Actl 1;
BA_ "WakeupSignal" SG_ 1068 PwSysULoFalt_D_Stat 1;
BA_ "CrossOver_InfoCAN" SG_ 1068 PwSysULoFalt_D_Stat 1;
BA_ "U_CD4_MY13_Diesel_Rx" SG_ 1068 PwSysULoFalt_D_Stat 1;
BA_ "U_CD4_MY13_Gas_Rx" SG_ 1068 PwSysULoFalt_D_Stat 1;
BA_ "U_CD4_MY13_Hev_Rx" SG_ 1068 PwSysULoFalt_D_Stat 1;
BA_ "U_CD4_MY13_Phev_Rx" SG_ 1068 PwSysULoFalt_D_Stat 1;
BA_ "U_CD42_MY14_Diesel_Rx" SG_ 1068 PwSysULoFalt_D_Stat 1;
BA_ "U_CD42_MY14_Gas_Rx" SG_ 1068 PwSysULoFalt_D_Stat 1;
BA_ "U_P552_MY15_Gas_Rx" SG_ 1068 PwSysULoFalt_D_Stat 1;
BA_ "U_S550_MY15_Gas_Rx" SG_ 1068 PwSysULoFalt_D_Stat 1;
BA_ "U_C489_MY14_Gas_Rx" SG_ 1068 PwSysULoFalt_D_Stat 1;
BA_ "U_U502_MY15_Gas_Rx" SG_ 1068 PwSysULoFalt_D_Stat 1;
BA_ "U_UP375_MY15_Gas_Rx" SG_ 1068 PwSysULoFalt_D_Stat 1;
BA_ "U_UP375_MY15_Diesel_Rx" SG_ 1068 PwSysULoFalt_D_Stat 1;
BA_ "U_CD43_MY16_Gas_Rx" SG_ 1068 PwSysULoFalt_D_Stat 1;
BA_ "CrossOver_InfoCAN" SG_ 1068 Shed_T_Eng_Off_B 1;
BA_ "U_CD4_MY13_Diesel_Rx" SG_ 1068 Shed_T_Eng_Off_B 1;
BA_ "U_CD4_MY13_Gas_Rx" SG_ 1068 Shed_T_Eng_Off_B 1;
BA_ "U_CD4_MY13_Hev_Rx" SG_ 1068 Shed_T_Eng_Off_B 1;
BA_ "U_CD4_MY13_Phev_Rx" SG_ 1068 Shed_T_Eng_Off_B 1;
BA_ "U_CD42_MY14_Diesel_Rx" SG_ 1068 Shed_T_Eng_Off_B 1;
BA_ "U_CD42_MY14_Gas_Rx" SG_ 1068 Shed_T_Eng_Off_B 1;
BA_ "U_P552_MY15_Gas_Rx" SG_ 1068 Shed_T_Eng_Off_B 1;
BA_ "U_S550_MY15_Gas_Rx" SG_ 1068 Shed_T_Eng_Off_B 1;
BA_ "U_C489_MY14_Gas_Rx" SG_ 1068 Shed_T_Eng_Off_B 1;
BA_ "U_U502_MY15_Gas_Rx" SG_ 1068 Shed_T_Eng_Off_B 1;
BA_ "U_UP375_MY15_Gas_Rx" SG_ 1068 Shed_T_Eng_Off_B 1;
BA_ "U_UP375_MY15_Diesel_Rx" SG_ 1068 Shed_T_Eng_Off_B 1;
BA_ "U_CD43_MY16_Gas_Rx" SG_ 1068 Shed_T_Eng_Off_B 1;
BA_ "WakeupSignal" SG_ 1068 Shed_Feature_Group_ID 1;
BA_ "U_CD4_MY13_Diesel_Rx" SG_ 1068 Shed_Feature_Group_ID 1;
BA_ "U_CD4_MY13_Gas_Rx" SG_ 1068 Shed_Feature_Group_ID 1;
BA_ "U_CD4_MY13_Hev_Rx" SG_ 1068 Shed_Feature_Group_ID 1;
BA_ "U_CD4_MY13_Phev_Rx" SG_ 1068 Shed_Feature_Group_ID 1;
BA_ "U_CD42_MY14_Diesel_Rx" SG_ 1068 Shed_Feature_Group_ID 1;
BA_ "U_CD42_MY14_Gas_Rx" SG_ 1068 Shed_Feature_Group_ID 1;
BA_ "U_P552_MY15_Gas_Rx" SG_ 1068 Shed_Feature_Group_ID 1;
BA_ "U_S550_MY15_Gas_Rx" SG_ 1068 Shed_Feature_Group_ID 1;
BA_ "U_C489_MY14_Gas_Rx" SG_ 1068 Shed_Feature_Group_ID 1;
BA_ "U_U502_MY15_Gas_Rx" SG_ 1068 Shed_Feature_Group_ID 1;
BA_ "U_UP375_MY15_Gas_Rx" SG_ 1068 Shed_Feature_Group_ID 1;
BA_ "U_UP375_MY15_Diesel_Rx" SG_ 1068 Shed_Feature_Group_ID 1;
BA_ "U_CD43_MY16_Gas_Rx" SG_ 1068 Shed_Feature_Group_ID 1;
BA_ "CrossOver_InfoCAN" SG_ 1068 Shed_Drain_Eng_Off_B 1;
BA_ "U_CD4_MY13_Diesel_Rx" SG_ 1068 Shed_Drain_Eng_Off_B 1;
BA_ "U_CD4_MY13_Gas_Rx" SG_ 1068 Shed_Drain_Eng_Off_B 1;
BA_ "U_CD4_MY13_Hev_Rx" SG_ 1068 Shed_Drain_Eng_Off_B 1;
BA_ "U_CD4_MY13_Phev_Rx" SG_ 1068 Shed_Drain_Eng_Off_B 1;
BA_ "U_CD42_MY14_Diesel_Rx" SG_ 1068 Shed_Drain_Eng_Off_B 1;
BA_ "U_CD42_MY14_Gas_Rx" SG_ 1068 Shed_Drain_Eng_Off_B 1;
BA_ "U_P552_MY15_Gas_Rx" SG_ 1068 Shed_Drain_Eng_Off_B 1;
BA_ "U_S550_MY15_Gas_Rx" SG_ 1068 Shed_Drain_Eng_Off_B 1;
BA_ "U_C489_MY14_Gas_Rx" SG_ 1068 Shed_Drain_Eng_Off_B 1;
BA_ "U_U502_MY15_Gas_Rx" SG_ 1068 Shed_Drain_Eng_Off_B 1;
BA_ "U_UP375_MY15_Gas_Rx" SG_ 1068 Shed_Drain_Eng_Off_B 1;
BA_ "U_UP375_MY15_Diesel_Rx" SG_ 1068 Shed_Drain_Eng_Off_B 1;
BA_ "U_CD43_MY16_Gas_Rx" SG_ 1068 Shed_Drain_Eng_Off_B 1;
BA_ "WakeupSignal" SG_ 1068 Shed_Level_Req 1;
BA_ "CrossOver_InfoCAN" SG_ 1068 Shed_Level_Req 1;
BA_ "U_CD4_MY13_Diesel_Rx" SG_ 1068 Shed_Level_Req 1;
BA_ "U_CD4_MY13_Gas_Rx" SG_ 1068 Shed_Level_Req 1;
BA_ "U_CD4_MY13_Hev_Rx" SG_ 1068 Shed_Level_Req 1;
BA_ "U_CD4_MY13_Phev_Rx" SG_ 1068 Shed_Level_Req 1;
BA_ "U_CD42_MY14_Diesel_Rx" SG_ 1068 Shed_Level_Req 1;
BA_ "U_CD42_MY14_Gas_Rx" SG_ 1068 Shed_Level_Req 1;
BA_ "U_P552_MY15_Gas_Rx" SG_ 1068 Shed_Level_Req 1;
BA_ "U_S550_MY15_Gas_Rx" SG_ 1068 Shed_Level_Req 1;
BA_ "U_C489_MY14_Gas_Rx" SG_ 1068 Shed_Level_Req 1;
BA_ "U_U502_MY15_Gas_Rx" SG_ 1068 Shed_Level_Req 1;
BA_ "U_UP375_MY15_Gas_Rx" SG_ 1068 Shed_Level_Req 1;
BA_ "U_UP375_MY15_Diesel_Rx" SG_ 1068 Shed_Level_Req 1;
BA_ "U_CD43_MY16_Gas_Rx" SG_ 1068 Shed_Level_Req 1;
BA_ "CrossOver_InfoCAN" SG_ 1068 Batt_Lo_SoC_B 1;
BA_ "CrossOver_InfoCAN" SG_ 1068 Batt_Crit_SoC_B 1;
BA_ "U_P552_MY17_Gas_Tx" SG_ 611 AwdDrvMde_D_Stat 1;
BA_ "U_P552_MY15_Gas_Tx" SG_ 611 AwdSys_D_Stat 1;
BA_ "U_UP375_MY15_Gas_Tx" SG_ 611 AwdSys_D_Stat 1;
BA_ "U_UP375_MY15_Diesel_Tx" SG_ 611 AwdSys_D_Stat 1;
BA_ "CrossOver_InfoCAN" SG_ 611 AwdStat_D_RqDsply 1;
BA_ "ContentDependant" SG_ 611 AwdStat_D_RqDsply 1;
BA_ "U_P552_MY15_Gas_Tx" SG_ 611 AwdStat_D_RqDsply 1;
BA_ "U_UP375_MY15_Gas_Tx" SG_ 611 AwdStat_D_RqDsply 1;
BA_ "U_UP375_MY15_Diesel_Tx" SG_ 611 AwdStat_D_RqDsply 1;
BA_ "CrossOver_InfoCAN" SG_ 611 AwdLck_D_Stat 1;
BA_ "U_CD4_MY13_Diesel_Rx" SG_ 611 AwdLck_D_Stat 1;
BA_ "U_CD4_MY13_Gas_Rx" SG_ 611 AwdLck_D_Stat 1;
BA_ "U_CD42_MY14_Diesel_Rx" SG_ 611 AwdLck_D_Stat 1;
BA_ "U_CD42_MY14_Gas_Rx" SG_ 611 AwdLck_D_Stat 1;
BA_ "U_P552_MY15_Gas_Rx" SG_ 611 AwdLck_D_Stat 1;
BA_ "U_C489_MY14_Gas_Rx" SG_ 611 AwdLck_D_Stat 1;
BA_ "U_U502_MY15_Gas_Rx" SG_ 611 AwdLck_D_Stat 1;
BA_ "U_UP375_MY15_Gas_Rx" SG_ 611 AwdLck_D_Stat 1;
BA_ "U_UP375_MY15_Diesel_Rx" SG_ 611 AwdLck_D_Stat 1;
BA_ "U_CD43_MY16_Gas_Rx" SG_ 611 AwdLck_D_Stat 1;
BA_ "U_P552_MY15_Gas_Tx" SG_ 611 AwdLck_D_Stat 1;
BA_ "U_UP375_MY15_Gas_Tx" SG_ 611 AwdLck_D_Stat 1;
BA_ "U_UP375_MY15_Diesel_Tx" SG_ 611 AwdLck_D_Stat 1;
BA_ "CrossOver_InfoCAN" SG_ 611 AwdSrvcRqd_B_Rq 1;
BA_ "ContentDependant" SG_ 611 AwdSrvcRqd_B_Rq 1;
BA_ "U_CD4_MY13_Diesel_Rx" SG_ 611 AwdSrvcRqd_B_Rq 1;
BA_ "U_CD4_MY13_Gas_Rx" SG_ 611 AwdSrvcRqd_B_Rq 1;
BA_ "U_CD42_MY14_Diesel_Rx" SG_ 611 AwdSrvcRqd_B_Rq 1;
BA_ "U_CD42_MY14_Gas_Rx" SG_ 611 AwdSrvcRqd_B_Rq 1;
BA_ "U_P552_MY15_Gas_Rx" SG_ 611 AwdSrvcRqd_B_Rq 1;
BA_ "U_C489_MY14_Gas_Rx" SG_ 611 AwdSrvcRqd_B_Rq 1;
BA_ "U_U502_MY15_Gas_Rx" SG_ 611 AwdSrvcRqd_B_Rq 1;
BA_ "U_CD43_MY16_Gas_Rx" SG_ 611 AwdSrvcRqd_B_Rq 1;
BA_ "U_UP375_MY15_Gas_Rx" SG_ 611 AwdSrvcRqd_B_Rq 1;
BA_ "U_UP375_MY15_Diesel_Rx" SG_ 611 AwdSrvcRqd_B_Rq 1;
BA_ "U_P552_MY15_Gas_Tx" SG_ 611 AwdSrvcRqd_B_Rq 1;
BA_ "U_UP375_MY15_Gas_Tx" SG_ 611 AwdSrvcRqd_B_Rq 1;
BA_ "U_UP375_MY15_Diesel_Tx" SG_ 611 AwdSrvcRqd_B_Rq 1;
BA_ "CrossOver_InfoCAN" SG_ 611 AwdLck_Tq_Rq 1;
BA_ "ContentDependant" SG_ 611 AwdLck_Tq_Rq 1;
BA_ "U_P552_MY15_Gas_Rx" SG_ 611 AwdLck_Tq_Rq 1;
BA_ "U_UP375_MY15_Gas_Rx" SG_ 611 AwdLck_Tq_Rq 1;
BA_ "U_UP375_MY15_Diesel_Rx" SG_ 611 AwdLck_Tq_Rq 1;
BA_ "U_P552_MY15_Gas_Tx" SG_ 611 AwdLck_Tq_Rq 1;
BA_ "U_UP375_MY15_Gas_Tx" SG_ 611 AwdLck_Tq_Rq 1;
BA_ "U_UP375_MY15_Diesel_Tx" SG_ 611 AwdLck_Tq_Rq 1;
BA_ "CrossOver_InfoCAN" SG_ 611 TrnAout_Tq_RqMx 1;
BA_ "U_P552_MY15_Gas_Tx" SG_ 611 TrnAout_Tq_RqMx 1;
BA_ "U_UP375_MY15_Gas_Tx" SG_ 611 TrnAout_Tq_RqMx 1;
BA_ "U_UP375_MY15_Diesel_Tx" SG_ 611 TrnAout_Tq_RqMx 1;
BA_ "GenSigStartValue" SG_ 611 TrnAout_Tq_RqMx 8191;
BA_ "CrossOver_InfoCAN" SG_ 611 AwdOffRoadMode_D_Stats 1;
BA_ "U_P552_MY15_Gas_Rx" SG_ 611 AwdOffRoadMode_D_Stats 1;
BA_ "U_UP375_MY15_Gas_Rx" SG_ 611 AwdOffRoadMode_D_Stats 1;
BA_ "U_UP375_MY15_Diesel_Rx" SG_ 611 AwdOffRoadMode_D_Stats 1;
BA_ "U_P552_MY15_Gas_Tx" SG_ 611 AwdOffRoadMode_D_Stats 1;
BA_ "U_UP375_MY15_Gas_Tx" SG_ 611 AwdOffRoadMode_D_Stats 1;
BA_ "U_UP375_MY15_Diesel_Tx" SG_ 611 AwdOffRoadMode_D_Stats 1;
BA_ "CrossOver_InfoCAN" SG_ 611 AwdLoLamp_D_RqDsply 1;
BA_ "U_P552_MY15_Gas_Tx" SG_ 611 AwdLoLamp_D_RqDsply 1;
BA_ "U_UP375_MY15_Gas_Tx" SG_ 611 AwdLoLamp_D_RqDsply 1;
BA_ "U_UP375_MY15_Diesel_Tx" SG_ 611 AwdLoLamp_D_RqDsply 1;
BA_ "U_U55x_MY18_Gas_Tx" SG_ 611 AwdLoLamp_D_RqDsply 1;
BA_ "U_P552_MY18_Gas_Tx" SG_ 611 AwdLoLamp_D_RqDsply 1;
BA_ "U_P552_MY17_Gas_Tx" SG_ 611 AwdLoLamp_D_RqDsply 1;
BA_ "U_V36X_MY16_5_Diesel_Tx" SG_ 611 AwdLoLamp_D_RqDsply 1;
BA_ "U_P558_MY17_Diesel_Tx" SG_ 611 AwdLoLamp_D_RqDsply 1;
BA_ "U_P558_MY17_Gas_Tx" SG_ 611 AwdLoLamp_D_RqDsply 1;
BA_ "U_U55x_MY18_Gas_Rx" SG_ 611 AwdLoLamp_D_RqDsply 1;
BA_ "U_P552_MY18_Gas_Rx" SG_ 611 AwdLoLamp_D_RqDsply 1;
BA_ "U_P552_MY17_Gas_Rx" SG_ 611 AwdLoLamp_D_RqDsply 1;
BA_ "CrossOver_InfoCAN" SG_ 611 AwdHiLamp_D_RqDsply 1;
BA_ "U_P552_MY15_Gas_Tx" SG_ 611 AwdHiLamp_D_RqDsply 1;
BA_ "U_UP375_MY15_Gas_Tx" SG_ 611 AwdHiLamp_D_RqDsply 1;
BA_ "U_UP375_MY15_Diesel_Tx" SG_ 611 AwdHiLamp_D_RqDsply 1;
BA_ "U_U55x_MY18_Gas_Tx" SG_ 611 AwdHiLamp_D_RqDsply 1;
BA_ "U_P552_MY18_Gas_Tx" SG_ 611 AwdHiLamp_D_RqDsply 1;
BA_ "U_P552_MY17_Gas_Tx" SG_ 611 AwdHiLamp_D_RqDsply 1;
BA_ "U_V36X_MY16_5_Diesel_Tx" SG_ 611 AwdHiLamp_D_RqDsply 1;
BA_ "U_P558_MY17_Diesel_Tx" SG_ 611 AwdHiLamp_D_RqDsply 1;
BA_ "U_P558_MY17_Gas_Tx" SG_ 611 AwdHiLamp_D_RqDsply 1;
BA_ "U_U55x_MY18_Gas_Rx" SG_ 611 AwdHiLamp_D_RqDsply 1;
BA_ "U_P552_MY18_Gas_Rx" SG_ 611 AwdHiLamp_D_RqDsply 1;
BA_ "U_P552_MY17_Gas_Rx" SG_ 611 AwdHiLamp_D_RqDsply 1;
BA_ "CrossOver_InfoCAN" SG_ 611 AwdAutoLamp_D_RqDsply 1;
BA_ "U_P552_MY15_Gas_Tx" SG_ 611 AwdAutoLamp_D_RqDsply 1;
BA_ "U_UP375_MY15_Gas_Tx" SG_ 611 AwdAutoLamp_D_RqDsply 1;
BA_ "U_UP375_MY15_Diesel_Tx" SG_ 611 AwdAutoLamp_D_RqDsply 1;
BA_ "U_U55x_MY18_Gas_Tx" SG_ 611 AwdAutoLamp_D_RqDsply 1;
BA_ "U_P552_MY18_Gas_Tx" SG_ 611 AwdAutoLamp_D_RqDsply 1;
BA_ "U_P552_MY17_Gas_Tx" SG_ 611 AwdAutoLamp_D_RqDsply 1;
BA_ "U_V36X_MY16_5_Diesel_Tx" SG_ 611 AwdAutoLamp_D_RqDsply 1;
BA_ "U_U55x_MY18_Gas_Rx" SG_ 611 AwdAutoLamp_D_RqDsply 1;
BA_ "U_P552_MY18_Gas_Rx" SG_ 611 AwdAutoLamp_D_RqDsply 1;
BA_ "U_P552_MY17_Gas_Rx" SG_ 611 AwdAutoLamp_D_RqDsply 1;
BA_ "CrossOver_InfoCAN" SG_ 611 Awd2wdLamp_D_RqDsply 1;
BA_ "U_P552_MY15_Gas_Tx" SG_ 611 Awd2wdLamp_D_RqDsply 1;
BA_ "U_UP375_MY15_Gas_Tx" SG_ 611 Awd2wdLamp_D_RqDsply 1;
BA_ "U_UP375_MY15_Diesel_Tx" SG_ 611 Awd2wdLamp_D_RqDsply 1;
BA_ "U_U55x_MY18_Gas_Tx" SG_ 611 Awd2wdLamp_D_RqDsply 1;
BA_ "U_P552_MY18_Gas_Tx" SG_ 611 Awd2wdLamp_D_RqDsply 1;
BA_ "U_P552_MY17_Gas_Tx" SG_ 611 Awd2wdLamp_D_RqDsply 1;
BA_ "U_V36X_MY16_5_Diesel_Tx" SG_ 611 Awd2wdLamp_D_RqDsply 1;
BA_ "U_P558_MY17_Diesel_Tx" SG_ 611 Awd2wdLamp_D_RqDsply 1;
BA_ "U_P558_MY17_Gas_Tx" SG_ 611 Awd2wdLamp_D_RqDsply 1;
BA_ "U_U55x_MY18_Gas_Rx" SG_ 611 Awd2wdLamp_D_RqDsply 1;
BA_ "U_P552_MY18_Gas_Rx" SG_ 611 Awd2wdLamp_D_RqDsply 1;
BA_ "U_P552_MY17_Gas_Rx" SG_ 611 Awd2wdLamp_D_RqDsply 1;
BA_ "CrossOver_InfoCAN" SG_ 611 AwdRnge_D_Actl 1;
BA_ "U_P552_MY15_Gas_Rx" SG_ 611 AwdRnge_D_Actl 1;
BA_ "U_UP375_MY15_Gas_Rx" SG_ 611 AwdRnge_D_Actl 1;
BA_ "U_UP375_MY15_Diesel_Rx" SG_ 611 AwdRnge_D_Actl 1;
BA_ "U_P552_MY15_Gas_Tx" SG_ 611 AwdRnge_D_Actl 1;
BA_ "U_UP375_MY15_Gas_Tx" SG_ 611 AwdRnge_D_Actl 1;
BA_ "U_UP375_MY15_Diesel_Tx" SG_ 611 AwdRnge_D_Actl 1;
BA_ "GenSigStartValue" SG_ 611 AwdRnge_D_Actl 7;
BA_ "GenSigStartValue" SG_ 578 BattULo_U_Actl 255;
BA_ "CrossOver_InfoCAN" SG_ 578 PrkLckCtl_B_Enbl 1;
BA_ "WakeupSignal" SG_ 578 PrkLckCtlMsgTxt_D_Rq 1;
BA_ "CrossOver_InfoCAN" SG_ 578 PrkLckCtlMsgTxt_D_Rq 1;
BA_ "WakeupSignal" SG_ 578 PrkLckCtlAvail_T_Stat 1;
BA_ "CrossOver_InfoCAN" SG_ 578 PrkLckCtlAvail_T_Stat 1;
BA_ "U_P552_MY15_Gas_Rx" SG_ 578 EngOff_T_Actl 1;
BA_ "U_S550_MY15_Gas_Rx" SG_ 578 EngOff_T_Actl 1;
BA_ "U_UP375_MY15_Gas_Rx" SG_ 578 EngOff_T_Actl 1;
BA_ "U_UP375_MY15_Diesel_Rx" SG_ 578 EngOff_T_Actl 1;
BA_ "WakeupSignal" SG_ 578 ReFuelSwtchStat_D_Actl 1;
BA_ "GenSigStartValue" SG_ 578 BattULo_I_Actl 16383;
BA_ "GenSigSendType" SG_ 560 SelDrvMdeSwtch_D_Stat3 3;
BA_ "U_B479_MY17_Gas_Rx" SG_ 560 SelDrvMdeSwtch_D_Stat3 1;
BA_ "U_B479_MY17_Diesel_Rx" SG_ 560 SelDrvMdeSwtch_D_Stat3 1;
BA_ "U_B562_MY18_Gas_Rx" SG_ 560 SelDrvMdeSwtch_D_Stat3 1;
BA_ "U_C490_MY18_Diesel_Rx" SG_ 560 SelDrvMdeSwtch_D_Stat3 1;
BA_ "U_C490_MY18_Gas_Rx" SG_ 560 SelDrvMdeSwtch_D_Stat3 1;
BA_ "ContentDependant" SG_ 560 GearLvrPosActl_No_Cs 1;
BA_ "ContentDependant" SG_ 560 GearLvrPosActl_No_Cnt 1;
BA_ "CrossOver_InfoCAN" SG_ 560 TrnSrvcRqd_B_Rq 1;
BA_ "ContentDependant" SG_ 560 TrnSrvcRqd_B_Rq 1;
BA_ "U_CD4_MY13_Diesel_Rx" SG_ 560 TrnSrvcRqd_B_Rq 1;
BA_ "U_CD4_MY13_Gas_Rx" SG_ 560 TrnSrvcRqd_B_Rq 1;
BA_ "U_CD4_MY13_Hev_Rx" SG_ 560 TrnSrvcRqd_B_Rq 1;
BA_ "U_CD4_MY13_Phev_Rx" SG_ 560 TrnSrvcRqd_B_Rq 1;
BA_ "U_CD42_MY14_Diesel_Rx" SG_ 560 TrnSrvcRqd_B_Rq 1;
BA_ "U_CD42_MY14_Gas_Rx" SG_ 560 TrnSrvcRqd_B_Rq 1;
BA_ "U_P552_MY15_Gas_Rx" SG_ 560 TrnSrvcRqd_B_Rq 1;
BA_ "U_S550_MY15_Gas_Rx" SG_ 560 TrnSrvcRqd_B_Rq 1;
BA_ "U_C489_MY14_Gas_Rx" SG_ 560 TrnSrvcRqd_B_Rq 1;
BA_ "U_U502_MY15_Gas_Rx" SG_ 560 TrnSrvcRqd_B_Rq 1;
BA_ "U_UP375_MY15_Gas_Rx" SG_ 560 TrnSrvcRqd_B_Rq 1;
BA_ "U_UP375_MY15_Diesel_Rx" SG_ 560 TrnSrvcRqd_B_Rq 1;
BA_ "U_CD43_MY16_Gas_Rx" SG_ 560 TrnSrvcRqd_B_Rq 1;
BA_ "GenSigStartValue" SG_ 560 GearPos_D_Trg 15;
BA_ "CrossOver_InfoCAN" SG_ 560 GearPos_D_Trg 1;
BA_ "ContentDependant" SG_ 560 GearPos_D_Trg 1;
BA_ "U_CD4_MY13_Diesel_Rx" SG_ 560 GearPos_D_Trg 1;
BA_ "U_CD4_MY13_Gas_Rx" SG_ 560 GearPos_D_Trg 1;
BA_ "U_CD42_MY14_Diesel_Rx" SG_ 560 GearPos_D_Trg 1;
BA_ "U_CD42_MY14_Gas_Rx" SG_ 560 GearPos_D_Trg 1;
BA_ "U_P552_MY15_Gas_Rx" SG_ 560 GearPos_D_Trg 1;
BA_ "U_S550_MY15_Gas_Rx" SG_ 560 GearPos_D_Trg 1;
BA_ "U_C489_MY14_Gas_Rx" SG_ 560 GearPos_D_Trg 1;
BA_ "U_U502_MY15_Gas_Rx" SG_ 560 GearPos_D_Trg 1;
BA_ "U_CD43_MY16_Gas_Rx" SG_ 560 GearPos_D_Trg 1;
BA_ "U_UP375_MY15_Gas_Rx" SG_ 560 GearPos_D_Trg 1;
BA_ "U_UP375_MY15_Diesel_Rx" SG_ 560 GearPos_D_Trg 1;
BA_ "ContentDependant" SG_ 560 TrnShifActv_B_Actl 1;
BA_ "U_CD4_MY13_Diesel_Rx" SG_ 560 TrnShifActv_B_Actl 1;
BA_ "U_CD4_MY13_Gas_Rx" SG_ 560 TrnShifActv_B_Actl 1;
BA_ "U_CD42_MY14_Diesel_Rx" SG_ 560 TrnShifActv_B_Actl 1;
BA_ "U_CD42_MY14_Gas_Rx" SG_ 560 TrnShifActv_B_Actl 1;
BA_ "U_P552_MY15_Gas_Rx" SG_ 560 TrnShifActv_B_Actl 1;
BA_ "U_S550_MY15_Gas_Rx" SG_ 560 TrnShifActv_B_Actl 1;
BA_ "U_C489_MY14_Gas_Rx" SG_ 560 TrnShifActv_B_Actl 1;
BA_ "U_U502_MY15_Gas_Rx" SG_ 560 TrnShifActv_B_Actl 1;
BA_ "U_CD43_MY16_Gas_Rx" SG_ 560 TrnShifActv_B_Actl 1;
BA_ "CrossOver_InfoCAN" SG_ 560 GearLvrPos_D_Actl 1;
BA_ "CrossOver_LIN" SG_ 560 GearLvrPos_D_Actl 1;
BA_ "U_CD4_MY13_Diesel_Rx" SG_ 560 GearLvrPos_D_Actl 1;
BA_ "U_CD4_MY13_Gas_Rx" SG_ 560 GearLvrPos_D_Actl 1;
BA_ "U_CD4_MY13_Hev_Rx" SG_ 560 GearLvrPos_D_Actl 1;
BA_ "U_CD4_MY13_Phev_Rx" SG_ 560 GearLvrPos_D_Actl 1;
BA_ "U_CD42_MY14_Diesel_Rx" SG_ 560 GearLvrPos_D_Actl 1;
BA_ "U_CD42_MY14_Gas_Rx" SG_ 560 GearLvrPos_D_Actl 1;
BA_ "U_P552_MY15_Gas_Rx" SG_ 560 GearLvrPos_D_Actl 1;
BA_ "U_S550_MY15_Gas_Rx" SG_ 560 GearLvrPos_D_Actl 1;
BA_ "U_C489_MY14_Gas_Rx" SG_ 560 GearLvrPos_D_Actl 1;
BA_ "U_U502_MY15_Gas_Rx" SG_ 560 GearLvrPos_D_Actl 1;
BA_ "U_CD43_MY16_Gas_Rx" SG_ 560 GearLvrPos_D_Actl 1;
BA_ "U_UP375_MY15_Gas_Rx" SG_ 560 GearLvrPos_D_Actl 1;
BA_ "U_UP375_MY15_Diesel_Rx" SG_ 560 GearLvrPos_D_Actl 1;
BA_ "ContentDependant" SG_ 560 GboxOil_Te_Actl 1;
BA_ "U_P552_MY15_Gas_Rx" SG_ 560 GboxOil_Te_Actl 1;
BA_ "U_UP375_MY15_Gas_Rx" SG_ 560 GboxOil_Te_Actl 1;
BA_ "U_UP375_MY15_Diesel_Rx" SG_ 560 GboxOil_Te_Actl 1;
BA_ "CrossOver_InfoCAN" SG_ 359 ElPw_D_StatStrtStop 1;
BA_ "U_CD4_MY13_Diesel_Rx" SG_ 359 ElPw_D_StatStrtStop 1;
BA_ "U_CD4_MY13_Gas_Rx" SG_ 359 ElPw_D_StatStrtStop 1;
BA_ "U_CD4_MY13_Hev_Rx" SG_ 359 ElPw_D_StatStrtStop 1;
BA_ "U_CD4_MY13_Phev_Rx" SG_ 359 ElPw_D_StatStrtStop 1;
BA_ "U_CD42_MY14_Diesel_Rx" SG_ 359 ElPw_D_StatStrtStop 1;
BA_ "U_CD42_MY14_Gas_Rx" SG_ 359 ElPw_D_StatStrtStop 1;
BA_ "U_P552_MY15_Gas_Rx" SG_ 359 ElPw_D_StatStrtStop 1;
BA_ "U_U502_MY15_Gas_Rx" SG_ 359 ElPw_D_StatStrtStop 1;
BA_ "U_UP375_MY15_Gas_Rx" SG_ 359 ElPw_D_StatStrtStop 1;
BA_ "U_UP375_MY15_Diesel_Rx" SG_ 359 ElPw_D_StatStrtStop 1;
BA_ "U_CD43_MY16_Gas_Rx" SG_ 359 ElPw_D_StatStrtStop 1;
BA_ "CrossOver_InfoCAN" SG_ 359 TrnAin_Tq_Actl 1;
BA_ "ContentDependant" SG_ 359 TrnAin_Tq_Actl 1;
BA_ "CrossOver_InfoCAN" SG_ 359 PrplWhlTot2_Tq_Actl 1;
BA_ "U_CD4_MY13_Diesel_Rx" SG_ 359 PrplWhlTot2_Tq_Actl 1;
BA_ "U_CD4_MY13_Gas_Rx" SG_ 359 PrplWhlTot2_Tq_Actl 1;
BA_ "U_CD4_MY13_Hev_Rx" SG_ 359 PrplWhlTot2_Tq_Actl 1;
BA_ "U_CD4_MY13_Phev_Rx" SG_ 359 PrplWhlTot2_Tq_Actl 1;
BA_ "U_P552_MY15_Gas_Rx" SG_ 359 PrplWhlTot2_Tq_Actl 1;
BA_ "U_UP375_MY15_Gas_Rx" SG_ 359 PrplWhlTot2_Tq_Actl 1;
BA_ "U_UP375_MY15_Diesel_Rx" SG_ 359 PrplWhlTot2_Tq_Actl 1;
BA_ "U_CD42_MY14_Diesel_Rx" SG_ 359 PrplWhlTot2_Tq_Actl 1;
BA_ "U_CD42_MY14_Gas_Rx" SG_ 359 PrplWhlTot2_Tq_Actl 1;
BA_ "U_S550_MY15_Gas_Rx" SG_ 359 PrplWhlTot2_Tq_Actl 1;
BA_ "U_C489_MY14_Gas_Rx" SG_ 359 PrplWhlTot2_Tq_Actl 1;
BA_ "U_U502_MY15_Gas_Rx" SG_ 359 PrplWhlTot2_Tq_Actl 1;
BA_ "U_CD43_MY16_Gas_Rx" SG_ 359 PrplWhlTot2_Tq_Actl 1;
BA_ "CrossOver_InfoCAN" SG_ 359 PwPckTq_D_Stat 1;
BA_ "U_CD42_MY14_Diesel_Rx" SG_ 359 PwPckTq_D_Stat 1;
BA_ "U_CD42_MY14_Gas_Rx" SG_ 359 PwPckTq_D_Stat 1;
BA_ "U_P552_MY15_Gas_Rx" SG_ 359 PwPckTq_D_Stat 1;
BA_ "U_S550_MY15_Gas_Rx" SG_ 359 PwPckTq_D_Stat 1;
BA_ "U_C489_MY14_Gas_Rx" SG_ 359 PwPckTq_D_Stat 1;
BA_ "U_U502_MY15_Gas_Rx" SG_ 359 PwPckTq_D_Stat 1;
BA_ "U_UP375_MY15_Gas_Rx" SG_ 359 PwPckTq_D_Stat 1;
BA_ "U_UP375_MY15_Diesel_Rx" SG_ 359 PwPckTq_D_Stat 1;
BA_ "U_CD43_MY16_Gas_Rx" SG_ 359 PwPckTq_D_Stat 1;
BA_ "U_CD4_MY14_Diesel_Rx" SG_ 359 PwPckTq_D_Stat 1;
BA_ "U_CD4_MY14_Gas_Rx" SG_ 359 PwPckTq_D_Stat 1;
BA_ "U_CD4_MY14_Hev_Rx" SG_ 359 PwPckTq_D_Stat 1;
BA_ "U_CD4_MY14_Phev_Rx" SG_ 359 PwPckTq_D_Stat 1;
BA_ "GenSigTimeoutTime_OCS" SG_ 359 PwPckTq_D_Stat 6000;
BA_ "CrossOver_InfoCAN" SG_ 359 Eng_D_Stat 1;
BA_ "U_CD4_MY13_Diesel_Rx" SG_ 359 Eng_D_Stat 1;
BA_ "U_CD4_MY13_Gas_Rx" SG_ 359 Eng_D_Stat 1;
BA_ "U_CD4_MY13_Hev_Rx" SG_ 359 Eng_D_Stat 1;
BA_ "U_CD4_MY13_Phev_Rx" SG_ 359 Eng_D_Stat 1;
BA_ "U_CD42_MY14_Diesel_Rx" SG_ 359 Eng_D_Stat 1;
BA_ "U_CD42_MY14_Gas_Rx" SG_ 359 Eng_D_Stat 1;
BA_ "U_P552_MY15_Gas_Rx" SG_ 359 Eng_D_Stat 1;
BA_ "U_S550_MY15_Gas_Rx" SG_ 359 Eng_D_Stat 1;
BA_ "U_C489_MY14_Gas_Rx" SG_ 359 Eng_D_Stat 1;
BA_ "U_U502_MY15_Gas_Rx" SG_ 359 Eng_D_Stat 1;
BA_ "U_UP375_MY15_Gas_Rx" SG_ 359 Eng_D_Stat 1;
BA_ "U_UP375_MY15_Diesel_Rx" SG_ 359 Eng_D_Stat 1;
BA_ "U_CD43_MY16_Gas_Rx" SG_ 359 Eng_D_Stat 1;
BA_ "CrossOver_InfoCAN" SG_ 359 ElPw_D_Stat 1;
BA_ "U_CD4_MY13_Diesel_Rx" SG_ 359 ElPw_D_Stat 1;
BA_ "U_CD4_MY13_Gas_Rx" SG_ 359 ElPw_D_Stat 1;
BA_ "U_CD4_MY13_Hev_Rx" SG_ 359 ElPw_D_Stat 1;
BA_ "U_CD4_MY13_Phev_Rx" SG_ 359 ElPw_D_Stat 1;
BA_ "U_P552_MY15_Gas_Rx" SG_ 359 ElPw_D_Stat 1;
BA_ "U_UP375_MY15_Gas_Rx" SG_ 359 ElPw_D_Stat 1;
BA_ "U_UP375_MY15_Diesel_Rx" SG_ 359 ElPw_D_Stat 1;
BA_ "U_CD42_MY14_Diesel_Rx" SG_ 359 ElPw_D_Stat 1;
BA_ "U_CD42_MY14_Gas_Rx" SG_ 359 ElPw_D_Stat 1;
BA_ "U_S550_MY15_Gas_Rx" SG_ 359 ElPw_D_Stat 1;
BA_ "U_C489_MY14_Gas_Rx" SG_ 359 ElPw_D_Stat 1;
BA_ "U_U502_MY15_Gas_Rx" SG_ 359 ElPw_D_Stat 1;
BA_ "U_CD43_MY16_Gas_Rx" SG_ 359 ElPw_D_Stat 1;
BA_ "U_CD4_MY14_Diesel_Rx" SG_ 359 ElPw_D_Stat 1;
BA_ "U_CD4_MY14_Gas_Rx" SG_ 359 ElPw_D_Stat 1;
BA_ "U_CD4_MY14_Hev_Rx" SG_ 359 ElPw_D_Stat 1;
BA_ "U_CD4_MY14_Phev_Rx" SG_ 359 ElPw_D_Stat 1;
BA_ "GenSigTimeoutTime_OCS" SG_ 359 ElPw_D_Stat 6000;
BA_ "CrossOver_InfoCAN" SG_ 359 TrnAinTq_D_Qf 1;
BA_ "ContentDependant" SG_ 359 TrnAinTq_D_Qf 1;
BA_ "U_U55x_MY18_Gas_Rx" SG_ 357 CmbbEngTqMn_B_Actl 1;
BA_ "U_CD43_MY17_Gas_Rx" SG_ 357 CmbbEngTqMn_B_Actl 1;
BA_ "U_CD42_MY16_Gas_Rx" SG_ 357 CmbbEngTqMn_B_Actl 1;
BA_ "U_CD42_MY16_Diesel_Rx" SG_ 357 CmbbEngTqMn_B_Actl 1;
BA_ "U_V36X_MY16_5_Diesel_Rx" SG_ 357 CmbbEngTqMn_B_Actl 1;
BA_ "U_CD4_MY17_Phev_Rx" SG_ 357 CmbbEngTqMn_B_Actl 1;
BA_ "U_CD4_MY17_Hev_Rx" SG_ 357 CmbbEngTqMn_B_Actl 1;
BA_ "U_CD4_MY17_Gas_Rx" SG_ 357 CmbbEngTqMn_B_Actl 1;
BA_ "U_CD4_MY17_Diesel_Rx" SG_ 357 CmbbEngTqMn_B_Actl 1;
BA_ "U_CD43_MY16_Gas_Rx" SG_ 357 CmbbEngTqMn_B_Actl 1;
BA_ "U_CD42_MY15_Gas_Rx" SG_ 357 CmbbEngTqMn_B_Actl 1;
BA_ "U_CD42_MY15_Diesel_Rx" SG_ 357 CmbbEngTqMn_B_Actl 1;
BA_ "U_U55x_MY18_Gas_Rx" SG_ 357 CmbbDeny_B_ActlPrpl 1;
BA_ "U_CD43_MY17_Gas_Rx" SG_ 357 CmbbDeny_B_ActlPrpl 1;
BA_ "U_CD42_MY16_Gas_Rx" SG_ 357 CmbbDeny_B_ActlPrpl 1;
BA_ "U_CD42_MY16_Diesel_Rx" SG_ 357 CmbbDeny_B_ActlPrpl 1;
BA_ "U_V36X_MY16_5_Diesel_Rx" SG_ 357 CmbbDeny_B_ActlPrpl 1;
BA_ "U_CD4_MY17_Phev_Rx" SG_ 357 CmbbDeny_B_ActlPrpl 1;
BA_ "U_CD4_MY17_Hev_Rx" SG_ 357 CmbbDeny_B_ActlPrpl 1;
BA_ "U_CD4_MY17_Gas_Rx" SG_ 357 CmbbDeny_B_ActlPrpl 1;
BA_ "U_CD4_MY17_Diesel_Rx" SG_ 357 CmbbDeny_B_ActlPrpl 1;
BA_ "U_CD43_MY16_Gas_Rx" SG_ 357 CmbbDeny_B_ActlPrpl 1;
BA_ "U_CD42_MY15_Gas_Rx" SG_ 357 CmbbDeny_B_ActlPrpl 1;
BA_ "U_CD42_MY15_Diesel_Rx" SG_ 357 CmbbDeny_B_ActlPrpl 1;
BA_ "GenSigTimeoutTime_ABS_ESC" SG_ 357 AccStopMde_D_Rq 1000;
BA_ "U_U55x_MY18_Gas_Rx" SG_ 357 AccStopMde_D_Rq 1;
BA_ "U_CD43_MY17_Gas_Rx" SG_ 357 AccStopMde_D_Rq 1;
BA_ "U_CD42_MY16_Gas_Rx" SG_ 357 AccStopMde_D_Rq 1;
BA_ "U_CD42_MY16_Diesel_Rx" SG_ 357 AccStopMde_D_Rq 1;
BA_ "U_CD4_MY17_Phev_Rx" SG_ 357 AccStopMde_D_Rq 1;
BA_ "U_CD4_MY17_Hev_Rx" SG_ 357 AccStopMde_D_Rq 1;
BA_ "U_CD4_MY17_Gas_Rx" SG_ 357 AccStopMde_D_Rq 1;
BA_ "U_CD4_MY17_Diesel_Rx" SG_ 357 AccStopMde_D_Rq 1;
BA_ "U_CD4_MY14_Phev_Rx" SG_ 357 AccStopMde_D_Rq 1;
BA_ "U_CD4_MY14_Hev_Rx" SG_ 357 AccStopMde_D_Rq 1;
BA_ "U_CD4_MY14_Gas_Rx" SG_ 357 AccStopMde_D_Rq 1;
BA_ "U_CD4_MY14_Diesel_Rx" SG_ 357 AccStopMde_D_Rq 1;
BA_ "U_CD43_MY16_Gas_Rx" SG_ 357 AccStopMde_D_Rq 1;
BA_ "U_UP375_MY15_Diesel_Rx" SG_ 357 AccStopMde_D_Rq 1;
BA_ "U_UP375_MY15_Gas_Rx" SG_ 357 AccStopMde_D_Rq 1;
BA_ "U_CD42_MY15_Gas_Rx" SG_ 357 AccStopMde_D_Rq 1;
BA_ "U_CD42_MY15_Diesel_Rx" SG_ 357 AccStopMde_D_Rq 1;
BA_ "U_CD4_MY13_Phev_Rx" SG_ 357 AccStopMde_D_Rq 1;
BA_ "U_CD4_MY13_Hev_Rx" SG_ 357 AccStopMde_D_Rq 1;
BA_ "U_CD4_MY13_Gas_Rx" SG_ 357 AccStopMde_D_Rq 1;
BA_ "U_CD4_MY13_Diesel_Rx" SG_ 357 AccStopMde_D_Rq 1;
BA_ "U_CD4_MY13_Diesel_Rx" SG_ 357 BPedDrvAppl_D_QF 1;
BA_ "U_CD4_MY13_Gas_Rx" SG_ 357 BPedDrvAppl_D_QF 1;
BA_ "U_CD4_MY13_Hev_Rx" SG_ 357 BPedDrvAppl_D_QF 1;
BA_ "U_CD4_MY13_Phev_Rx" SG_ 357 BPedDrvAppl_D_QF 1;
BA_ "U_CD42_MY14_Diesel_Rx" SG_ 357 BPedDrvAppl_D_QF 1;
BA_ "U_CD42_MY14_Gas_Rx" SG_ 357 BPedDrvAppl_D_QF 1;
BA_ "U_P552_MY15_Gas_Rx" SG_ 357 BPedDrvAppl_D_QF 1;
BA_ "U_S550_MY15_Gas_Rx" SG_ 357 BPedDrvAppl_D_QF 1;
BA_ "U_C489_MY14_Gas_Rx" SG_ 357 BPedDrvAppl_D_QF 1;
BA_ "U_U502_MY15_Gas_Rx" SG_ 357 BPedDrvAppl_D_QF 1;
BA_ "U_UP375_MY15_Gas_Rx" SG_ 357 BPedDrvAppl_D_QF 1;
BA_ "U_UP375_MY15_Diesel_Rx" SG_ 357 BPedDrvAppl_D_QF 1;
BA_ "U_CD43_MY16_Gas_Rx" SG_ 357 BPedDrvAppl_D_QF 1;
BA_ "U_CD4_MY13_Diesel_Rx" SG_ 357 PrplTqMnSat_B_Actl 1;
BA_ "U_CD4_MY13_Gas_Rx" SG_ 357 PrplTqMnSat_B_Actl 1;
BA_ "U_CD4_MY13_Hev_Rx" SG_ 357 PrplTqMnSat_B_Actl 1;
BA_ "U_CD4_MY13_Phev_Rx" SG_ 357 PrplTqMnSat_B_Actl 1;
BA_ "U_CD42_MY14_Diesel_Rx" SG_ 357 PrplTqMnSat_B_Actl 1;
BA_ "U_CD42_MY14_Gas_Rx" SG_ 357 PrplTqMnSat_B_Actl 1;
BA_ "U_P552_MY15_Gas_Rx" SG_ 357 PrplTqMnSat_B_Actl 1;
BA_ "U_S550_MY15_Gas_Rx" SG_ 357 PrplTqMnSat_B_Actl 1;
BA_ "U_C489_MY14_Gas_Rx" SG_ 357 PrplTqMnSat_B_Actl 1;
BA_ "U_U502_MY15_Gas_Rx" SG_ 357 PrplTqMnSat_B_Actl 1;
BA_ "U_UP375_MY15_Gas_Rx" SG_ 357 PrplTqMnSat_B_Actl 1;
BA_ "U_UP375_MY15_Diesel_Rx" SG_ 357 PrplTqMnSat_B_Actl 1;
BA_ "U_CD43_MY16_Gas_Rx" SG_ 357 PrplTqMnSat_B_Actl 1;
BA_ "GenSigTimeoutTime_CCM" SG_ 357 PrplTqMnSat_B_Actl 1000;
BA_ "CrossOver_InfoCAN" SG_ 357 BpedDrvAppl_D_Actl 1;
BA_ "U_CD4_MY13_Diesel_Rx" SG_ 357 BpedDrvAppl_D_Actl 1;
BA_ "U_CD4_MY13_Gas_Rx" SG_ 357 BpedDrvAppl_D_Actl 1;
BA_ "U_CD4_MY13_Hev_Rx" SG_ 357 BpedDrvAppl_D_Actl 1;
BA_ "U_CD4_MY13_Phev_Rx" SG_ 357 BpedDrvAppl_D_Actl 1;
BA_ "U_CD42_MY14_Diesel_Rx" SG_ 357 BpedDrvAppl_D_Actl 1;
BA_ "U_CD42_MY14_Gas_Rx" SG_ 357 BpedDrvAppl_D_Actl 1;
BA_ "U_P552_MY15_Gas_Rx" SG_ 357 BpedDrvAppl_D_Actl 1;
BA_ "U_S550_MY15_Gas_Rx" SG_ 357 BpedDrvAppl_D_Actl 1;
BA_ "U_C489_MY14_Gas_Rx" SG_ 357 BpedDrvAppl_D_Actl 1;
BA_ "U_U502_MY15_Gas_Rx" SG_ 357 BpedDrvAppl_D_Actl 1;
BA_ "U_UP375_MY15_Gas_Rx" SG_ 357 BpedDrvAppl_D_Actl 1;
BA_ "U_UP375_MY15_Diesel_Rx" SG_ 357 BpedDrvAppl_D_Actl 1;
BA_ "U_CD43_MY16_Gas_Rx" SG_ 357 BpedDrvAppl_D_Actl 1;
BA_ "GenSigTimeoutTime_CCM" SG_ 357 BpedDrvAppl_D_Actl 1000;
BA_ "CrossOver_InfoCAN" SG_ 357 Veh_V_DsplyCcSet 1;
BA_ "U_CD4_MY13_Diesel_Rx" SG_ 357 AccEngStat_D_Actl 1;
BA_ "U_CD4_MY13_Gas_Rx" SG_ 357 AccEngStat_D_Actl 1;
BA_ "U_CD4_MY13_Hev_Rx" SG_ 357 AccEngStat_D_Actl 1;
BA_ "U_CD4_MY13_Phev_Rx" SG_ 357 AccEngStat_D_Actl 1;
BA_ "U_CD42_MY14_Diesel_Rx" SG_ 357 AccEngStat_D_Actl 1;
BA_ "U_CD42_MY14_Gas_Rx" SG_ 357 AccEngStat_D_Actl 1;
BA_ "U_P552_MY15_Gas_Rx" SG_ 357 AccEngStat_D_Actl 1;
BA_ "U_S550_MY15_Gas_Rx" SG_ 357 AccEngStat_D_Actl 1;
BA_ "U_C489_MY14_Gas_Rx" SG_ 357 AccEngStat_D_Actl 1;
BA_ "U_U502_MY15_Gas_Rx" SG_ 357 AccEngStat_D_Actl 1;
BA_ "U_UP375_MY15_Gas_Rx" SG_ 357 AccEngStat_D_Actl 1;
BA_ "U_UP375_MY15_Diesel_Rx" SG_ 357 AccEngStat_D_Actl 1;
BA_ "U_CD43_MY16_Gas_Rx" SG_ 357 AccEngStat_D_Actl 1;
BA_ "GenSigTimeoutTime_CCM" SG_ 357 AccEngStat_D_Actl 1000;
BA_ "U_CD4_MY13_Diesel_Rx" SG_ 357 CcMde_D_Actl 1;
BA_ "U_CD4_MY13_Gas_Rx" SG_ 357 CcMde_D_Actl 1;
BA_ "U_CD4_MY13_Hev_Rx" SG_ 357 CcMde_D_Actl 1;
BA_ "U_CD4_MY13_Phev_Rx" SG_ 357 CcMde_D_Actl 1;
BA_ "U_CD42_MY14_Diesel_Rx" SG_ 357 CcMde_D_Actl 1;
BA_ "U_CD42_MY14_Gas_Rx" SG_ 357 CcMde_D_Actl 1;
BA_ "U_P552_MY15_Gas_Rx" SG_ 357 CcMde_D_Actl 1;
BA_ "U_S550_MY15_Gas_Rx" SG_ 357 CcMde_D_Actl 1;
BA_ "U_C489_MY14_Gas_Rx" SG_ 357 CcMde_D_Actl 1;
BA_ "U_U502_MY15_Gas_Rx" SG_ 357 CcMde_D_Actl 1;
BA_ "U_UP375_MY15_Gas_Rx" SG_ 357 CcMde_D_Actl 1;
BA_ "U_UP375_MY15_Diesel_Rx" SG_ 357 CcMde_D_Actl 1;
BA_ "U_CD43_MY16_Gas_Rx" SG_ 357 CcMde_D_Actl 1;
BA_ "CrossOver_InfoCAN" SG_ 357 CcStat_D_Actl 1;
BA_ "U_CD4_MY13_Diesel_Rx" SG_ 357 CcStat_D_Actl 1;
BA_ "U_CD4_MY13_Gas_Rx" SG_ 357 CcStat_D_Actl 1;
BA_ "U_CD4_MY13_Hev_Rx" SG_ 357 CcStat_D_Actl 1;
BA_ "U_CD4_MY13_Phev_Rx" SG_ 357 CcStat_D_Actl 1;
BA_ "U_CD42_MY14_Diesel_Rx" SG_ 357 CcStat_D_Actl 1;
BA_ "U_CD42_MY14_Gas_Rx" SG_ 357 CcStat_D_Actl 1;
BA_ "U_P552_MY15_Gas_Rx" SG_ 357 CcStat_D_Actl 1;
BA_ "U_S550_MY15_Gas_Rx" SG_ 357 CcStat_D_Actl 1;
BA_ "U_C489_MY14_Gas_Rx" SG_ 357 CcStat_D_Actl 1;
BA_ "U_U502_MY15_Gas_Rx" SG_ 357 CcStat_D_Actl 1;
BA_ "U_UP375_MY15_Gas_Rx" SG_ 357 CcStat_D_Actl 1;
BA_ "U_UP375_MY15_Diesel_Rx" SG_ 357 CcStat_D_Actl 1;
BA_ "U_CD43_MY16_Gas_Rx" SG_ 357 CcStat_D_Actl 1;
BA_ "U_CD4_MY14_Diesel_Rx" SG_ 357 CcStat_D_Actl 1;
BA_ "U_CD4_MY14_Gas_Rx" SG_ 357 CcStat_D_Actl 1;
BA_ "U_CD4_MY14_Hev_Rx" SG_ 357 CcStat_D_Actl 1;
BA_ "U_CD4_MY14_Phev_Rx" SG_ 357 CcStat_D_Actl 1;
BA_ "GenSigTimeoutTime_OCS" SG_ 357 CcStat_D_Actl 6000;
BA_ "GenSigTimeoutTime_CCM" SG_ 357 CcStat_D_Actl 1000;
BA_ "GenSigTimeoutTime_ABS_ESC" SG_ 357 CcStat_D_Actl 1000;
BA_ "CrossOver_InfoCAN" SG_ 357 CcOvrrdActv_B_Actl 1;
BA_ "U_CD4_MY13_Diesel_Rx" SG_ 357 CcOvrrdActv_B_Actl 1;
BA_ "U_CD4_MY13_Gas_Rx" SG_ 357 CcOvrrdActv_B_Actl 1;
BA_ "U_CD4_MY13_Hev_Rx" SG_ 357 CcOvrrdActv_B_Actl 1;
BA_ "U_CD4_MY13_Phev_Rx" SG_ 357 CcOvrrdActv_B_Actl 1;
BA_ "U_CD42_MY14_Diesel_Rx" SG_ 357 CcOvrrdActv_B_Actl 1;
BA_ "U_CD42_MY14_Gas_Rx" SG_ 357 CcOvrrdActv_B_Actl 1;
BA_ "U_P552_MY15_Gas_Rx" SG_ 357 CcOvrrdActv_B_Actl 1;
BA_ "U_S550_MY15_Gas_Rx" SG_ 357 CcOvrrdActv_B_Actl 1;
BA_ "U_C489_MY14_Gas_Rx" SG_ 357 CcOvrrdActv_B_Actl 1;
BA_ "U_U502_MY15_Gas_Rx" SG_ 357 CcOvrrdActv_B_Actl 1;
BA_ "U_UP375_MY15_Gas_Rx" SG_ 357 CcOvrrdActv_B_Actl 1;
BA_ "U_UP375_MY15_Diesel_Rx" SG_ 357 CcOvrrdActv_B_Actl 1;
BA_ "U_CD43_MY16_Gas_Rx" SG_ 357 CcOvrrdActv_B_Actl 1;
BA_ "GenSigTimeoutTime_CCM" SG_ 357 CcOvrrdActv_B_Actl 1000;
BA_ "GenSigSendType" SG_ 1461 PSCM_AutoSar_Network_Mgmt 3;
BA_ "U_CD4_MY13_Diesel_Rx" SG_ 1461 PSCM_AutoSar_Network_Mgmt 1;
BA_ "U_CD4_MY13_Gas_Rx" SG_ 1461 PSCM_AutoSar_Network_Mgmt 1;
BA_ "U_CD4_MY13_Hev_Rx" SG_ 1461 PSCM_AutoSar_Network_Mgmt 1;
BA_ "U_CD4_MY13_Phev_Rx" SG_ 1461 PSCM_AutoSar_Network_Mgmt 1;
BA_ "U_CD42_MY14_Diesel_Rx" SG_ 1461 PSCM_AutoSar_Network_Mgmt 1;
BA_ "U_CD42_MY14_Gas_Rx" SG_ 1461 PSCM_AutoSar_Network_Mgmt 1;
BA_ "U_P552_MY15_Gas_Rx" SG_ 1461 PSCM_AutoSar_Network_Mgmt 1;
BA_ "U_S550_MY15_Gas_Rx" SG_ 1461 PSCM_AutoSar_Network_Mgmt 1;
BA_ "U_C489_MY14_Gas_Rx" SG_ 1461 PSCM_AutoSar_Network_Mgmt 1;
BA_ "U_U502_MY15_Gas_Rx" SG_ 1461 PSCM_AutoSar_Network_Mgmt 1;
BA_ "U_UP375_MY15_Gas_Rx" SG_ 1461 PSCM_AutoSar_Network_Mgmt 1;
BA_ "U_UP375_MY15_Diesel_Rx" SG_ 1461 PSCM_AutoSar_Network_Mgmt 1;
BA_ "U_CD43_MY16_Gas_Rx" SG_ 1461 PSCM_AutoSar_Network_Mgmt 1;
BA_ "U_CD4_MY13_Diesel_Tx" SG_ 1461 PSCM_AutoSar_Network_Mgmt 1;
BA_ "U_CD4_MY13_Gas_Tx" SG_ 1461 PSCM_AutoSar_Network_Mgmt 1;
BA_ "U_CD4_MY13_Hev_Tx" SG_ 1461 PSCM_AutoSar_Network_Mgmt 1;
BA_ "U_CD4_MY13_Phev_Tx" SG_ 1461 PSCM_AutoSar_Network_Mgmt 1;
BA_ "U_CD42_MY14_Diesel_Tx" SG_ 1461 PSCM_AutoSar_Network_Mgmt 1;
BA_ "U_CD42_MY14_Gas_Tx" SG_ 1461 PSCM_AutoSar_Network_Mgmt 1;
BA_ "U_P552_MY15_Gas_Tx" SG_ 1461 PSCM_AutoSar_Network_Mgmt 1;
BA_ "U_S550_MY15_Gas_Tx" SG_ 1461 PSCM_AutoSar_Network_Mgmt 1;
BA_ "U_C489_MY14_Gas_Tx" SG_ 1461 PSCM_AutoSar_Network_Mgmt 1;
BA_ "U_U502_MY15_Gas_Tx" SG_ 1461 PSCM_AutoSar_Network_Mgmt 1;
BA_ "U_UP375_MY15_Gas_Tx" SG_ 1461 PSCM_AutoSar_Network_Mgmt 1;
BA_ "U_UP375_MY15_Diesel_Tx" SG_ 1461 PSCM_AutoSar_Network_Mgmt 1;
BA_ "U_CD43_MY16_Gas_Tx" SG_ 1461 PSCM_AutoSar_Network_Mgmt 1;
BA_ "U_CD4_MY13_Diesel_Rx" SG_ 390 AccStopStat_B_Rq 1;
BA_ "U_CD4_MY13_Gas_Rx" SG_ 390 AccStopStat_B_Rq 1;
BA_ "U_CD4_MY13_Hev_Rx" SG_ 390 AccStopStat_B_Rq 1;
BA_ "U_CD4_MY13_Phev_Rx" SG_ 390 AccStopStat_B_Rq 1;
BA_ "U_CD42_MY15_Diesel_Rx" SG_ 390 AccStopStat_B_Rq 1;
BA_ "U_CD42_MY15_Gas_Rx" SG_ 390 AccStopStat_B_Rq 1;
BA_ "U_CD43_MY16_Gas_Rx" SG_ 390 AccStopStat_B_Rq 1;
BA_ "U_CD4_MY17_Diesel_Rx" SG_ 390 AccStopStat_B_Rq 1;
BA_ "U_CD4_MY17_Gas_Rx" SG_ 390 AccStopStat_B_Rq 1;
BA_ "U_CD4_MY17_Hev_Rx" SG_ 390 AccStopStat_B_Rq 1;
BA_ "U_CD4_MY17_Phev_Rx" SG_ 390 AccStopStat_B_Rq 1;
BA_ "U_C489_MY17_Gas_Rx" SG_ 390 AccStopStat_B_Rq 1;
BA_ "U_CD42_MY16_Diesel_Rx" SG_ 390 AccStopStat_B_Rq 1;
BA_ "U_CD42_MY16_Gas_Rx" SG_ 390 AccStopStat_B_Rq 1;
BA_ "U_CD43_MY17_Gas_Rx" SG_ 390 AccStopStat_B_Rq 1;
BA_ "U_U55x_MY18_Gas_Rx" SG_ 390 AccStopStat_B_Rq 1;
BA_ "U_CD4_MY13_Diesel_Tx" SG_ 390 AccStopStat_B_Rq 1;
BA_ "U_CD4_MY13_Gas_Tx" SG_ 390 AccStopStat_B_Rq 1;
BA_ "U_CD4_MY13_Hev_Tx" SG_ 390 AccStopStat_B_Rq 1;
BA_ "U_CD4_MY13_Phev_Tx" SG_ 390 AccStopStat_B_Rq 1;
BA_ "U_CD42_MY15_Diesel_Tx" SG_ 390 AccStopStat_B_Rq 1;
BA_ "U_CD42_MY15_Gas_Tx" SG_ 390 AccStopStat_B_Rq 1;
BA_ "U_UP375_MY15_Gas_Tx" SG_ 390 AccStopStat_B_Rq 1;
BA_ "U_UP375_MY15_Diesel_Tx" SG_ 390 AccStopStat_B_Rq 1;
BA_ "U_CD43_MY16_Gas_Tx" SG_ 390 AccStopStat_B_Rq 1;
BA_ "U_CD4_MY14_Diesel_Tx" SG_ 390 AccStopStat_B_Rq 1;
BA_ "U_CD4_MY14_Gas_Tx" SG_ 390 AccStopStat_B_Rq 1;
BA_ "U_CD4_MY14_Hev_Tx" SG_ 390 AccStopStat_B_Rq 1;
BA_ "U_CD4_MY14_Phev_Tx" SG_ 390 AccStopStat_B_Rq 1;
BA_ "U_CD4_MY17_Diesel_Tx" SG_ 390 AccStopStat_B_Rq 1;
BA_ "U_CD4_MY17_Gas_Tx" SG_ 390 AccStopStat_B_Rq 1;
BA_ "U_CD4_MY17_Hev_Tx" SG_ 390 AccStopStat_B_Rq 1;
BA_ "U_CD4_MY17_Phev_Tx" SG_ 390 AccStopStat_B_Rq 1;
BA_ "U_CD42_MY16_Diesel_Tx" SG_ 390 AccStopStat_B_Rq 1;
BA_ "U_CD42_MY16_Gas_Tx" SG_ 390 AccStopStat_B_Rq 1;
BA_ "U_CD43_MY17_Gas_Tx" SG_ 390 AccStopStat_B_Rq 1;
BA_ "U_U55x_MY18_Gas_Tx" SG_ 390 AccStopStat_B_Rq 1;
BA_ "GenSigTimeoutTime_ABS_ESC" SG_ 390 AccStopStat_B_Rq 1000;
BA_ "WakeupSignal" SG_ 390 AccResumEnbl_B_Rq 1;
BA_ "U_CD4_MY13_Diesel_Rx" SG_ 390 AccResumEnbl_B_Rq 1;
BA_ "U_CD4_MY13_Gas_Rx" SG_ 390 AccResumEnbl_B_Rq 1;
BA_ "U_CD4_MY13_Hev_Rx" SG_ 390 AccResumEnbl_B_Rq 1;
BA_ "U_CD4_MY13_Phev_Rx" SG_ 390 AccResumEnbl_B_Rq 1;
BA_ "U_CD42_MY15_Diesel_Rx" SG_ 390 AccResumEnbl_B_Rq 1;
BA_ "U_CD42_MY15_Gas_Rx" SG_ 390 AccResumEnbl_B_Rq 1;
BA_ "U_P552_MY15_Gas_Rx" SG_ 390 AccResumEnbl_B_Rq 1;
BA_ "U_S550_MY15_Gas_Rx" SG_ 390 AccResumEnbl_B_Rq 1;
BA_ "U_C489_MY14_Gas_Rx" SG_ 390 AccResumEnbl_B_Rq 1;
BA_ "U_U502_MY16_Gas_Rx" SG_ 390 AccResumEnbl_B_Rq 1;
BA_ "U_B479_MY17_Gas_Rx" SG_ 390 AccResumEnbl_B_Rq 1;
BA_ "U_UP375_MY15_Gas_Rx" SG_ 390 AccResumEnbl_B_Rq 1;
BA_ "U_UP375_MY15_Diesel_Rx" SG_ 390 AccResumEnbl_B_Rq 1;
BA_ "U_CD4_MY13_Diesel_Tx" SG_ 390 AccResumEnbl_B_Rq 1;
BA_ "U_CD4_MY13_Gas_Tx" SG_ 390 AccResumEnbl_B_Rq 1;
BA_ "U_CD4_MY13_Hev_Tx" SG_ 390 AccResumEnbl_B_Rq 1;
BA_ "U_CD4_MY13_Phev_Tx" SG_ 390 AccResumEnbl_B_Rq 1;
BA_ "U_CD42_MY15_Diesel_Tx" SG_ 390 AccResumEnbl_B_Rq 1;
BA_ "U_CD42_MY15_Gas_Tx" SG_ 390 AccResumEnbl_B_Rq 1;
BA_ "U_UP375_MY15_Gas_Tx" SG_ 390 AccResumEnbl_B_Rq 1;
BA_ "U_UP375_MY15_Diesel_Tx" SG_ 390 AccResumEnbl_B_Rq 1;
BA_ "U_CD43_MY16_Gas_Tx" SG_ 390 AccResumEnbl_B_Rq 1;
BA_ "U_CD4_MY14_Diesel_Tx" SG_ 390 AccResumEnbl_B_Rq 1;
BA_ "U_CD4_MY14_Gas_Tx" SG_ 390 AccResumEnbl_B_Rq 1;
BA_ "U_CD4_MY14_Hev_Tx" SG_ 390 AccResumEnbl_B_Rq 1;
BA_ "U_CD4_MY14_Phev_Tx" SG_ 390 AccResumEnbl_B_Rq 1;
BA_ "U_CD4_MY17_Diesel_Tx" SG_ 390 AccResumEnbl_B_Rq 1;
BA_ "U_CD4_MY17_Gas_Tx" SG_ 390 AccResumEnbl_B_Rq 1;
BA_ "U_CD4_MY17_Hev_Tx" SG_ 390 AccResumEnbl_B_Rq 1;
BA_ "U_CD4_MY17_Phev_Tx" SG_ 390 AccResumEnbl_B_Rq 1;
BA_ "U_CD42_MY16_Diesel_Tx" SG_ 390 AccResumEnbl_B_Rq 1;
BA_ "U_CD42_MY16_Gas_Tx" SG_ 390 AccResumEnbl_B_Rq 1;
BA_ "U_CD43_MY17_Gas_Tx" SG_ 390 AccResumEnbl_B_Rq 1;
BA_ "U_U55x_MY18_Gas_Tx" SG_ 390 AccResumEnbl_B_Rq 1;
BA_ "GenSigStartValue" SG_ 390 AccBrkTot_A_Rq 5129;
BA_ "U_U502_MY15_Gas_Rx" SG_ 390 AccBrkTot_A_Rq 1;
BA_ "U_UP375_MY15_Gas_Rx" SG_ 390 AccBrkTot_A_Rq 1;
BA_ "U_UP375_MY15_Diesel_Rx" SG_ 390 AccBrkTot_A_Rq 1;
BA_ "U_CD43_MY16_Gas_Rx" SG_ 390 AccBrkTot_A_Rq 1;
BA_ "U_CD4_MY13_Diesel_Tx" SG_ 390 AccBrkTot_A_Rq 1;
BA_ "U_CD4_MY13_Gas_Tx" SG_ 390 AccBrkTot_A_Rq 1;
BA_ "U_CD4_MY13_Hev_Tx" SG_ 390 AccBrkTot_A_Rq 1;
BA_ "U_CD4_MY13_Phev_Tx" SG_ 390 AccBrkTot_A_Rq 1;
BA_ "U_CD42_MY14_Diesel_Tx" SG_ 390 AccBrkTot_A_Rq 1;
BA_ "U_CD42_MY14_Gas_Tx" SG_ 390 AccBrkTot_A_Rq 1;
BA_ "U_P552_MY15_Gas_Tx" SG_ 390 AccBrkTot_A_Rq 1;
BA_ "U_S550_MY15_Gas_Tx" SG_ 390 AccBrkTot_A_Rq 1;
BA_ "U_C489_MY14_Gas_Tx" SG_ 390 AccBrkTot_A_Rq 1;
BA_ "U_U502_MY15_Gas_Tx" SG_ 390 AccBrkTot_A_Rq 1;
BA_ "U_UP375_MY15_Gas_Tx" SG_ 390 AccBrkTot_A_Rq 1;
BA_ "U_UP375_MY15_Diesel_Tx" SG_ 390 AccBrkTot_A_Rq 1;
BA_ "U_CD43_MY16_Gas_Tx" SG_ 390 AccBrkTot_A_Rq 1;
BA_ "GenSigTimeoutTime_ABS_ESC" SG_ 390 AccBrkTot_A_Rq 1000;
BA_ "U_CD4_MY13_Diesel_Tx" SG_ 390 AccPrpl_A_Pred 1;
BA_ "U_CD4_MY13_Gas_Tx" SG_ 390 AccPrpl_A_Pred 1;
BA_ "U_CD4_MY13_Hev_Tx" SG_ 390 AccPrpl_A_Pred 1;
BA_ "U_CD4_MY13_Phev_Tx" SG_ 390 AccPrpl_A_Pred 1;
BA_ "U_CD42_MY14_Diesel_Tx" SG_ 390 AccPrpl_A_Pred 1;
BA_ "U_CD42_MY14_Gas_Tx" SG_ 390 AccPrpl_A_Pred 1;
BA_ "U_P552_MY15_Gas_Tx" SG_ 390 AccPrpl_A_Pred 1;
BA_ "U_S550_MY15_Gas_Tx" SG_ 390 AccPrpl_A_Pred 1;
BA_ "U_C489_MY14_Gas_Tx" SG_ 390 AccPrpl_A_Pred 1;
BA_ "U_U502_MY15_Gas_Tx" SG_ 390 AccPrpl_A_Pred 1;
BA_ "U_UP375_MY15_Gas_Tx" SG_ 390 AccPrpl_A_Pred 1;
BA_ "U_UP375_MY15_Diesel_Tx" SG_ 390 AccPrpl_A_Pred 1;
BA_ "U_CD43_MY16_Gas_Tx" SG_ 390 AccPrpl_A_Pred 1;
BA_ "U_CD4_MY13_Diesel_Tx" SG_ 390 AccVeh_V_Trg 1;
BA_ "U_CD4_MY13_Gas_Tx" SG_ 390 AccVeh_V_Trg 1;
BA_ "U_CD4_MY13_Hev_Tx" SG_ 390 AccVeh_V_Trg 1;
BA_ "U_CD4_MY13_Phev_Tx" SG_ 390 AccVeh_V_Trg 1;
BA_ "U_CD42_MY14_Diesel_Tx" SG_ 390 AccVeh_V_Trg 1;
BA_ "U_CD42_MY14_Gas_Tx" SG_ 390 AccVeh_V_Trg 1;
BA_ "U_P552_MY15_Gas_Tx" SG_ 390 AccVeh_V_Trg 1;
BA_ "U_S550_MY15_Gas_Tx" SG_ 390 AccVeh_V_Trg 1;
BA_ "U_C489_MY14_Gas_Tx" SG_ 390 AccVeh_V_Trg 1;
BA_ "U_U502_MY15_Gas_Tx" SG_ 390 AccVeh_V_Trg 1;
BA_ "U_UP375_MY15_Gas_Tx" SG_ 390 AccVeh_V_Trg 1;
BA_ "U_UP375_MY15_Diesel_Tx" SG_ 390 AccVeh_V_Trg 1;
BA_ "U_CD43_MY16_Gas_Tx" SG_ 390 AccVeh_V_Trg 1;
BA_ "U_CD4_MY13_Diesel_Tx" SG_ 390 AccBrkPrkEl_B_Rq 1;
BA_ "U_CD4_MY13_Gas_Tx" SG_ 390 AccBrkPrkEl_B_Rq 1;
BA_ "U_CD4_MY13_Hev_Tx" SG_ 390 AccBrkPrkEl_B_Rq 1;
BA_ "U_CD4_MY13_Phev_Tx" SG_ 390 AccBrkPrkEl_B_Rq 1;
BA_ "U_CD42_MY14_Diesel_Tx" SG_ 390 AccBrkPrkEl_B_Rq 1;
BA_ "U_CD42_MY14_Gas_Tx" SG_ 390 AccBrkPrkEl_B_Rq 1;
BA_ "U_P552_MY15_Gas_Tx" SG_ 390 AccBrkPrkEl_B_Rq 1;
BA_ "U_S550_MY15_Gas_Tx" SG_ 390 AccBrkPrkEl_B_Rq 1;
BA_ "U_C489_MY14_Gas_Tx" SG_ 390 AccBrkPrkEl_B_Rq 1;
BA_ "U_U502_MY15_Gas_Tx" SG_ 390 AccBrkPrkEl_B_Rq 1;
BA_ "U_UP375_MY15_Gas_Tx" SG_ 390 AccBrkPrkEl_B_Rq 1;
BA_ "U_UP375_MY15_Diesel_Tx" SG_ 390 AccBrkPrkEl_B_Rq 1;
BA_ "U_CD43_MY16_Gas_Tx" SG_ 390 AccBrkPrkEl_B_Rq 1;
BA_ "U_CD4_MY13_Diesel_Rx" SG_ 390 Cmbb_B_Enbl 1;
BA_ "U_CD4_MY13_Gas_Rx" SG_ 390 Cmbb_B_Enbl 1;
BA_ "U_CD4_MY13_Hev_Rx" SG_ 390 Cmbb_B_Enbl 1;
BA_ "U_CD4_MY13_Phev_Rx" SG_ 390 Cmbb_B_Enbl 1;
BA_ "U_CD42_MY14_Diesel_Rx" SG_ 390 Cmbb_B_Enbl 1;
BA_ "U_CD42_MY14_Gas_Rx" SG_ 390 Cmbb_B_Enbl 1;
BA_ "U_P552_MY15_Gas_Rx" SG_ 390 Cmbb_B_Enbl 1;
BA_ "U_S550_MY15_Gas_Rx" SG_ 390 Cmbb_B_Enbl 1;
BA_ "U_C489_MY14_Gas_Rx" SG_ 390 Cmbb_B_Enbl 1;
BA_ "U_U502_MY15_Gas_Rx" SG_ 390 Cmbb_B_Enbl 1;
BA_ "U_UP375_MY15_Gas_Rx" SG_ 390 Cmbb_B_Enbl 1;
BA_ "U_UP375_MY15_Diesel_Rx" SG_ 390 Cmbb_B_Enbl 1;
BA_ "U_CD43_MY16_Gas_Rx" SG_ 390 Cmbb_B_Enbl 1;
BA_ "U_CD4_MY13_Diesel_Tx" SG_ 390 Cmbb_B_Enbl 1;
BA_ "U_CD4_MY13_Gas_Tx" SG_ 390 Cmbb_B_Enbl 1;
BA_ "U_CD4_MY13_Hev_Tx" SG_ 390 Cmbb_B_Enbl 1;
BA_ "U_CD4_MY13_Phev_Tx" SG_ 390 Cmbb_B_Enbl 1;
BA_ "U_CD42_MY14_Diesel_Tx" SG_ 390 Cmbb_B_Enbl 1;
BA_ "U_CD42_MY14_Gas_Tx" SG_ 390 Cmbb_B_Enbl 1;
BA_ "U_P552_MY15_Gas_Tx" SG_ 390 Cmbb_B_Enbl 1;
BA_ "U_S550_MY15_Gas_Tx" SG_ 390 Cmbb_B_Enbl 1;
BA_ "U_C489_MY14_Gas_Tx" SG_ 390 Cmbb_B_Enbl 1;
BA_ "U_U502_MY15_Gas_Tx" SG_ 390 Cmbb_B_Enbl 1;
BA_ "U_UP375_MY15_Gas_Tx" SG_ 390 Cmbb_B_Enbl 1;
BA_ "U_UP375_MY15_Diesel_Tx" SG_ 390 Cmbb_B_Enbl 1;
BA_ "U_CD43_MY16_Gas_Tx" SG_ 390 Cmbb_B_Enbl 1;
BA_ "U_CD4_MY13_Diesel_Rx" SG_ 390 CmbbOvrrd_B_RqDrv 1;
BA_ "U_CD4_MY13_Gas_Rx" SG_ 390 CmbbOvrrd_B_RqDrv 1;
BA_ "U_CD4_MY13_Hev_Rx" SG_ 390 CmbbOvrrd_B_RqDrv 1;
BA_ "U_CD4_MY13_Phev_Rx" SG_ 390 CmbbOvrrd_B_RqDrv 1;
BA_ "U_CD42_MY14_Diesel_Rx" SG_ 390 CmbbOvrrd_B_RqDrv 1;
BA_ "U_CD42_MY14_Gas_Rx" SG_ 390 CmbbOvrrd_B_RqDrv 1;
BA_ "U_P552_MY15_Gas_Rx" SG_ 390 CmbbOvrrd_B_RqDrv 1;
BA_ "U_S550_MY15_Gas_Rx" SG_ 390 CmbbOvrrd_B_RqDrv 1;
BA_ "U_C489_MY14_Gas_Rx" SG_ 390 CmbbOvrrd_B_RqDrv 1;
BA_ "U_U502_MY15_Gas_Rx" SG_ 390 CmbbOvrrd_B_RqDrv 1;
BA_ "U_UP375_MY15_Gas_Rx" SG_ 390 CmbbOvrrd_B_RqDrv 1;
BA_ "U_UP375_MY15_Diesel_Rx" SG_ 390 CmbbOvrrd_B_RqDrv 1;
BA_ "U_CD43_MY16_Gas_Rx" SG_ 390 CmbbOvrrd_B_RqDrv 1;
BA_ "U_CD4_MY13_Diesel_Tx" SG_ 390 CmbbOvrrd_B_RqDrv 1;
BA_ "U_CD4_MY13_Gas_Tx" SG_ 390 CmbbOvrrd_B_RqDrv 1;
BA_ "U_CD4_MY13_Hev_Tx" SG_ 390 CmbbOvrrd_B_RqDrv 1;
BA_ "U_CD4_MY13_Phev_Tx" SG_ 390 CmbbOvrrd_B_RqDrv 1;
BA_ "U_CD42_MY14_Diesel_Tx" SG_ 390 CmbbOvrrd_B_RqDrv 1;
BA_ "U_CD42_MY14_Gas_Tx" SG_ 390 CmbbOvrrd_B_RqDrv 1;
BA_ "U_P552_MY15_Gas_Tx" SG_ 390 CmbbOvrrd_B_RqDrv 1;
BA_ "U_S550_MY15_Gas_Tx" SG_ 390 CmbbOvrrd_B_RqDrv 1;
BA_ "U_C489_MY14_Gas_Tx" SG_ 390 CmbbOvrrd_B_RqDrv 1;
BA_ "U_U502_MY15_Gas_Tx" SG_ 390 CmbbOvrrd_B_RqDrv 1;
BA_ "U_UP375_MY15_Gas_Tx" SG_ 390 CmbbOvrrd_B_RqDrv 1;
BA_ "U_UP375_MY15_Diesel_Tx" SG_ 390 CmbbOvrrd_B_RqDrv 1;
BA_ "U_CD43_MY16_Gas_Tx" SG_ 390 CmbbOvrrd_B_RqDrv 1;
BA_ "U_CD4_MY13_Diesel_Rx" SG_ 390 CmbbDeny_B_Actl 1;
BA_ "U_CD4_MY13_Gas_Rx" SG_ 390 CmbbDeny_B_Actl 1;
BA_ "U_CD4_MY13_Hev_Rx" SG_ 390 CmbbDeny_B_Actl 1;
BA_ "U_CD4_MY13_Phev_Rx" SG_ 390 CmbbDeny_B_Actl 1;
BA_ "U_CD42_MY14_Diesel_Rx" SG_ 390 CmbbDeny_B_Actl 1;
BA_ "U_CD42_MY14_Gas_Rx" SG_ 390 CmbbDeny_B_Actl 1;
BA_ "U_P552_MY15_Gas_Rx" SG_ 390 CmbbDeny_B_Actl 1;
BA_ "U_S550_MY15_Gas_Rx" SG_ 390 CmbbDeny_B_Actl 1;
BA_ "U_C489_MY14_Gas_Rx" SG_ 390 CmbbDeny_B_Actl 1;
BA_ "U_U502_MY15_Gas_Rx" SG_ 390 CmbbDeny_B_Actl 1;
BA_ "U_UP375_MY15_Gas_Rx" SG_ 390 CmbbDeny_B_Actl 1;
BA_ "U_UP375_MY15_Diesel_Rx" SG_ 390 CmbbDeny_B_Actl 1;
BA_ "U_CD43_MY16_Gas_Rx" SG_ 390 CmbbDeny_B_Actl 1;
BA_ "U_CD4_MY13_Diesel_Tx" SG_ 390 CmbbDeny_B_Actl 1;
BA_ "U_CD4_MY13_Gas_Tx" SG_ 390 CmbbDeny_B_Actl 1;
BA_ "U_CD4_MY13_Hev_Tx" SG_ 390 CmbbDeny_B_Actl 1;
BA_ "U_CD4_MY13_Phev_Tx" SG_ 390 CmbbDeny_B_Actl 1;
BA_ "U_CD42_MY14_Diesel_Tx" SG_ 390 CmbbDeny_B_Actl 1;
BA_ "U_CD42_MY14_Gas_Tx" SG_ 390 CmbbDeny_B_Actl 1;
BA_ "U_P552_MY15_Gas_Tx" SG_ 390 CmbbDeny_B_Actl 1;
BA_ "U_S550_MY15_Gas_Tx" SG_ 390 CmbbDeny_B_Actl 1;
BA_ "U_C489_MY14_Gas_Tx" SG_ 390 CmbbDeny_B_Actl 1;
BA_ "U_U502_MY15_Gas_Tx" SG_ 390 CmbbDeny_B_Actl 1;
BA_ "U_UP375_MY15_Gas_Tx" SG_ 390 CmbbDeny_B_Actl 1;
BA_ "U_UP375_MY15_Diesel_Tx" SG_ 390 CmbbDeny_B_Actl 1;
BA_ "U_CD43_MY16_Gas_Tx" SG_ 390 CmbbDeny_B_Actl 1;
BA_ "GenSigTimeoutTime_ABS_ESC" SG_ 390 CmbbDeny_B_Actl 1000;
BA_ "U_CD4_MY13_Diesel_Tx" SG_ 390 CmbbEngTqMn_B_Rq 1;
BA_ "U_CD4_MY13_Gas_Tx" SG_ 390 CmbbEngTqMn_B_Rq 1;
BA_ "U_CD4_MY13_Hev_Tx" SG_ 390 CmbbEngTqMn_B_Rq 1;
BA_ "U_CD4_MY13_Phev_Tx" SG_ 390 CmbbEngTqMn_B_Rq 1;
BA_ "U_CD42_MY14_Diesel_Tx" SG_ 390 CmbbEngTqMn_B_Rq 1;
BA_ "U_CD42_MY14_Gas_Tx" SG_ 390 CmbbEngTqMn_B_Rq 1;
BA_ "U_P552_MY15_Gas_Tx" SG_ 390 CmbbEngTqMn_B_Rq 1;
BA_ "U_S550_MY15_Gas_Tx" SG_ 390 CmbbEngTqMn_B_Rq 1;
BA_ "U_C489_MY14_Gas_Tx" SG_ 390 CmbbEngTqMn_B_Rq 1;
BA_ "U_U502_MY15_Gas_Tx" SG_ 390 CmbbEngTqMn_B_Rq 1;
BA_ "U_UP375_MY15_Gas_Tx" SG_ 390 CmbbEngTqMn_B_Rq 1;
BA_ "U_UP375_MY15_Diesel_Tx" SG_ 390 CmbbEngTqMn_B_Rq 1;
BA_ "U_CD43_MY16_Gas_Tx" SG_ 390 CmbbEngTqMn_B_Rq 1;
BA_ "U_CD4_MY13_Diesel_Tx" SG_ 390 AccPrpl_A_Rq 1;
BA_ "U_CD4_MY13_Gas_Tx" SG_ 390 AccPrpl_A_Rq 1;
BA_ "U_CD4_MY13_Hev_Tx" SG_ 390 AccPrpl_A_Rq 1;
BA_ "U_CD4_MY13_Phev_Tx" SG_ 390 AccPrpl_A_Rq 1;
BA_ "U_CD42_MY14_Diesel_Tx" SG_ 390 AccPrpl_A_Rq 1;
BA_ "U_CD42_MY14_Gas_Tx" SG_ 390 AccPrpl_A_Rq 1;
BA_ "U_P552_MY15_Gas_Tx" SG_ 390 AccPrpl_A_Rq 1;
BA_ "U_S550_MY15_Gas_Tx" SG_ 390 AccPrpl_A_Rq 1;
BA_ "U_C489_MY14_Gas_Tx" SG_ 390 AccPrpl_A_Rq 1;
BA_ "U_U502_MY15_Gas_Tx" SG_ 390 AccPrpl_A_Rq 1;
BA_ "U_UP375_MY15_Gas_Tx" SG_ 390 AccPrpl_A_Rq 1;
BA_ "U_UP375_MY15_Diesel_Tx" SG_ 390 AccPrpl_A_Rq 1;
BA_ "U_CD43_MY16_Gas_Tx" SG_ 390 AccPrpl_A_Rq 1;
BA_ "U_CD4_MY13_Diesel_Tx" SG_ 390 AccDeny_B_Rq 1;
BA_ "U_CD4_MY13_Gas_Tx" SG_ 390 AccDeny_B_Rq 1;
BA_ "U_CD4_MY13_Hev_Tx" SG_ 390 AccDeny_B_Rq 1;
BA_ "U_CD4_MY13_Phev_Tx" SG_ 390 AccDeny_B_Rq 1;
BA_ "U_CD42_MY14_Diesel_Tx" SG_ 390 AccDeny_B_Rq 1;
BA_ "U_CD42_MY14_Gas_Tx" SG_ 390 AccDeny_B_Rq 1;
BA_ "U_P552_MY15_Gas_Tx" SG_ 390 AccDeny_B_Rq 1;
BA_ "U_S550_MY15_Gas_Tx" SG_ 390 AccDeny_B_Rq 1;
BA_ "U_C489_MY14_Gas_Tx" SG_ 390 AccDeny_B_Rq 1;
BA_ "U_U502_MY15_Gas_Tx" SG_ 390 AccDeny_B_Rq 1;
BA_ "U_UP375_MY15_Gas_Tx" SG_ 390 AccDeny_B_Rq 1;
BA_ "U_UP375_MY15_Diesel_Tx" SG_ 390 AccDeny_B_Rq 1;
BA_ "U_CD43_MY16_Gas_Tx" SG_ 390 AccDeny_B_Rq 1;
BA_ "U_CD4_MY13_Diesel_Tx" SG_ 390 AccCancl_B_Rq 1;
BA_ "U_CD4_MY13_Gas_Tx" SG_ 390 AccCancl_B_Rq 1;
BA_ "U_CD4_MY13_Hev_Tx" SG_ 390 AccCancl_B_Rq 1;
BA_ "U_CD4_MY13_Phev_Tx" SG_ 390 AccCancl_B_Rq 1;
BA_ "U_CD42_MY14_Diesel_Tx" SG_ 390 AccCancl_B_Rq 1;
BA_ "U_CD42_MY14_Gas_Tx" SG_ 390 AccCancl_B_Rq 1;
BA_ "U_P552_MY15_Gas_Tx" SG_ 390 AccCancl_B_Rq 1;
BA_ "U_S550_MY15_Gas_Tx" SG_ 390 AccCancl_B_Rq 1;
BA_ "U_C489_MY14_Gas_Tx" SG_ 390 AccCancl_B_Rq 1;
BA_ "U_U502_MY15_Gas_Tx" SG_ 390 AccCancl_B_Rq 1;
BA_ "U_UP375_MY15_Gas_Tx" SG_ 390 AccCancl_B_Rq 1;
BA_ "U_UP375_MY15_Diesel_Tx" SG_ 390 AccCancl_B_Rq 1;
BA_ "U_CD43_MY16_Gas_Tx" SG_ 390 AccCancl_B_Rq 1;
BA_ "U_CD4_MY13_Diesel_Rx" SG_ 390 AccBrkPrchg_B_Rq 1;
BA_ "U_CD4_MY13_Gas_Rx" SG_ 390 AccBrkPrchg_B_Rq 1;
BA_ "U_CD4_MY13_Hev_Rx" SG_ 390 AccBrkPrchg_B_Rq 1;
BA_ "U_CD4_MY13_Phev_Rx" SG_ 390 AccBrkPrchg_B_Rq 1;
BA_ "U_CD42_MY14_Diesel_Rx" SG_ 390 AccBrkPrchg_B_Rq 1;
BA_ "U_CD42_MY14_Gas_Rx" SG_ 390 AccBrkPrchg_B_Rq 1;
BA_ "U_P552_MY15_Gas_Rx" SG_ 390 AccBrkPrchg_B_Rq 1;
BA_ "U_S550_MY15_Gas_Rx" SG_ 390 AccBrkPrchg_B_Rq 1;
BA_ "U_C489_MY14_Gas_Rx" SG_ 390 AccBrkPrchg_B_Rq 1;
BA_ "U_U502_MY15_Gas_Rx" SG_ 390 AccBrkPrchg_B_Rq 1;
BA_ "U_UP375_MY15_Gas_Rx" SG_ 390 AccBrkPrchg_B_Rq 1;
BA_ "U_UP375_MY15_Diesel_Rx" SG_ 390 AccBrkPrchg_B_Rq 1;
BA_ "U_CD43_MY16_Gas_Rx" SG_ 390 AccBrkPrchg_B_Rq 1;
BA_ "U_CD4_MY13_Diesel_Tx" SG_ 390 AccBrkPrchg_B_Rq 1;
BA_ "U_CD4_MY13_Gas_Tx" SG_ 390 AccBrkPrchg_B_Rq 1;
BA_ "U_CD4_MY13_Hev_Tx" SG_ 390 AccBrkPrchg_B_Rq 1;
BA_ "U_CD4_MY13_Phev_Tx" SG_ 390 AccBrkPrchg_B_Rq 1;
BA_ "U_CD42_MY14_Diesel_Tx" SG_ 390 AccBrkPrchg_B_Rq 1;
BA_ "U_CD42_MY14_Gas_Tx" SG_ 390 AccBrkPrchg_B_Rq 1;
BA_ "U_P552_MY15_Gas_Tx" SG_ 390 AccBrkPrchg_B_Rq 1;
BA_ "U_S550_MY15_Gas_Tx" SG_ 390 AccBrkPrchg_B_Rq 1;
BA_ "U_C489_MY14_Gas_Tx" SG_ 390 AccBrkPrchg_B_Rq 1;
BA_ "U_U502_MY15_Gas_Tx" SG_ 390 AccBrkPrchg_B_Rq 1;
BA_ "U_UP375_MY15_Gas_Tx" SG_ 390 AccBrkPrchg_B_Rq 1;
BA_ "U_UP375_MY15_Diesel_Tx" SG_ 390 AccBrkPrchg_B_Rq 1;
BA_ "U_CD43_MY16_Gas_Tx" SG_ 390 AccBrkPrchg_B_Rq 1;
BA_ "GenSigTimeoutTime_ABS_ESC" SG_ 390 AccBrkPrchg_B_Rq 1000;
BA_ "U_CD4_MY13_Diesel_Rx" SG_ 390 AccBrkDecel_B_Rq 1;
BA_ "U_CD4_MY13_Gas_Rx" SG_ 390 AccBrkDecel_B_Rq 1;
BA_ "U_CD4_MY13_Hev_Rx" SG_ 390 AccBrkDecel_B_Rq 1;
BA_ "U_CD4_MY13_Phev_Rx" SG_ 390 AccBrkDecel_B_Rq 1;
BA_ "U_CD42_MY14_Diesel_Rx" SG_ 390 AccBrkDecel_B_Rq 1;
BA_ "U_CD42_MY14_Gas_Rx" SG_ 390 AccBrkDecel_B_Rq 1;
BA_ "U_P552_MY15_Gas_Rx" SG_ 390 AccBrkDecel_B_Rq 1;
BA_ "U_S550_MY15_Gas_Rx" SG_ 390 AccBrkDecel_B_Rq 1;
BA_ "U_C489_MY14_Gas_Rx" SG_ 390 AccBrkDecel_B_Rq 1;
BA_ "U_U502_MY15_Gas_Rx" SG_ 390 AccBrkDecel_B_Rq 1;
BA_ "U_UP375_MY15_Gas_Rx" SG_ 390 AccBrkDecel_B_Rq 1;
BA_ "U_UP375_MY15_Diesel_Rx" SG_ 390 AccBrkDecel_B_Rq 1;
BA_ "U_CD43_MY16_Gas_Rx" SG_ 390 AccBrkDecel_B_Rq 1;
BA_ "U_CD4_MY13_Diesel_Tx" SG_ 390 AccBrkDecel_B_Rq 1;
BA_ "U_CD4_MY13_Gas_Tx" SG_ 390 AccBrkDecel_B_Rq 1;
BA_ "U_CD4_MY13_Hev_Tx" SG_ 390 AccBrkDecel_B_Rq 1;
BA_ "U_CD4_MY13_Phev_Tx" SG_ 390 AccBrkDecel_B_Rq 1;
BA_ "U_CD42_MY14_Diesel_Tx" SG_ 390 AccBrkDecel_B_Rq 1;
BA_ "U_CD42_MY14_Gas_Tx" SG_ 390 AccBrkDecel_B_Rq 1;
BA_ "U_P552_MY15_Gas_Tx" SG_ 390 AccBrkDecel_B_Rq 1;
BA_ "U_S550_MY15_Gas_Tx" SG_ 390 AccBrkDecel_B_Rq 1;
BA_ "U_C489_MY14_Gas_Tx" SG_ 390 AccBrkDecel_B_Rq 1;
BA_ "U_U502_MY15_Gas_Tx" SG_ 390 AccBrkDecel_B_Rq 1;
BA_ "U_UP375_MY15_Gas_Tx" SG_ 390 AccBrkDecel_B_Rq 1;
BA_ "U_UP375_MY15_Diesel_Tx" SG_ 390 AccBrkDecel_B_Rq 1;
BA_ "U_CD43_MY16_Gas_Tx" SG_ 390 AccBrkDecel_B_Rq 1;
BA_ "GenSigTimeoutTime_ABS_ESC" SG_ 390 AccBrkDecel_B_Rq 1000;
BA_ "U_P552_MY15_Gas_Rx" SG_ 1072 TrlrAidCancl_B_Rq_UB 1;
BA_ "GenSigSendType" SG_ 1072 TrlrAidCancl_B_Rq 3;
BA_ "U_P552_MY15_Gas_Rx" SG_ 1072 TrlrAidCancl_B_Rq 1;
BA_ "CrossOver_InfoCAN" SG_ 1072 HsaMde_D_Rq 1;
BA_ "GenSigStartValue" SG_ 1072 HsaMde_D_Rq 1;
BA_ "GenSigSendType" SG_ 1072 HsaMde_D_Rq 3;
BA_ "U_CD4_MY13_Diesel_Rx" SG_ 1072 Multimedia_System_UB 1;
BA_ "U_CD4_MY13_Gas_Rx" SG_ 1072 Multimedia_System_UB 1;
BA_ "U_CD4_MY13_Hev_Rx" SG_ 1072 Multimedia_System_UB 1;
BA_ "U_CD4_MY13_Phev_Rx" SG_ 1072 Multimedia_System_UB 1;
BA_ "U_CD42_MY14_Diesel_Rx" SG_ 1072 Multimedia_System_UB 1;
BA_ "U_CD42_MY14_Gas_Rx" SG_ 1072 Multimedia_System_UB 1;
BA_ "U_P552_MY15_Gas_Rx" SG_ 1072 Multimedia_System_UB 1;
BA_ "U_S550_MY15_Gas_Rx" SG_ 1072 Multimedia_System_UB 1;
BA_ "U_C489_MY14_Gas_Rx" SG_ 1072 Multimedia_System_UB 1;
BA_ "U_U502_MY15_Gas_Rx" SG_ 1072 Multimedia_System_UB 1;
BA_ "U_UP375_MY15_Gas_Rx" SG_ 1072 Multimedia_System_UB 1;
BA_ "U_UP375_MY15_Diesel_Rx" SG_ 1072 Multimedia_System_UB 1;
BA_ "U_CD43_MY16_Gas_Rx" SG_ 1072 Multimedia_System_UB 1;
BA_ "WakeupSignal" SG_ 1072 Multimedia_System 1;
BA_ "CrossOver_InfoCAN" SG_ 1072 Multimedia_System 1;
BA_ "GenSigSendType" SG_ 1072 Multimedia_System 3;
BA_ "U_CD4_MY13_Diesel_Rx" SG_ 1072 Multimedia_System 1;
BA_ "U_CD4_MY13_Gas_Rx" SG_ 1072 Multimedia_System 1;
BA_ "U_CD4_MY13_Hev_Rx" SG_ 1072 Multimedia_System 1;
BA_ "U_CD4_MY13_Phev_Rx" SG_ 1072 Multimedia_System 1;
BA_ "U_CD42_MY14_Diesel_Rx" SG_ 1072 Multimedia_System 1;
BA_ "U_CD42_MY14_Gas_Rx" SG_ 1072 Multimedia_System 1;
BA_ "U_P552_MY15_Gas_Rx" SG_ 1072 Multimedia_System 1;
BA_ "U_S550_MY15_Gas_Rx" SG_ 1072 Multimedia_System 1;
BA_ "U_C489_MY14_Gas_Rx" SG_ 1072 Multimedia_System 1;
BA_ "U_U502_MY15_Gas_Rx" SG_ 1072 Multimedia_System 1;
BA_ "U_UP375_MY15_Gas_Rx" SG_ 1072 Multimedia_System 1;
BA_ "U_UP375_MY15_Diesel_Rx" SG_ 1072 Multimedia_System 1;
BA_ "U_CD43_MY16_Gas_Rx" SG_ 1072 Multimedia_System 1;
BA_ "CrossOver_InfoCAN" SG_ 1072 LscmbbStat_B_Actl 1;
BA_ "GenSigSendType" SG_ 1072 LscmbbStat_B_Actl 3;
BA_ "CrossOver_InfoCAN" SG_ 1072 Outside_Air_Temp_Stat_UB 1;
BA_ "U_CD4_MY13_Diesel_Rx" SG_ 1072 Outside_Air_Temp_Stat_UB 1;
BA_ "U_CD4_MY13_Gas_Rx" SG_ 1072 Outside_Air_Temp_Stat_UB 1;
BA_ "U_CD4_MY13_Hev_Rx" SG_ 1072 Outside_Air_Temp_Stat_UB 1;
BA_ "U_CD4_MY13_Phev_Rx" SG_ 1072 Outside_Air_Temp_Stat_UB 1;
BA_ "U_CD42_MY14_Diesel_Rx" SG_ 1072 Outside_Air_Temp_Stat_UB 1;
BA_ "U_CD42_MY14_Gas_Rx" SG_ 1072 Outside_Air_Temp_Stat_UB 1;
BA_ "U_P552_MY15_Gas_Rx" SG_ 1072 Outside_Air_Temp_Stat_UB 1;
BA_ "U_S550_MY15_Gas_Rx" SG_ 1072 Outside_Air_Temp_Stat_UB 1;
BA_ "U_C489_MY14_Gas_Rx" SG_ 1072 Outside_Air_Temp_Stat_UB 1;
BA_ "U_U502_MY15_Gas_Rx" SG_ 1072 Outside_Air_Temp_Stat_UB 1;
BA_ "U_UP375_MY15_Gas_Rx" SG_ 1072 Outside_Air_Temp_Stat_UB 1;
BA_ "U_UP375_MY15_Diesel_Rx" SG_ 1072 Outside_Air_Temp_Stat_UB 1;
BA_ "U_CD43_MY16_Gas_Rx" SG_ 1072 Outside_Air_Temp_Stat_UB 1;
BA_ "CrossOver_InfoCAN" SG_ 1072 Outside_Air_Temp_Stat 1;
BA_ "GenSigStartValue" SG_ 1072 Outside_Air_Temp_Stat 255;
BA_ "GenSigSendType" SG_ 1072 Outside_Air_Temp_Stat 3;
BA_ "U_CD4_MY13_Diesel_Rx" SG_ 1072 Outside_Air_Temp_Stat 1;
BA_ "U_CD4_MY13_Gas_Rx" SG_ 1072 Outside_Air_Temp_Stat 1;
BA_ "U_CD4_MY13_Hev_Rx" SG_ 1072 Outside_Air_Temp_Stat 1;
BA_ "U_CD4_MY13_Phev_Rx" SG_ 1072 Outside_Air_Temp_Stat 1;
BA_ "U_CD42_MY14_Diesel_Rx" SG_ 1072 Outside_Air_Temp_Stat 1;
BA_ "U_CD42_MY14_Gas_Rx" SG_ 1072 Outside_Air_Temp_Stat 1;
BA_ "U_P552_MY15_Gas_Rx" SG_ 1072 Outside_Air_Temp_Stat 1;
BA_ "U_S550_MY15_Gas_Rx" SG_ 1072 Outside_Air_Temp_Stat 1;
BA_ "U_C489_MY14_Gas_Rx" SG_ 1072 Outside_Air_Temp_Stat 1;
BA_ "U_U502_MY15_Gas_Rx" SG_ 1072 Outside_Air_Temp_Stat 1;
BA_ "U_UP375_MY15_Gas_Rx" SG_ 1072 Outside_Air_Temp_Stat 1;
BA_ "U_UP375_MY15_Diesel_Rx" SG_ 1072 Outside_Air_Temp_Stat 1;
BA_ "U_CD43_MY16_Gas_Rx" SG_ 1072 Outside_Air_Temp_Stat 1;
BA_ "U_CD4_MY13_Diesel_Rx" SG_ 1072 BulbChkActv_B_Stat_UB 1;
BA_ "U_CD4_MY13_Gas_Rx" SG_ 1072 BulbChkActv_B_Stat_UB 1;
BA_ "U_CD4_MY13_Hev_Rx" SG_ 1072 BulbChkActv_B_Stat_UB 1;
BA_ "U_CD4_MY13_Phev_Rx" SG_ 1072 BulbChkActv_B_Stat_UB 1;
BA_ "U_CD42_MY14_Diesel_Rx" SG_ 1072 BulbChkActv_B_Stat_UB 1;
BA_ "U_CD42_MY14_Gas_Rx" SG_ 1072 BulbChkActv_B_Stat_UB 1;
BA_ "U_P552_MY15_Gas_Rx" SG_ 1072 BulbChkActv_B_Stat_UB 1;
BA_ "U_S550_MY15_Gas_Rx" SG_ 1072 BulbChkActv_B_Stat_UB 1;
BA_ "U_C489_MY14_Gas_Rx" SG_ 1072 BulbChkActv_B_Stat_UB 1;
BA_ "U_U502_MY15_Gas_Rx" SG_ 1072 BulbChkActv_B_Stat_UB 1;
BA_ "U_UP375_MY15_Gas_Rx" SG_ 1072 BulbChkActv_B_Stat_UB 1;
BA_ "U_UP375_MY15_Diesel_Rx" SG_ 1072 BulbChkActv_B_Stat_UB 1;
BA_ "U_CD43_MY16_Gas_Rx" SG_ 1072 BulbChkActv_B_Stat_UB 1;
BA_ "CrossOver_InfoCAN" SG_ 1072 BulbChkActv_B_Stat 1;
BA_ "GenSigSendType" SG_ 1072 BulbChkActv_B_Stat 3;
BA_ "U_CD4_MY13_Diesel_Rx" SG_ 1072 BulbChkActv_B_Stat 1;
BA_ "U_CD4_MY13_Gas_Rx" SG_ 1072 BulbChkActv_B_Stat 1;
BA_ "U_CD4_MY13_Hev_Rx" SG_ 1072 BulbChkActv_B_Stat 1;
BA_ "U_CD4_MY13_Phev_Rx" SG_ 1072 BulbChkActv_B_Stat 1;
BA_ "U_CD42_MY14_Diesel_Rx" SG_ 1072 BulbChkActv_B_Stat 1;
BA_ "U_CD42_MY14_Gas_Rx" SG_ 1072 BulbChkActv_B_Stat 1;
BA_ "U_P552_MY15_Gas_Rx" SG_ 1072 BulbChkActv_B_Stat 1;
BA_ "U_S550_MY15_Gas_Rx" SG_ 1072 BulbChkActv_B_Stat 1;
BA_ "U_C489_MY14_Gas_Rx" SG_ 1072 BulbChkActv_B_Stat 1;
BA_ "U_U502_MY15_Gas_Rx" SG_ 1072 BulbChkActv_B_Stat 1;
BA_ "U_UP375_MY15_Gas_Rx" SG_ 1072 BulbChkActv_B_Stat 1;
BA_ "U_UP375_MY15_Diesel_Rx" SG_ 1072 BulbChkActv_B_Stat 1;
BA_ "U_CD43_MY16_Gas_Rx" SG_ 1072 BulbChkActv_B_Stat 1;
BA_ "U_CD4_MY13_Diesel_Rx" SG_ 1072 Fda_B_Stat_UB 1;
BA_ "U_CD4_MY13_Gas_Rx" SG_ 1072 Fda_B_Stat_UB 1;
BA_ "U_CD4_MY13_Hev_Rx" SG_ 1072 Fda_B_Stat_UB 1;
BA_ "U_CD4_MY13_Phev_Rx" SG_ 1072 Fda_B_Stat_UB 1;
BA_ "U_CD42_MY14_Diesel_Rx" SG_ 1072 Fda_B_Stat_UB 1;
BA_ "U_CD42_MY14_Gas_Rx" SG_ 1072 Fda_B_Stat_UB 1;
BA_ "U_P552_MY15_Gas_Rx" SG_ 1072 Fda_B_Stat_UB 1;
BA_ "U_S550_MY15_Gas_Rx" SG_ 1072 Fda_B_Stat_UB 1;
BA_ "U_C489_MY14_Gas_Rx" SG_ 1072 Fda_B_Stat_UB 1;
BA_ "U_U502_MY15_Gas_Rx" SG_ 1072 Fda_B_Stat_UB 1;
BA_ "U_UP375_MY15_Gas_Rx" SG_ 1072 Fda_B_Stat_UB 1;
BA_ "U_UP375_MY15_Diesel_Rx" SG_ 1072 Fda_B_Stat_UB 1;
BA_ "U_CD43_MY16_Gas_Rx" SG_ 1072 Fda_B_Stat_UB 1;
BA_ "U_CD4_MY13_Diesel_Rx" SG_ 1072 AccEnbl_B_RqDrv_UB 1;
BA_ "U_CD4_MY13_Gas_Rx" SG_ 1072 AccEnbl_B_RqDrv_UB 1;
BA_ "U_CD4_MY13_Hev_Rx" SG_ 1072 AccEnbl_B_RqDrv_UB 1;
BA_ "U_CD4_MY13_Phev_Rx" SG_ 1072 AccEnbl_B_RqDrv_UB 1;
BA_ "U_CD42_MY14_Diesel_Rx" SG_ 1072 AccEnbl_B_RqDrv_UB 1;
BA_ "U_CD42_MY14_Gas_Rx" SG_ 1072 AccEnbl_B_RqDrv_UB 1;
BA_ "U_P552_MY15_Gas_Rx" SG_ 1072 AccEnbl_B_RqDrv_UB 1;
BA_ "U_S550_MY15_Gas_Rx" SG_ 1072 AccEnbl_B_RqDrv_UB 1;
BA_ "U_C489_MY14_Gas_Rx" SG_ 1072 AccEnbl_B_RqDrv_UB 1;
BA_ "U_U502_MY15_Gas_Rx" SG_ 1072 AccEnbl_B_RqDrv_UB 1;
BA_ "U_UP375_MY15_Gas_Rx" SG_ 1072 AccEnbl_B_RqDrv_UB 1;
BA_ "U_UP375_MY15_Diesel_Rx" SG_ 1072 AccEnbl_B_RqDrv_UB 1;
BA_ "U_CD43_MY16_Gas_Rx" SG_ 1072 AccEnbl_B_RqDrv_UB 1;
BA_ "U_CD4_MY13_Diesel_Rx" SG_ 1072 AccDeny_B_RqIpc_UB 1;
BA_ "U_CD4_MY13_Gas_Rx" SG_ 1072 AccDeny_B_RqIpc_UB 1;
BA_ "U_CD4_MY13_Hev_Rx" SG_ 1072 AccDeny_B_RqIpc_UB 1;
BA_ "U_CD4_MY13_Phev_Rx" SG_ 1072 AccDeny_B_RqIpc_UB 1;
BA_ "U_CD42_MY14_Diesel_Rx" SG_ 1072 AccDeny_B_RqIpc_UB 1;
BA_ "U_CD42_MY14_Gas_Rx" SG_ 1072 AccDeny_B_RqIpc_UB 1;
BA_ "U_P552_MY15_Gas_Rx" SG_ 1072 AccDeny_B_RqIpc_UB 1;
BA_ "U_S550_MY15_Gas_Rx" SG_ 1072 AccDeny_B_RqIpc_UB 1;
BA_ "U_C489_MY14_Gas_Rx" SG_ 1072 AccDeny_B_RqIpc_UB 1;
BA_ "U_U502_MY15_Gas_Rx" SG_ 1072 AccDeny_B_RqIpc_UB 1;
BA_ "U_UP375_MY15_Gas_Rx" SG_ 1072 AccDeny_B_RqIpc_UB 1;
BA_ "U_UP375_MY15_Diesel_Rx" SG_ 1072 AccDeny_B_RqIpc_UB 1;
BA_ "U_CD43_MY16_Gas_Rx" SG_ 1072 AccDeny_B_RqIpc_UB 1;
BA_ "U_CD4_MY13_Diesel_Rx" SG_ 1072 OdometerMasterValue_UB 1;
BA_ "U_CD4_MY13_Gas_Rx" SG_ 1072 OdometerMasterValue_UB 1;
BA_ "U_CD4_MY13_Hev_Rx" SG_ 1072 OdometerMasterValue_UB 1;
BA_ "U_CD4_MY13_Phev_Rx" SG_ 1072 OdometerMasterValue_UB 1;
BA_ "U_CD42_MY14_Diesel_Rx" SG_ 1072 OdometerMasterValue_UB 1;
BA_ "U_CD42_MY14_Gas_Rx" SG_ 1072 OdometerMasterValue_UB 1;
BA_ "U_P552_MY15_Gas_Rx" SG_ 1072 OdometerMasterValue_UB 1;
BA_ "U_S550_MY15_Gas_Rx" SG_ 1072 OdometerMasterValue_UB 1;
BA_ "U_U502_MY15_Gas_Rx" SG_ 1072 OdometerMasterValue_UB 1;
BA_ "U_UP375_MY15_Gas_Rx" SG_ 1072 OdometerMasterValue_UB 1;
BA_ "U_UP375_MY15_Diesel_Rx" SG_ 1072 OdometerMasterValue_UB 1;
BA_ "U_CD43_MY16_Gas_Rx" SG_ 1072 OdometerMasterValue_UB 1;
BA_ "CrossOver_InfoCAN" SG_ 1072 OdometerMasterValue 1;
BA_ "GenSigSendType" SG_ 1072 OdometerMasterValue 3;
BA_ "U_CD4_MY13_Diesel_Rx" SG_ 1072 OdometerMasterValue 1;
BA_ "U_CD4_MY13_Gas_Rx" SG_ 1072 OdometerMasterValue 1;
BA_ "U_CD4_MY13_Hev_Rx" SG_ 1072 OdometerMasterValue 1;
BA_ "U_CD4_MY13_Phev_Rx" SG_ 1072 OdometerMasterValue 1;
BA_ "U_CD42_MY14_Diesel_Rx" SG_ 1072 OdometerMasterValue 1;
BA_ "U_CD42_MY14_Gas_Rx" SG_ 1072 OdometerMasterValue 1;
BA_ "U_P552_MY15_Gas_Rx" SG_ 1072 OdometerMasterValue 1;
BA_ "U_S550_MY15_Gas_Rx" SG_ 1072 OdometerMasterValue 1;
BA_ "U_U502_MY15_Gas_Rx" SG_ 1072 OdometerMasterValue 1;
BA_ "U_UP375_MY15_Gas_Rx" SG_ 1072 OdometerMasterValue 1;
BA_ "U_UP375_MY15_Diesel_Rx" SG_ 1072 OdometerMasterValue 1;
BA_ "U_CD43_MY16_Gas_Rx" SG_ 1072 OdometerMasterValue 1;
BA_ "CrossOver_InfoCAN" SG_ 1072 Fda_B_Stat 1;
BA_ "GenSigSendType" SG_ 1072 Fda_B_Stat 3;
BA_ "U_CD4_MY13_Diesel_Rx" SG_ 1072 Fda_B_Stat 1;
BA_ "U_CD4_MY13_Gas_Rx" SG_ 1072 Fda_B_Stat 1;
BA_ "U_CD4_MY13_Hev_Rx" SG_ 1072 Fda_B_Stat 1;
BA_ "U_CD4_MY13_Phev_Rx" SG_ 1072 Fda_B_Stat 1;
BA_ "U_CD42_MY14_Diesel_Rx" SG_ 1072 Fda_B_Stat 1;
BA_ "U_CD42_MY14_Gas_Rx" SG_ 1072 Fda_B_Stat 1;
BA_ "U_P552_MY15_Gas_Rx" SG_ 1072 Fda_B_Stat 1;
BA_ "U_S550_MY15_Gas_Rx" SG_ 1072 Fda_B_Stat 1;
BA_ "U_C489_MY14_Gas_Rx" SG_ 1072 Fda_B_Stat 1;
BA_ "U_U502_MY15_Gas_Rx" SG_ 1072 Fda_B_Stat 1;
BA_ "U_UP375_MY15_Gas_Rx" SG_ 1072 Fda_B_Stat 1;
BA_ "U_UP375_MY15_Diesel_Rx" SG_ 1072 Fda_B_Stat 1;
BA_ "U_CD43_MY16_Gas_Rx" SG_ 1072 Fda_B_Stat 1;
BA_ "CrossOver_InfoCAN" SG_ 1072 AccDeny_B_RqIpc 1;
BA_ "GenSigSendType" SG_ 1072 AccDeny_B_RqIpc 3;
BA_ "U_CD4_MY13_Diesel_Rx" SG_ 1072 AccDeny_B_RqIpc 1;
BA_ "U_CD4_MY13_Gas_Rx" SG_ 1072 AccDeny_B_RqIpc 1;
BA_ "U_CD4_MY13_Hev_Rx" SG_ 1072 AccDeny_B_RqIpc 1;
BA_ "U_CD4_MY13_Phev_Rx" SG_ 1072 AccDeny_B_RqIpc 1;
BA_ "U_CD42_MY14_Diesel_Rx" SG_ 1072 AccDeny_B_RqIpc 1;
BA_ "U_CD42_MY14_Gas_Rx" SG_ 1072 AccDeny_B_RqIpc 1;
BA_ "U_P552_MY15_Gas_Rx" SG_ 1072 AccDeny_B_RqIpc 1;
BA_ "U_S550_MY15_Gas_Rx" SG_ 1072 AccDeny_B_RqIpc 1;
BA_ "U_C489_MY14_Gas_Rx" SG_ 1072 AccDeny_B_RqIpc 1;
BA_ "U_U502_MY15_Gas_Rx" SG_ 1072 AccDeny_B_RqIpc 1;
BA_ "U_UP375_MY15_Gas_Rx" SG_ 1072 AccDeny_B_RqIpc 1;
BA_ "U_UP375_MY15_Diesel_Rx" SG_ 1072 AccDeny_B_RqIpc 1;
BA_ "U_CD43_MY16_Gas_Rx" SG_ 1072 AccDeny_B_RqIpc 1;
BA_ "CrossOver_InfoCAN" SG_ 1072 AccEnbl_B_RqDrv 1;
BA_ "GenSigStartValue" SG_ 1072 AccEnbl_B_RqDrv 1;
BA_ "GenSigSendType" SG_ 1072 AccEnbl_B_RqDrv 3;
BA_ "U_CD4_MY13_Diesel_Rx" SG_ 1072 AccEnbl_B_RqDrv 1;
BA_ "U_CD4_MY13_Gas_Rx" SG_ 1072 AccEnbl_B_RqDrv 1;
BA_ "U_CD4_MY13_Hev_Rx" SG_ 1072 AccEnbl_B_RqDrv 1;
BA_ "U_CD4_MY13_Phev_Rx" SG_ 1072 AccEnbl_B_RqDrv 1;
BA_ "U_CD42_MY14_Diesel_Rx" SG_ 1072 AccEnbl_B_RqDrv 1;
BA_ "U_CD42_MY14_Gas_Rx" SG_ 1072 AccEnbl_B_RqDrv 1;
BA_ "U_P552_MY15_Gas_Rx" SG_ 1072 AccEnbl_B_RqDrv 1;
BA_ "U_S550_MY15_Gas_Rx" SG_ 1072 AccEnbl_B_RqDrv 1;
BA_ "U_C489_MY14_Gas_Rx" SG_ 1072 AccEnbl_B_RqDrv 1;
BA_ "U_U502_MY15_Gas_Rx" SG_ 1072 AccEnbl_B_RqDrv 1;
BA_ "U_UP375_MY15_Gas_Rx" SG_ 1072 AccEnbl_B_RqDrv 1;
BA_ "U_UP375_MY15_Diesel_Rx" SG_ 1072 AccEnbl_B_RqDrv 1;
BA_ "U_CD43_MY16_Gas_Rx" SG_ 1072 AccEnbl_B_RqDrv 1;
BA_ "CrossOver_InfoCAN" SG_ 1072 DrvSlipCtlMde_D_Rq 1;
BA_ "GenSigSendType" SG_ 1072 DrvSlipCtlMde_D_Rq 3;
BA_ "U_P552_MY15_Gas_Rx" SG_ 1072 DrvSlipCtlMde_B_Rq_UB 1;
BA_ "U_S550_MY15_Gas_Rx" SG_ 1072 DrvSlipCtlMde_B_Rq_UB 1;
BA_ "U_UP375_MY15_Gas_Rx" SG_ 1072 DrvSlipCtlMde_B_Rq_UB 1;
BA_ "U_UP375_MY15_Diesel_Rx" SG_ 1072 DrvSlipCtlMde_B_Rq_UB 1;
BA_ "CrossOver_InfoCAN" SG_ 1072 DrvSlipCtlMde_B_Rq 1;
BA_ "GenSigSendType" SG_ 1072 DrvSlipCtlMde_B_Rq 3;
BA_ "U_P552_MY15_Gas_Rx" SG_ 1072 DrvSlipCtlMde_B_Rq 1;
BA_ "U_S550_MY15_Gas_Rx" SG_ 1072 DrvSlipCtlMde_B_Rq 1;
BA_ "U_UP375_MY15_Gas_Rx" SG_ 1072 DrvSlipCtlMde_B_Rq 1;
BA_ "U_UP375_MY15_Diesel_Rx" SG_ 1072 DrvSlipCtlMde_B_Rq 1;
BA_ "WakeupSignal" SG_ 1072 ePRNDL_MODE 1;
BA_ "CrossOver_InfoCAN" SG_ 1072 ePRNDL_MODE 1;
BA_ "GenSigSendType" SG_ 1072 ePRNDL_MODE 3;
BA_ "GenSigSendType" SG_ 1072 TrlrBrkMde_D_Rq 3;
BA_ "U_P552_MY15_Gas_Rx" SG_ 1072 TrlrBrkMde_D_Rq 1;
BA_ "GenSigSendType" SG_ 1072 TRLR_SWAY_CONFIG_CMD 3;
BA_ "U_CD42_MY14_Diesel_Rx" SG_ 1072 TRLR_SWAY_CONFIG_CMD 1;
BA_ "U_CD42_MY14_Gas_Rx" SG_ 1072 TRLR_SWAY_CONFIG_CMD 1;
BA_ "U_P552_MY15_Gas_Rx" SG_ 1072 TRLR_SWAY_CONFIG_CMD 1;
BA_ "U_U502_MY15_Gas_Rx" SG_ 1072 TRLR_SWAY_CONFIG_CMD 1;
BA_ "U_UP375_MY15_Gas_Rx" SG_ 1072 TRLR_SWAY_CONFIG_CMD 1;
BA_ "U_UP375_MY15_Diesel_Rx" SG_ 1072 TRLR_SWAY_CONFIG_CMD 1;
BA_ "GenSigSendType" SG_ 1072 TRAILER_BRAKE_CONFIG 3;
BA_ "U_P552_MY15_Gas_Rx" SG_ 1072 TRAILER_BRAKE_CONFIG 1;
BA_ "U_P552_MY15_Gas_Rx" SG_ 1072 TrlrBrkMde_D_Rq_UB 1;
BA_ "U_P552_MY15_Gas_Rx" SG_ 1072 TRLR_SWAY_CONFIG_CMD_UB 1;
BA_ "U_UP375_MY15_Gas_Rx" SG_ 1072 TRLR_SWAY_CONFIG_CMD_UB 1;
BA_ "U_UP375_MY15_Diesel_Rx" SG_ 1072 TRLR_SWAY_CONFIG_CMD_UB 1;
BA_ "U_P552_MY15_Gas_Rx" SG_ 1072 TRAILER_BRAKE_CONFIG_UB 1;
BA_ "CrossOver_InfoCAN" SG_ 1058 DrvSlipCtlMde_B_Rq2 1;
BA_ "Gateway_ID" SG_ 1058 DrvSlipCtlMde_B_Rq2 27661;
BA_ "CrossOver_InfoCAN" SG_ 1058 BattTracWarnLamp_B_Rq_UB 1;
BA_ "CrossOver_InfoCAN" SG_ 1058 BattTracWarnLamp_B_Rq 1;
BA_ "CrossOver_InfoCAN" SG_ 1058 BattTracSrvcRqd_B_Rq_UB 1;
BA_ "CrossOver_InfoCAN" SG_ 1058 BattTracSrvcRqd_B_Rq 1;
BA_ "U_CD4_MY13_Diesel_Rx" SG_ 1058 SeatBlLoPsgr_Pc_Actl_UB 1;
BA_ "U_CD4_MY13_Gas_Rx" SG_ 1058 SeatBlLoPsgr_Pc_Actl_UB 1;
BA_ "U_CD4_MY13_Hev_Rx" SG_ 1058 SeatBlLoPsgr_Pc_Actl_UB 1;
BA_ "U_CD4_MY13_Phev_Rx" SG_ 1058 SeatBlLoPsgr_Pc_Actl_UB 1;
BA_ "U_CD42_MY14_Diesel_Rx" SG_ 1058 SeatBlLoPsgr_Pc_Actl_UB 1;
BA_ "U_CD42_MY14_Gas_Rx" SG_ 1058 SeatBlLoPsgr_Pc_Actl_UB 1;
BA_ "U_P552_MY15_Gas_Rx" SG_ 1058 SeatBlLoPsgr_Pc_Actl_UB 1;
BA_ "U_U502_MY15_Gas_Rx" SG_ 1058 SeatBlLoPsgr_Pc_Actl_UB 1;
BA_ "U_CD43_MY16_Gas_Rx" SG_ 1058 SeatBlLoPsgr_Pc_Actl_UB 1;
BA_ "U_CD4_MY14_Diesel_Rx" SG_ 1058 SeatBlLoPsgr_Pc_Actl_UB 1;
BA_ "U_CD4_MY14_Gas_Rx" SG_ 1058 SeatBlLoPsgr_Pc_Actl_UB 1;
BA_ "U_CD4_MY14_Hev_Rx" SG_ 1058 SeatBlLoPsgr_Pc_Actl_UB 1;
BA_ "U_CD4_MY14_Phev_Rx" SG_ 1058 SeatBlLoPsgr_Pc_Actl_UB 1;
BA_ "GenSigTimeoutTime_OCS" SG_ 1058 SeatBlLoPsgr_Pc_Actl_UB 6000;
BA_ "CrossOver_InfoCAN" SG_ 1058 SeatBlLoPsgr_Pc_Actl 1;
BA_ "GenSigStartValue" SG_ 1058 SeatBlLoPsgr_Pc_Actl 127;
BA_ "U_CD4_MY13_Diesel_Rx" SG_ 1058 SeatBlLoPsgr_Pc_Actl 1;
BA_ "U_CD4_MY13_Gas_Rx" SG_ 1058 SeatBlLoPsgr_Pc_Actl 1;
BA_ "U_CD4_MY13_Hev_Rx" SG_ 1058 SeatBlLoPsgr_Pc_Actl 1;
BA_ "U_CD4_MY13_Phev_Rx" SG_ 1058 SeatBlLoPsgr_Pc_Actl 1;
BA_ "U_CD42_MY14_Diesel_Rx" SG_ 1058 SeatBlLoPsgr_Pc_Actl 1;
BA_ "U_CD42_MY14_Gas_Rx" SG_ 1058 SeatBlLoPsgr_Pc_Actl 1;
BA_ "U_P552_MY15_Gas_Rx" SG_ 1058 SeatBlLoPsgr_Pc_Actl 1;
BA_ "U_U502_MY15_Gas_Rx" SG_ 1058 SeatBlLoPsgr_Pc_Actl 1;
BA_ "U_CD43_MY16_Gas_Rx" SG_ 1058 SeatBlLoPsgr_Pc_Actl 1;
BA_ "U_CD4_MY14_Diesel_Rx" SG_ 1058 SeatBlLoPsgr_Pc_Actl 1;
BA_ "U_CD4_MY14_Gas_Rx" SG_ 1058 SeatBlLoPsgr_Pc_Actl 1;
BA_ "U_CD4_MY14_Hev_Rx" SG_ 1058 SeatBlLoPsgr_Pc_Actl 1;
BA_ "U_CD4_MY14_Phev_Rx" SG_ 1058 SeatBlLoPsgr_Pc_Actl 1;
BA_ "GenSigTimeoutTime_OCS" SG_ 1058 SeatBlLoPsgr_Pc_Actl 6000;
BA_ "U_P552_MY15_Gas_Rx" SG_ 1058 HILL_DESC_SW_UB 1;
BA_ "U_UP375_MY15_Gas_Rx" SG_ 1058 HILL_DESC_SW_UB 1;
BA_ "U_UP375_MY15_Diesel_Rx" SG_ 1058 HILL_DESC_SW_UB 1;
BA_ "CrossOver_InfoCAN" SG_ 1058 HILL_DESC_SW 1;
BA_ "U_P552_MY15_Gas_Rx" SG_ 1058 HILL_DESC_SW 1;
BA_ "U_UP375_MY15_Gas_Rx" SG_ 1058 HILL_DESC_SW 1;
BA_ "U_UP375_MY15_Diesel_Rx" SG_ 1058 HILL_DESC_SW 1;
BA_ "CrossOver_InfoCAN" SG_ 1058 EngClntTe_D_Qf 1;
BA_ "CrossOver_InfoCAN" SG_ 1058 EngClnt_Te_Actl 1;
BA_ "GenSigSendType" SG_ 1430 ABS_AutoSar_Network_Mgmt 3;
BA_ "U_CD4_MY13_Diesel_Rx" SG_ 1430 ABS_AutoSar_Network_Mgmt 1;
BA_ "U_CD4_MY13_Gas_Rx" SG_ 1430 ABS_AutoSar_Network_Mgmt 1;
BA_ "U_CD4_MY13_Hev_Rx" SG_ 1430 ABS_AutoSar_Network_Mgmt 1;
BA_ "U_CD4_MY13_Phev_Rx" SG_ 1430 ABS_AutoSar_Network_Mgmt 1;
BA_ "U_CD42_MY14_Diesel_Rx" SG_ 1430 ABS_AutoSar_Network_Mgmt 1;
BA_ "U_CD42_MY14_Gas_Rx" SG_ 1430 ABS_AutoSar_Network_Mgmt 1;
BA_ "U_P552_MY15_Gas_Rx" SG_ 1430 ABS_AutoSar_Network_Mgmt 1;
BA_ "U_S550_MY15_Gas_Rx" SG_ 1430 ABS_AutoSar_Network_Mgmt 1;
BA_ "U_C489_MY14_Gas_Rx" SG_ 1430 ABS_AutoSar_Network_Mgmt 1;
BA_ "U_U502_MY15_Gas_Rx" SG_ 1430 ABS_AutoSar_Network_Mgmt 1;
BA_ "U_UP375_MY15_Gas_Rx" SG_ 1430 ABS_AutoSar_Network_Mgmt 1;
BA_ "U_UP375_MY15_Diesel_Rx" SG_ 1430 ABS_AutoSar_Network_Mgmt 1;
BA_ "U_CD43_MY16_Gas_Rx" SG_ 1430 ABS_AutoSar_Network_Mgmt 1;
BA_ "U_CD4_MY13_Diesel_Tx" SG_ 1430 ABS_AutoSar_Network_Mgmt 1;
BA_ "U_CD4_MY13_Gas_Tx" SG_ 1430 ABS_AutoSar_Network_Mgmt 1;
BA_ "U_CD4_MY13_Hev_Tx" SG_ 1430 ABS_AutoSar_Network_Mgmt 1;
BA_ "U_CD4_MY13_Phev_Tx" SG_ 1430 ABS_AutoSar_Network_Mgmt 1;
BA_ "U_CD42_MY14_Diesel_Tx" SG_ 1430 ABS_AutoSar_Network_Mgmt 1;
BA_ "U_CD42_MY14_Gas_Tx" SG_ 1430 ABS_AutoSar_Network_Mgmt 1;
BA_ "U_P552_MY15_Gas_Tx" SG_ 1430 ABS_AutoSar_Network_Mgmt 1;
BA_ "U_S550_MY15_Gas_Tx" SG_ 1430 ABS_AutoSar_Network_Mgmt 1;
BA_ "U_C489_MY14_Gas_Tx" SG_ 1430 ABS_AutoSar_Network_Mgmt 1;
BA_ "U_B562LC_MY14_Diesel_Tx" SG_ 1430 ABS_AutoSar_Network_Mgmt 1;
BA_ "U_B562LC_MY14_Gas_Tx" SG_ 1430 ABS_AutoSar_Network_Mgmt 1;
BA_ "U_U502_MY15_Gas_Tx" SG_ 1430 ABS_AutoSar_Network_Mgmt 1;
BA_ "U_UP375_MY15_Gas_Tx" SG_ 1430 ABS_AutoSar_Network_Mgmt 1;
BA_ "U_UP375_MY15_Diesel_Tx" SG_ 1430 ABS_AutoSar_Network_Mgmt 1;
BA_ "U_CD43_MY16_Gas_Tx" SG_ 1430 ABS_AutoSar_Network_Mgmt 1;
BA_ "GenSigSendType" SG_ 1889 TesterPhysicalReqTCCM 3;
BA_ "U_P552_MY15_Gas_Rx" SG_ 1889 TesterPhysicalReqTCCM 1;
BA_ "U_UP375_MY15_Gas_Rx" SG_ 1889 TesterPhysicalReqTCCM 1;
BA_ "U_UP375_MY15_Diesel_Rx" SG_ 1889 TesterPhysicalReqTCCM 1;
BA_ "GenSigSendType" SG_ 1897 TesterPhysicalResTCCM 3;
BA_ "U_P552_MY15_Gas_Tx" SG_ 1897 TesterPhysicalResTCCM 1;
BA_ "U_UP375_MY15_Gas_Tx" SG_ 1897 TesterPhysicalResTCCM 1;
BA_ "U_UP375_MY15_Diesel_Tx" SG_ 1897 TesterPhysicalResTCCM 1;
BA_ "U_P552_MY15_Gas_Rx" SG_ 512 PtDrvMde_D_Stat 1;
BA_ "U_CD4_MY13_Diesel_Rx" SG_ 512 PrplWhlTot_Tq_Rq 1;
BA_ "U_CD4_MY13_Gas_Rx" SG_ 512 PrplWhlTot_Tq_Rq 1;
BA_ "U_CD4_MY13_Hev_Rx" SG_ 512 PrplWhlTot_Tq_Rq 1;
BA_ "U_CD4_MY13_Phev_Rx" SG_ 512 PrplWhlTot_Tq_Rq 1;
BA_ "U_CD42_MY14_Diesel_Rx" SG_ 512 PrplWhlTot_Tq_Rq 1;
BA_ "U_CD42_MY14_Gas_Rx" SG_ 512 PrplWhlTot_Tq_Rq 1;
BA_ "U_P552_MY15_Gas_Rx" SG_ 512 PrplWhlTot_Tq_Rq 1;
BA_ "U_S550_MY15_Gas_Rx" SG_ 512 PrplWhlTot_Tq_Rq 1;
BA_ "U_C489_MY14_Gas_Rx" SG_ 512 PrplWhlTot_Tq_Rq 1;
BA_ "U_U502_MY15_Gas_Rx" SG_ 512 PrplWhlTot_Tq_Rq 1;
BA_ "U_UP375_MY15_Gas_Rx" SG_ 512 PrplWhlTot_Tq_Rq 1;
BA_ "U_UP375_MY15_Diesel_Rx" SG_ 512 PrplWhlTot_Tq_Rq 1;
BA_ "U_CD43_MY16_Gas_Rx" SG_ 512 PrplWhlTot_Tq_Rq 1;
BA_ "U_CD4_MY13_Diesel_Rx" SG_ 936 EPASExtAngleStatReq 1;
BA_ "U_CD4_MY13_Gas_Rx" SG_ 936 EPASExtAngleStatReq 1;
BA_ "U_CD4_MY13_Hev_Rx" SG_ 936 EPASExtAngleStatReq 1;
BA_ "U_CD4_MY13_Phev_Rx" SG_ 936 EPASExtAngleStatReq 1;
BA_ "U_CD42_MY14_Diesel_Rx" SG_ 936 EPASExtAngleStatReq 1;
BA_ "U_CD42_MY14_Gas_Rx" SG_ 936 EPASExtAngleStatReq 1;
BA_ "U_P552_MY15_Gas_Rx" SG_ 936 EPASExtAngleStatReq 1;
BA_ "U_C489_MY14_Gas_Rx" SG_ 936 EPASExtAngleStatReq 1;
BA_ "U_U502_MY15_Gas_Rx" SG_ 936 EPASExtAngleStatReq 1;
BA_ "U_UP375_MY15_Gas_Rx" SG_ 936 EPASExtAngleStatReq 1;
BA_ "U_UP375_MY15_Diesel_Rx" SG_ 936 EPASExtAngleStatReq 1;
BA_ "U_CD43_MY16_Gas_Rx" SG_ 936 EPASExtAngleStatReq 1;
BA_ "GenSigMissingSourceValue" SG_ 936 SAPPStatusCoding 6;
BA_ "CrossOver_InfoCAN" SG_ 936 SAPPStatusCoding 1;
BA_ "CrossOver_LIN" SG_ 936 SAPPStatusCoding 1;
BA_ "U_P552_MY15_Gas_Rx" SG_ 936 SAPPStatusCoding 1;
BA_ "U_CD4_MY13_Diesel_Rx" SG_ 936 ExtSteeringAngleReq2 1;
BA_ "U_CD4_MY13_Gas_Rx" SG_ 936 ExtSteeringAngleReq2 1;
BA_ "U_CD4_MY13_Hev_Rx" SG_ 936 ExtSteeringAngleReq2 1;
BA_ "U_CD4_MY13_Phev_Rx" SG_ 936 ExtSteeringAngleReq2 1;
BA_ "U_CD42_MY14_Diesel_Rx" SG_ 936 ExtSteeringAngleReq2 1;
BA_ "U_CD42_MY14_Gas_Rx" SG_ 936 ExtSteeringAngleReq2 1;
BA_ "U_P552_MY15_Gas_Rx" SG_ 936 ExtSteeringAngleReq2 1;
BA_ "U_C489_MY14_Gas_Rx" SG_ 936 ExtSteeringAngleReq2 1;
BA_ "U_U502_MY15_Gas_Rx" SG_ 936 ExtSteeringAngleReq2 1;
BA_ "U_UP375_MY15_Gas_Rx" SG_ 936 ExtSteeringAngleReq2 1;
BA_ "U_UP375_MY15_Diesel_Rx" SG_ 936 ExtSteeringAngleReq2 1;
BA_ "U_CD43_MY16_Gas_Rx" SG_ 936 ExtSteeringAngleReq2 1;
BA_ "CrossOver_InfoCAN" SG_ 76 SecondRowBucklePsngr 1;
BA_ "GenSigStartValue" SG_ 76 SecondRowBucklePsngr 3;
BA_ "GenSigSendType" SG_ 76 SecondRowBucklePsngr 3;
BA_ "U_CD4_MY13_Diesel_Tx" SG_ 76 SecondRowBucklePsngr 1;
BA_ "U_CD4_MY13_Gas_Tx" SG_ 76 SecondRowBucklePsngr 1;
BA_ "U_CD4_MY13_Hev_Tx" SG_ 76 SecondRowBucklePsngr 1;
BA_ "U_CD4_MY13_Phev_Tx" SG_ 76 SecondRowBucklePsngr 1;
BA_ "U_CD42_MY14_Diesel_Tx" SG_ 76 SecondRowBucklePsngr 1;
BA_ "U_CD42_MY14_Gas_Tx" SG_ 76 SecondRowBucklePsngr 1;
BA_ "U_P552_MY15_Gas_Tx" SG_ 76 SecondRowBucklePsngr 1;
BA_ "U_U502_MY15_Gas_Tx" SG_ 76 SecondRowBucklePsngr 1;
BA_ "U_CD43_MY16_Gas_Tx" SG_ 76 SecondRowBucklePsngr 1;
BA_ "CrossOver_InfoCAN" SG_ 76 SecondRowBuckleDriver 1;
BA_ "GenSigStartValue" SG_ 76 SecondRowBuckleDriver 3;
BA_ "GenSigSendType" SG_ 76 SecondRowBuckleDriver 3;
BA_ "U_CD4_MY13_Diesel_Tx" SG_ 76 SecondRowBuckleDriver 1;
BA_ "U_CD4_MY13_Gas_Tx" SG_ 76 SecondRowBuckleDriver 1;
BA_ "U_CD4_MY13_Hev_Tx" SG_ 76 SecondRowBuckleDriver 1;
BA_ "U_CD4_MY13_Phev_Tx" SG_ 76 SecondRowBuckleDriver 1;
BA_ "U_CD42_MY14_Diesel_Tx" SG_ 76 SecondRowBuckleDriver 1;
BA_ "U_CD42_MY14_Gas_Tx" SG_ 76 SecondRowBuckleDriver 1;
BA_ "U_P552_MY15_Gas_Tx" SG_ 76 SecondRowBuckleDriver 1;
BA_ "U_U502_MY15_Gas_Tx" SG_ 76 SecondRowBuckleDriver 1;
BA_ "U_CD43_MY16_Gas_Tx" SG_ 76 SecondRowBuckleDriver 1;
BA_ "CrossOver_InfoCAN" SG_ 76 FirstRowBuckleDriver 1;
BA_ "GenSigStartValue" SG_ 76 FirstRowBuckleDriver 3;
BA_ "GenSigSendType" SG_ 76 FirstRowBuckleDriver 3;
BA_ "U_CD4_MY13_Diesel_Rx" SG_ 76 FirstRowBuckleDriver 1;
BA_ "U_CD4_MY13_Gas_Rx" SG_ 76 FirstRowBuckleDriver 1;
BA_ "U_CD4_MY13_Hev_Rx" SG_ 76 FirstRowBuckleDriver 1;
BA_ "U_CD4_MY13_Phev_Rx" SG_ 76 FirstRowBuckleDriver 1;
BA_ "U_CD42_MY14_Diesel_Rx" SG_ 76 FirstRowBuckleDriver 1;
BA_ "U_CD42_MY14_Gas_Rx" SG_ 76 FirstRowBuckleDriver 1;
BA_ "U_P552_MY15_Gas_Rx" SG_ 76 FirstRowBuckleDriver 1;
BA_ "U_S550_MY15_Gas_Rx" SG_ 76 FirstRowBuckleDriver 1;
BA_ "U_C489_MY14_Gas_Rx" SG_ 76 FirstRowBuckleDriver 1;
BA_ "U_U502_MY15_Gas_Rx" SG_ 76 FirstRowBuckleDriver 1;
BA_ "U_UP375_MY15_Gas_Rx" SG_ 76 FirstRowBuckleDriver 1;
BA_ "U_UP375_MY15_Diesel_Rx" SG_ 76 FirstRowBuckleDriver 1;
BA_ "U_CD43_MY16_Gas_Rx" SG_ 76 FirstRowBuckleDriver 1;
BA_ "U_CD4_MY13_Diesel_Tx" SG_ 76 FirstRowBuckleDriver 1;
BA_ "U_CD4_MY13_Gas_Tx" SG_ 76 FirstRowBuckleDriver 1;
BA_ "U_CD4_MY13_Hev_Tx" SG_ 76 FirstRowBuckleDriver 1;
BA_ "U_CD4_MY13_Phev_Tx" SG_ 76 FirstRowBuckleDriver 1;
BA_ "U_CD42_MY14_Diesel_Tx" SG_ 76 FirstRowBuckleDriver 1;
BA_ "U_CD42_MY14_Gas_Tx" SG_ 76 FirstRowBuckleDriver 1;
BA_ "U_P552_MY15_Gas_Tx" SG_ 76 FirstRowBuckleDriver 1;
BA_ "U_S550_MY15_Gas_Tx" SG_ 76 FirstRowBuckleDriver 1;
BA_ "U_C489_MY14_Gas_Tx" SG_ 76 FirstRowBuckleDriver 1;
BA_ "U_U502_MY15_Gas_Tx" SG_ 76 FirstRowBuckleDriver 1;
BA_ "U_UP375_MY15_Gas_Tx" SG_ 76 FirstRowBuckleDriver 1;
BA_ "U_UP375_MY15_Diesel_Tx" SG_ 76 FirstRowBuckleDriver 1;
BA_ "U_CD43_MY16_Gas_Tx" SG_ 76 FirstRowBuckleDriver 1;
BA_ "CrossOver_InfoCAN" SG_ 76 RILReq 1;
BA_ "GenSigSendType" SG_ 76 RILReq 3;
BA_ "U_CD4_MY13_Diesel_Tx" SG_ 76 RILReq 1;
BA_ "U_CD4_MY13_Gas_Tx" SG_ 76 RILReq 1;
BA_ "U_CD4_MY13_Hev_Tx" SG_ 76 RILReq 1;
BA_ "U_CD4_MY13_Phev_Tx" SG_ 76 RILReq 1;
BA_ "U_CD42_MY14_Diesel_Tx" SG_ 76 RILReq 1;
BA_ "U_CD42_MY14_Gas_Tx" SG_ 76 RILReq 1;
BA_ "U_P552_MY15_Gas_Tx" SG_ 76 RILReq 1;
BA_ "U_S550_MY15_Gas_Tx" SG_ 76 RILReq 1;
BA_ "U_C489_MY14_Gas_Tx" SG_ 76 RILReq 1;
BA_ "U_U502_MY15_Gas_Tx" SG_ 76 RILReq 1;
BA_ "U_UP375_MY15_Gas_Tx" SG_ 76 RILReq 1;
BA_ "U_UP375_MY15_Diesel_Tx" SG_ 76 RILReq 1;
BA_ "U_CD43_MY16_Gas_Tx" SG_ 76 RILReq 1;
BA_ "CrossOver_InfoCAN" SG_ 76 FirstRowBucklePsngr 1;
BA_ "GenSigStartValue" SG_ 76 FirstRowBucklePsngr 3;
BA_ "GenSigSendType" SG_ 76 FirstRowBucklePsngr 3;
BA_ "U_CD4_MY13_Diesel_Rx" SG_ 76 FirstRowBucklePsngr 1;
BA_ "U_CD4_MY13_Gas_Rx" SG_ 76 FirstRowBucklePsngr 1;
BA_ "U_CD4_MY13_Hev_Rx" SG_ 76 FirstRowBucklePsngr 1;
BA_ "U_CD4_MY13_Phev_Rx" SG_ 76 FirstRowBucklePsngr 1;
BA_ "U_CD42_MY14_Diesel_Rx" SG_ 76 FirstRowBucklePsngr 1;
BA_ "U_CD42_MY14_Gas_Rx" SG_ 76 FirstRowBucklePsngr 1;
BA_ "U_P552_MY15_Gas_Rx" SG_ 76 FirstRowBucklePsngr 1;
BA_ "U_S550_MY15_Gas_Rx" SG_ 76 FirstRowBucklePsngr 1;
BA_ "U_C489_MY14_Gas_Rx" SG_ 76 FirstRowBucklePsngr 1;
BA_ "U_U502_MY15_Gas_Rx" SG_ 76 FirstRowBucklePsngr 1;
BA_ "U_CD43_MY16_Gas_Rx" SG_ 76 FirstRowBucklePsngr 1;
BA_ "U_CD4_MY14_Diesel_Rx" SG_ 76 FirstRowBucklePsngr 1;
BA_ "U_CD4_MY14_Gas_Rx" SG_ 76 FirstRowBucklePsngr 1;
BA_ "U_CD4_MY14_Hev_Rx" SG_ 76 FirstRowBucklePsngr 1;
BA_ "U_CD4_MY14_Phev_Rx" SG_ 76 FirstRowBucklePsngr 1;
BA_ "U_CD4_MY13_Diesel_Tx" SG_ 76 FirstRowBucklePsngr 1;
BA_ "U_CD4_MY13_Gas_Tx" SG_ 76 FirstRowBucklePsngr 1;
BA_ "U_CD4_MY13_Hev_Tx" SG_ 76 FirstRowBucklePsngr 1;
BA_ "U_CD4_MY13_Phev_Tx" SG_ 76 FirstRowBucklePsngr 1;
BA_ "U_CD42_MY14_Diesel_Tx" SG_ 76 FirstRowBucklePsngr 1;
BA_ "U_CD42_MY14_Gas_Tx" SG_ 76 FirstRowBucklePsngr 1;
BA_ "U_P552_MY15_Gas_Tx" SG_ 76 FirstRowBucklePsngr 1;
BA_ "U_S550_MY15_Gas_Tx" SG_ 76 FirstRowBucklePsngr 1;
BA_ "U_C489_MY14_Gas_Tx" SG_ 76 FirstRowBucklePsngr 1;
BA_ "U_U502_MY15_Gas_Tx" SG_ 76 FirstRowBucklePsngr 1;
BA_ "U_UP375_MY15_Gas_Tx" SG_ 76 FirstRowBucklePsngr 1;
BA_ "U_UP375_MY15_Diesel_Tx" SG_ 76 FirstRowBucklePsngr 1;
BA_ "U_CD43_MY16_Gas_Tx" SG_ 76 FirstRowBucklePsngr 1;
BA_ "GenSigTimeoutTime_OCS" SG_ 76 FirstRowBucklePsngr 6000;
BA_ "WakeupSignal" SG_ 76 RstrnImpactEvntStatus 1;
BA_ "CrossOver_InfoCAN" SG_ 76 RstrnImpactEvntStatus 1;
BA_ "GenSigSendType" SG_ 76 RstrnImpactEvntStatus 3;
BA_ "U_CD4_MY13_Diesel_Rx" SG_ 76 RstrnImpactEvntStatus 1;
BA_ "U_CD4_MY13_Gas_Rx" SG_ 76 RstrnImpactEvntStatus 1;
BA_ "U_CD4_MY13_Hev_Rx" SG_ 76 RstrnImpactEvntStatus 1;
BA_ "U_CD4_MY13_Phev_Rx" SG_ 76 RstrnImpactEvntStatus 1;
BA_ "U_CD42_MY14_Diesel_Rx" SG_ 76 RstrnImpactEvntStatus 1;
BA_ "U_CD42_MY14_Gas_Rx" SG_ 76 RstrnImpactEvntStatus 1;
BA_ "U_P552_MY15_Gas_Rx" SG_ 76 RstrnImpactEvntStatus 1;
BA_ "U_S550_MY15_Gas_Rx" SG_ 76 RstrnImpactEvntStatus 1;
BA_ "U_C489_MY14_Gas_Rx" SG_ 76 RstrnImpactEvntStatus 1;
BA_ "U_U502_MY15_Gas_Rx" SG_ 76 RstrnImpactEvntStatus 1;
BA_ "U_UP375_MY15_Gas_Rx" SG_ 76 RstrnImpactEvntStatus 1;
BA_ "U_UP375_MY15_Diesel_Rx" SG_ 76 RstrnImpactEvntStatus 1;
BA_ "U_CD43_MY16_Gas_Rx" SG_ 76 RstrnImpactEvntStatus 1;
BA_ "U_CD4_MY14_Diesel_Rx" SG_ 76 RstrnImpactEvntStatus 1;
BA_ "U_CD4_MY14_Gas_Rx" SG_ 76 RstrnImpactEvntStatus 1;
BA_ "U_CD4_MY14_Hev_Rx" SG_ 76 RstrnImpactEvntStatus 1;
BA_ "U_CD4_MY14_Phev_Rx" SG_ 76 RstrnImpactEvntStatus 1;
BA_ "U_CD4_MY13_Diesel_Tx" SG_ 76 RstrnImpactEvntStatus 1;
BA_ "U_CD4_MY13_Gas_Tx" SG_ 76 RstrnImpactEvntStatus 1;
BA_ "U_CD4_MY13_Hev_Tx" SG_ 76 RstrnImpactEvntStatus 1;
BA_ "U_CD4_MY13_Phev_Tx" SG_ 76 RstrnImpactEvntStatus 1;
BA_ "U_CD42_MY14_Diesel_Tx" SG_ 76 RstrnImpactEvntStatus 1;
BA_ "U_CD42_MY14_Gas_Tx" SG_ 76 RstrnImpactEvntStatus 1;
BA_ "U_P552_MY15_Gas_Tx" SG_ 76 RstrnImpactEvntStatus 1;
BA_ "U_S550_MY15_Gas_Tx" SG_ 76 RstrnImpactEvntStatus 1;
BA_ "U_C489_MY14_Gas_Tx" SG_ 76 RstrnImpactEvntStatus 1;
BA_ "U_U502_MY15_Gas_Tx" SG_ 76 RstrnImpactEvntStatus 1;
BA_ "U_UP375_MY15_Gas_Tx" SG_ 76 RstrnImpactEvntStatus 1;
BA_ "U_UP375_MY15_Diesel_Tx" SG_ 76 RstrnImpactEvntStatus 1;
BA_ "U_CD43_MY16_Gas_Tx" SG_ 76 RstrnImpactEvntStatus 1;
BA_ "GenSigTimeoutTime_OCS" SG_ 76 RstrnImpactEvntStatus 6000;
BA_ "CrossOver_InfoCAN" SG_ 76 PsngrFrntDetct_D_Actl 1;
BA_ "GenSigStartValue" SG_ 76 PsngrFrntDetct_D_Actl 3;
BA_ "GenSigSendType" SG_ 76 PsngrFrntDetct_D_Actl 3;
BA_ "U_CD4_MY13_Diesel_Tx" SG_ 76 PsngrFrntDetct_D_Actl 1;
BA_ "U_CD4_MY13_Gas_Tx" SG_ 76 PsngrFrntDetct_D_Actl 1;
BA_ "U_CD4_MY13_Hev_Tx" SG_ 76 PsngrFrntDetct_D_Actl 1;
BA_ "U_CD4_MY13_Phev_Tx" SG_ 76 PsngrFrntDetct_D_Actl 1;
BA_ "U_CD42_MY14_Diesel_Tx" SG_ 76 PsngrFrntDetct_D_Actl 1;
BA_ "U_CD42_MY14_Gas_Tx" SG_ 76 PsngrFrntDetct_D_Actl 1;
BA_ "U_P552_MY15_Gas_Tx" SG_ 76 PsngrFrntDetct_D_Actl 1;
BA_ "U_S550_MY15_Gas_Tx" SG_ 76 PsngrFrntDetct_D_Actl 1;
BA_ "U_C489_MY14_Gas_Tx" SG_ 76 PsngrFrntDetct_D_Actl 1;
BA_ "U_U502_MY15_Gas_Tx" SG_ 76 PsngrFrntDetct_D_Actl 1;
BA_ "U_UP375_MY15_Gas_Tx" SG_ 76 PsngrFrntDetct_D_Actl 1;
BA_ "U_UP375_MY15_Diesel_Tx" SG_ 76 PsngrFrntDetct_D_Actl 1;
BA_ "U_CD43_MY16_Gas_Tx" SG_ 76 PsngrFrntDetct_D_Actl 1;
BA_ "CrossOver_InfoCAN" SG_ 76 EDRTriggerEvntSync 1;
BA_ "GenSigSendType" SG_ 76 EDRTriggerEvntSync 3;
BA_ "U_U502_MY15_Gas_Rx" SG_ 76 EDRTriggerEvntSync 1;
BA_ "U_UP375_MY15_Gas_Rx" SG_ 76 EDRTriggerEvntSync 1;
BA_ "U_UP375_MY15_Diesel_Rx" SG_ 76 EDRTriggerEvntSync 1;
BA_ "U_CD43_MY16_Gas_Rx" SG_ 76 EDRTriggerEvntSync 1;
BA_ "U_CD4_MY13_Diesel_Tx" SG_ 76 EDRTriggerEvntSync 1;
BA_ "U_CD4_MY13_Gas_Tx" SG_ 76 EDRTriggerEvntSync 1;
BA_ "U_CD4_MY13_Hev_Tx" SG_ 76 EDRTriggerEvntSync 1;
BA_ "U_CD4_MY13_Phev_Tx" SG_ 76 EDRTriggerEvntSync 1;
BA_ "U_CD42_MY14_Diesel_Tx" SG_ 76 EDRTriggerEvntSync 1;
BA_ "U_CD42_MY14_Gas_Tx" SG_ 76 EDRTriggerEvntSync 1;
BA_ "U_P552_MY15_Gas_Tx" SG_ 76 EDRTriggerEvntSync 1;
BA_ "U_S550_MY15_Gas_Tx" SG_ 76 EDRTriggerEvntSync 1;
BA_ "U_C489_MY14_Gas_Tx" SG_ 76 EDRTriggerEvntSync 1;
BA_ "U_U502_MY15_Gas_Tx" SG_ 76 EDRTriggerEvntSync 1;
BA_ "U_UP375_MY15_Gas_Tx" SG_ 76 EDRTriggerEvntSync 1;
BA_ "U_UP375_MY15_Diesel_Tx" SG_ 76 EDRTriggerEvntSync 1;
BA_ "U_CD43_MY16_Gas_Tx" SG_ 76 EDRTriggerEvntSync 1;
BA_ "CrossOver_InfoCAN" SG_ 76 PassRstrnInd_Req 1;
BA_ "GenSigStartValue" SG_ 76 PassRstrnInd_Req 3;
BA_ "GenSigSendType" SG_ 76 PassRstrnInd_Req 3;
BA_ "U_CD4_MY13_Gas_Tx" SG_ 76 PassRstrnInd_Req 1;
BA_ "U_CD4_MY13_Hev_Tx" SG_ 76 PassRstrnInd_Req 1;
BA_ "U_CD4_MY13_Phev_Tx" SG_ 76 PassRstrnInd_Req 1;
BA_ "U_CD42_MY14_Diesel_Tx" SG_ 76 PassRstrnInd_Req 1;
BA_ "U_CD42_MY14_Gas_Tx" SG_ 76 PassRstrnInd_Req 1;
BA_ "U_P552_MY15_Gas_Tx" SG_ 76 PassRstrnInd_Req 1;
BA_ "U_C489_MY14_Gas_Tx" SG_ 76 PassRstrnInd_Req 1;
BA_ "U_U502_MY15_Gas_Tx" SG_ 76 PassRstrnInd_Req 1;
BA_ "U_UP375_MY15_Gas_Tx" SG_ 76 PassRstrnInd_Req 1;
BA_ "U_UP375_MY15_Diesel_Tx" SG_ 76 PassRstrnInd_Req 1;
BA_ "U_CD43_MY16_Gas_Tx" SG_ 76 PassRstrnInd_Req 1;
BA_ "GenSigStartValue" SG_ 120 TrlrAidCtl_U_RqDrv 4094;
BA_ "U_CD4_MY13_Gas_Rx" SG_ 120 PassRstrnInd_Stat_UB 1;
BA_ "U_CD4_MY13_Hev_Rx" SG_ 120 PassRstrnInd_Stat_UB 1;
BA_ "U_CD4_MY13_Phev_Rx" SG_ 120 PassRstrnInd_Stat_UB 1;
BA_ "U_CD42_MY14_Diesel_Rx" SG_ 120 PassRstrnInd_Stat_UB 1;
BA_ "U_CD42_MY14_Gas_Rx" SG_ 120 PassRstrnInd_Stat_UB 1;
BA_ "U_P552_MY15_Gas_Rx" SG_ 120 PassRstrnInd_Stat_UB 1;
BA_ "U_C489_MY14_Gas_Rx" SG_ 120 PassRstrnInd_Stat_UB 1;
BA_ "U_U502_MY15_Gas_Rx" SG_ 120 PassRstrnInd_Stat_UB 1;
BA_ "U_UP375_MY15_Gas_Rx" SG_ 120 PassRstrnInd_Stat_UB 1;
BA_ "U_UP375_MY15_Diesel_Rx" SG_ 120 PassRstrnInd_Stat_UB 1;
BA_ "U_CD43_MY16_Gas_Rx" SG_ 120 PassRstrnInd_Stat_UB 1;
BA_ "GenSigTimeoutTime_RCM" SG_ 120 PassRstrnInd_Stat_UB 1500;
BA_ "GenSigStartValue" SG_ 120 PassRstrnInd_Stat 1;
BA_ "U_CD4_MY13_Gas_Rx" SG_ 120 PassRstrnInd_Stat 1;
BA_ "U_CD4_MY13_Hev_Rx" SG_ 120 PassRstrnInd_Stat 1;
BA_ "U_CD4_MY13_Phev_Rx" SG_ 120 PassRstrnInd_Stat 1;
BA_ "U_CD42_MY14_Diesel_Rx" SG_ 120 PassRstrnInd_Stat 1;
BA_ "U_CD42_MY14_Gas_Rx" SG_ 120 PassRstrnInd_Stat 1;
BA_ "U_P552_MY15_Gas_Rx" SG_ 120 PassRstrnInd_Stat 1;
BA_ "U_C489_MY14_Gas_Rx" SG_ 120 PassRstrnInd_Stat 1;
BA_ "U_U502_MY15_Gas_Rx" SG_ 120 PassRstrnInd_Stat 1;
BA_ "U_UP375_MY15_Gas_Rx" SG_ 120 PassRstrnInd_Stat 1;
BA_ "U_UP375_MY15_Diesel_Rx" SG_ 120 PassRstrnInd_Stat 1;
BA_ "U_CD43_MY16_Gas_Rx" SG_ 120 PassRstrnInd_Stat 1;
BA_ "GenSigTimeoutTime_RCM" SG_ 120 PassRstrnInd_Stat 1500;
BA_ "CrossOver_InfoCAN" SG_ 120 HtrnWarnLamp_B_Dsply_UB 1;
BA_ "U_CD4_MY13_Diesel_Rx" SG_ 120 ECMMILRequest_UB 1;
BA_ "U_CD4_MY13_Gas_Rx" SG_ 120 ECMMILRequest_UB 1;
BA_ "U_CD4_MY13_Hev_Rx" SG_ 120 ECMMILRequest_UB 1;
BA_ "U_CD4_MY13_Phev_Rx" SG_ 120 ECMMILRequest_UB 1;
BA_ "U_CD42_MY14_Diesel_Rx" SG_ 120 ECMMILRequest_UB 1;
BA_ "U_CD42_MY14_Gas_Rx" SG_ 120 ECMMILRequest_UB 1;
BA_ "U_P552_MY15_Gas_Rx" SG_ 120 ECMMILRequest_UB 1;
BA_ "U_S550_MY15_Gas_Rx" SG_ 120 ECMMILRequest_UB 1;
BA_ "U_C489_MY14_Gas_Rx" SG_ 120 ECMMILRequest_UB 1;
BA_ "U_U502_MY15_Gas_Rx" SG_ 120 ECMMILRequest_UB 1;
BA_ "U_UP375_MY15_Gas_Rx" SG_ 120 ECMMILRequest_UB 1;
BA_ "U_UP375_MY15_Diesel_Rx" SG_ 120 ECMMILRequest_UB 1;
BA_ "U_CD43_MY16_Gas_Rx" SG_ 120 ECMMILRequest_UB 1;
BA_ "CrossOver_InfoCAN" SG_ 120 ECMMILRequest 1;
BA_ "U_CD4_MY13_Diesel_Rx" SG_ 120 ECMMILRequest 1;
BA_ "U_CD4_MY13_Gas_Rx" SG_ 120 ECMMILRequest 1;
BA_ "U_CD4_MY13_Hev_Rx" SG_ 120 ECMMILRequest 1;
BA_ "U_CD4_MY13_Phev_Rx" SG_ 120 ECMMILRequest 1;
BA_ "U_CD42_MY14_Diesel_Rx" SG_ 120 ECMMILRequest 1;
BA_ "U_CD42_MY14_Gas_Rx" SG_ 120 ECMMILRequest 1;
BA_ "U_P552_MY15_Gas_Rx" SG_ 120 ECMMILRequest 1;
BA_ "U_S550_MY15_Gas_Rx" SG_ 120 ECMMILRequest 1;
BA_ "U_C489_MY14_Gas_Rx" SG_ 120 ECMMILRequest 1;
BA_ "U_U502_MY15_Gas_Rx" SG_ 120 ECMMILRequest 1;
BA_ "U_UP375_MY15_Gas_Rx" SG_ 120 ECMMILRequest 1;
BA_ "U_UP375_MY15_Diesel_Rx" SG_ 120 ECMMILRequest 1;
BA_ "U_CD43_MY16_Gas_Rx" SG_ 120 ECMMILRequest 1;
BA_ "WakeupSignal" SG_ 120 TrnIpcDsplyMde_D_Stat 1;
BA_ "CrossOver_InfoCAN" SG_ 120 TrnIpcDsplyMde_D_Stat 1;
BA_ "WakeupSignal" SG_ 120 TrnIpcDsplyMde_D_Actl 1;
BA_ "CrossOver_InfoCAN" SG_ 120 TrnIpcDsplyMde_D_Actl 1;
BA_ "CrossOver_InfoCAN" SG_ 120 EngSrvcRqd_B_Rq 1;
BA_ "U_CD4_MY13_Diesel_Rx" SG_ 120 EngSrvcRqd_B_Rq 1;
BA_ "U_CD4_MY13_Gas_Rx" SG_ 120 EngSrvcRqd_B_Rq 1;
BA_ "U_CD4_MY13_Hev_Rx" SG_ 120 EngSrvcRqd_B_Rq 1;
BA_ "U_CD4_MY13_Phev_Rx" SG_ 120 EngSrvcRqd_B_Rq 1;
BA_ "U_CD42_MY14_Diesel_Rx" SG_ 120 EngSrvcRqd_B_Rq 1;
BA_ "U_CD42_MY14_Gas_Rx" SG_ 120 EngSrvcRqd_B_Rq 1;
BA_ "U_P552_MY15_Gas_Rx" SG_ 120 EngSrvcRqd_B_Rq 1;
BA_ "U_S550_MY15_Gas_Rx" SG_ 120 EngSrvcRqd_B_Rq 1;
BA_ "U_C489_MY14_Gas_Rx" SG_ 120 EngSrvcRqd_B_Rq 1;
BA_ "U_U502_MY15_Gas_Rx" SG_ 120 EngSrvcRqd_B_Rq 1;
BA_ "U_UP375_MY15_Gas_Rx" SG_ 120 EngSrvcRqd_B_Rq 1;
BA_ "U_UP375_MY15_Diesel_Rx" SG_ 120 EngSrvcRqd_B_Rq 1;
BA_ "U_CD43_MY16_Gas_Rx" SG_ 120 EngSrvcRqd_B_Rq 1;
BA_ "CrossOver_InfoCAN" SG_ 120 HtrnSrvcRqd_B_Dsply_UB 1;
BA_ "GenSigSendType" SG_ 1665 UUDTRCMResponse2 3;
BA_ "U_CD4_MY13_Diesel_Tx" SG_ 1665 UUDTRCMResponse2 1;
BA_ "U_CD4_MY13_Gas_Tx" SG_ 1665 UUDTRCMResponse2 1;
BA_ "U_CD4_MY13_Hev_Tx" SG_ 1665 UUDTRCMResponse2 1;
BA_ "U_CD4_MY13_Phev_Tx" SG_ 1665 UUDTRCMResponse2 1;
BA_ "U_CD42_MY14_Diesel_Tx" SG_ 1665 UUDTRCMResponse2 1;
BA_ "U_CD42_MY14_Gas_Tx" SG_ 1665 UUDTRCMResponse2 1;
BA_ "U_P552_MY15_Gas_Tx" SG_ 1665 UUDTRCMResponse2 1;
BA_ "U_S550_MY15_Gas_Tx" SG_ 1665 UUDTRCMResponse2 1;
BA_ "U_C489_MY14_Gas_Tx" SG_ 1665 UUDTRCMResponse2 1;
BA_ "U_U502_MY15_Gas_Tx" SG_ 1665 UUDTRCMResponse2 1;
BA_ "U_UP375_MY15_Gas_Tx" SG_ 1665 UUDTRCMResponse2 1;
BA_ "U_UP375_MY15_Diesel_Tx" SG_ 1665 UUDTRCMResponse2 1;
BA_ "U_CD43_MY16_Gas_Tx" SG_ 1665 UUDTRCMResponse2 1;
BA_ "GenSigSendType" SG_ 2041 TesterPhysicalResPCU 3;
BA_ "U_CD4_MY13_Diesel_Tx" SG_ 2041 TesterPhysicalResPCU 1;
BA_ "U_CD4_MY13_Gas_Tx" SG_ 2041 TesterPhysicalResPCU 1;
BA_ "U_CD4_MY13_Hev_Tx" SG_ 2041 TesterPhysicalResPCU 1;
BA_ "U_CD4_MY13_Phev_Tx" SG_ 2041 TesterPhysicalResPCU 1;
BA_ "U_CD42_MY14_Diesel_Tx" SG_ 2041 TesterPhysicalResPCU 1;
BA_ "U_CD42_MY14_Gas_Tx" SG_ 2041 TesterPhysicalResPCU 1;
BA_ "U_P552_MY15_Gas_Tx" SG_ 2041 TesterPhysicalResPCU 1;
BA_ "U_S550_MY15_Gas_Tx" SG_ 2041 TesterPhysicalResPCU 1;
BA_ "U_C489_MY14_Gas_Tx" SG_ 2041 TesterPhysicalResPCU 1;
BA_ "U_U502_MY15_Gas_Tx" SG_ 2041 TesterPhysicalResPCU 1;
BA_ "U_UP375_MY15_Gas_Tx" SG_ 2041 TesterPhysicalResPCU 1;
BA_ "U_UP375_MY15_Diesel_Tx" SG_ 2041 TesterPhysicalResPCU 1;
BA_ "U_CD43_MY16_Gas_Tx" SG_ 2041 TesterPhysicalResPCU 1;
BA_ "GenSigSendType" SG_ 1438 GWM_AutoSar_NetworkMgmt_H2 3;
BA_ "U_CD4_MY13_Diesel_Rx" SG_ 1438 GWM_AutoSar_NetworkMgmt_H2 1;
BA_ "U_CD4_MY13_Gas_Rx" SG_ 1438 GWM_AutoSar_NetworkMgmt_H2 1;
BA_ "U_CD4_MY13_Hev_Rx" SG_ 1438 GWM_AutoSar_NetworkMgmt_H2 1;
BA_ "U_CD4_MY13_Phev_Rx" SG_ 1438 GWM_AutoSar_NetworkMgmt_H2 1;
BA_ "U_CD42_MY14_Diesel_Rx" SG_ 1438 GWM_AutoSar_NetworkMgmt_H2 1;
BA_ "U_CD42_MY14_Gas_Rx" SG_ 1438 GWM_AutoSar_NetworkMgmt_H2 1;
BA_ "U_P552_MY15_Gas_Rx" SG_ 1438 GWM_AutoSar_NetworkMgmt_H2 1;
BA_ "U_S550_MY15_Gas_Rx" SG_ 1438 GWM_AutoSar_NetworkMgmt_H2 1;
BA_ "U_C489_MY14_Gas_Rx" SG_ 1438 GWM_AutoSar_NetworkMgmt_H2 1;
BA_ "U_U502_MY15_Gas_Rx" SG_ 1438 GWM_AutoSar_NetworkMgmt_H2 1;
BA_ "U_UP375_MY15_Gas_Rx" SG_ 1438 GWM_AutoSar_NetworkMgmt_H2 1;
BA_ "U_UP375_MY15_Diesel_Rx" SG_ 1438 GWM_AutoSar_NetworkMgmt_H2 1;
BA_ "U_CD43_MY16_Gas_Rx" SG_ 1438 GWM_AutoSar_NetworkMgmt_H2 1;
BA_ "CrossOver_InfoCAN" SG_ 1034 VehicleGGCCData 1;
BA_ "U_CD42_MY14_Diesel_Rx" SG_ 1034 VehicleGGCCData 1;
BA_ "U_CD42_MY14_Gas_Rx" SG_ 1034 VehicleGGCCData 1;
BA_ "U_P552_MY15_Gas_Rx" SG_ 1034 VehicleGGCCData 1;
BA_ "U_S550_MY15_Gas_Rx" SG_ 1034 VehicleGGCCData 1;
BA_ "U_C489_MY14_Gas_Rx" SG_ 1034 VehicleGGCCData 1;
BA_ "U_U502_MY15_Gas_Rx" SG_ 1034 VehicleGGCCData 1;
BA_ "U_UP375_MY15_Gas_Rx" SG_ 1034 VehicleGGCCData 1;
BA_ "U_UP375_MY15_Diesel_Rx" SG_ 1034 VehicleGGCCData 1;
BA_ "U_CD43_MY16_Gas_Rx" SG_ 1034 VehicleGGCCData 1;
BA_ "U_CD4_MY14_Diesel_Rx" SG_ 1034 VehicleGGCCData 1;
BA_ "U_CD4_MY14_Gas_Rx" SG_ 1034 VehicleGGCCData 1;
BA_ "U_CD4_MY14_Hev_Rx" SG_ 1034 VehicleGGCCData 1;
BA_ "U_CD4_MY14_Phev_Rx" SG_ 1034 VehicleGGCCData 1;
BA_ "U_P552_MY15_Gas_Tx" SG_ 1034 VehicleGGCCData 1;
BA_ "GenSigTimeoutTime_RCM" SG_ 1034 VehicleGGCCData 600;
BA_ "GenSigTimeoutTime_OCS" SG_ 1034 VehicleGGCCData 6000;
VAL_ 938 PrkAidMsgTxt_D_Rq 15 "NotUsed7" 14 "NotUsed6" 13 "NotUsed5" 12 "R_Sns_Inactive_Trlr_atch" 11 "Not_Avail_Trlr_attchd" 10 "Fail_Mode_no_Chime" 9 "Fail_Mode_with_Chime" 8 "NotUsed4" 7 "NotUsed3" 6 "Park_Sys_Alternate_Mode" 5 "R_Snsrs_On_F_Snsrs_On" 4 "NotUsed2" 3 "NotUsed1" 2 "R_Snsrs_Off_F_Snsrs_On" 1 "R_Snsrs_On_F_Snsrs_Off" 0 "All_Park_Sensors_Off" ;
VAL_ 938 PrkAidSnsFrSide_D_Stat 15 "Zone_15" 14 "Zone_14" 13 "Zone_13" 12 "Zone_12" 11 "Zone_11" 10 "Zone_10" 9 "Zone_9" 8 "Zone_8" 7 "Zone_7" 6 "Zone_6" 5 "Zone_5" 4 "Zone_4" 3 "Zone_3" 2 "Zone_2" 1 "Zone_1" 0 "Off" ;
VAL_ 938 PrkAidSnsFrCrnr_D_Stat 15 "Zone_15" 14 "Zone_14" 13 "Zone_13" 12 "Zone_12" 11 "Zone_11" 10 "Zone_10" 9 "Zone_9" 8 "Zone_8" 7 "Zone_7" 6 "Zone_6" 5 "Zone_5" 4 "Zone_4" 3 "Zone_3" 2 "Zone_2" 1 "Zone_1" 0 "Off" ;
VAL_ 938 PrkAidSnsFrCntr_D_Stat 15 "Zone_15" 14 "Zone_14" 13 "Zone_13" 12 "Zone_12" 11 "Zone_11" 10 "Zone_10" 9 "Zone_9" 8 "Zone_8" 7 "Zone_7" 6 "Zone_6" 5 "Zone_5" 4 "Zone_4" 3 "Zone_3" 2 "Zone_2" 1 "Zone_1" 0 "Off" ;
VAL_ 938 PrkAidSnsFlSide_D_Stat 15 "Zone_15" 14 "Zone_14" 13 "Zone_13" 12 "Zone_12" 11 "Zone_11" 10 "Zone_10" 9 "Zone_9" 8 "Zone_8" 7 "Zone_7" 6 "Zone_6" 5 "Zone_5" 4 "Zone_4" 3 "Zone_3" 2 "Zone_2" 1 "Zone_1" 0 "Off" ;
VAL_ 938 PrkAidSnsFlCrnr_D_Stat 15 "Zone_15" 14 "Zone_14" 13 "Zone_13" 12 "Zone_12" 11 "Zone_11" 10 "Zone_10" 9 "Zone_9" 8 "Zone_8" 7 "Zone_7" 6 "Zone_6" 5 "Zone_5" 4 "Zone_4" 3 "Zone_3" 2 "Zone_2" 1 "Zone_1" 0 "Off" ;
VAL_ 938 PrkAidSnsFlCntr_D_Stat 15 "Zone_15" 14 "Zone_14" 13 "Zone_13" 12 "Zone_12" 11 "Zone_11" 10 "Zone_10" 9 "Zone_9" 8 "Zone_8" 7 "Zone_7" 6 "Zone_6" 5 "Zone_5" 4 "Zone_4" 3 "Zone_3" 2 "Zone_2" 1 "Zone_1" 0 "Off" ;
VAL_ 1186 RearDiffLckMsg_D_Rq 7 "Locker_Disabled" 6 "Locker_Enabled" 5 "Locker_Accel_Pedal" 4 "Speed4" 3 "Speed3" 2 "Speed2" 1 "Speed1" 0 "Normal__No_Message " ;
VAL_ 1186 RearDiffLckLamp_D_Rq 3 "Not_Used" 2 "Flash" 1 "On" 0 "Off" ;
VAL_ 1186 RearDiffLck_Tq_Actl 4095 "Fault" 4094 "Unknown" ;
VAL_ 1186 RearDiffFalt_D_Stat 3 "Diff_Failed_Closed" 2 "Diff_Failed_Open" 1 "Fault_Non_Specific" 0 "No_Fault" ;
VAL_ 1186 LsdSrvcRqd_B_Rq 1 "On" 0 "Off" ;
VAL_ 1042 VehRol_An_Dsply 127 "Faulty" 126 "NoDataExists" ;
VAL_ 1042 VehPtch_An_Dsply 127 "Faulty" 126 "NoDataExists" ;
VAL_ 1090 TrlrAnOffstDir_D_Calc 3 "NotUSed" 2 "Right" 1 "Left_or_Center" 0 "Null" ;
VAL_ 1090 TrlrAnCalib_Pc_Actl 15 "Faulty" ;
VAL_ 1090 TrlrTrgtAcquire_D_Stat 7 "Faulty" 6 "NotUsed_2" 5 "NotUsed_1" 4 "RVCforTBA_Activated" 3 "Processing" 2 "TargetNotAcquired" 1 "TargetAcquired" 0 "Null" ;
VAL_ 1090 TrlrAid_D_Stat 15 "Faulty" 14 "Trgt_Acqrd_Conf_Unk_w_Par" 13 "TAD_Rq_Denied" 12 "Trgt_Acqrd_Conf_High_w_Par" 11 "Trgt_Acqrd_Conf_Med_w_Par" 10 "Trgt_Acqrd_Conf_Low_w_Par" 9 "Insufficient_Lighting" 8 "No_Video_Input" 7 "Sensor_Blocked" 6 "Target_Cannot_Be_Located" 5 "Invalid_Parameters" 4 "Trgt_Acqrd_Confidence_High" 3 "Trgt_Acqrd_Confidence_Med" 2 "Trgt_Acqrd_Confidence_Low" 1 "Init" 0 "Target_Not_Acquired" ;
VAL_ 1090 TrlrAid_AnRate_Actl 4095 "Faulty" ;
VAL_ 1090 TrlrAid2_An_Actl 4095 "Faulty" ;
VAL_ 1006 PersIndexIpmb_D_Actl 7 "Unused_3" 6 "Unused_2" 5 "Unused_1" 4 "Vehicle" 3 "PERS_4" 2 "PERS_3" 1 "PERS_2" 0 "PERS_1" ;
VAL_ 1200 BrkAutoHold_D_Stat 7 "Faulty" 6 "NotUsed" 5 "Releasing" 4 "HeldSecondary" 3 "HeldSecure" 2 "Held" 1 "Inactive" 0 "Off" ;
VAL_ 1200 BrkBstrVac_P_Actl 127 "Invalid" ;
VAL_ 1200 YawStabilityIndex 511 "Fault" 510 "NoDataExists" ;
VAL_ 1200 BrkTot_Tq_RqDrv 8191 "Fault" ;
VAL_ 673 ICI_Coding_BtnID_D 15 "Idle" 5 "Stuck" 4 "LongEvent" 3 "ShortElapsed" 2 "ShortEvent" 1 "Active" 0 "Inactive" ;
VAL_ 673 ICI_Coding_BtnID_C 15 "Idle" 5 "Stuck" 4 "LongEvent" 3 "ShortElapsed" 2 "ShortEvent" 1 "Active" 0 "Inactive" ;
VAL_ 673 ICI_Coding_BtnID_B 15 "Idle" 5 "Stuck" 4 "LongEvent" 3 "ShortElapsed" 2 "ShortEvent" 1 "Active" 0 "Inactive" ;
VAL_ 673 ICI_Coding_BtnID_A 15 "Idle" 5 "Stuck" 4 "LongEvent" 3 "ShortElapsed" 2 "ShortEvent" 1 "Active" 0 "Inactive" ;
VAL_ 845 StmsLmbrPsgr_D_Stat 3 "High" 2 "Low" 1 "Off" 0 "Null" ;
VAL_ 845 StmsCshnPsgr_D_Stat 3 "High" 2 "Low" 1 "Off" 0 "Null" ;
VAL_ 845 SeatSwtchPsgr_B_Stat 1 "On" 0 "Off" ;
VAL_ 845 SeatPPsgr_B_Stat 1 "Updating" 0 "NotUpdating" ;
VAL_ 845 SeatFnPsgr_D_Stat 7 "CushionMassage" 6 "LumbarMassage" 5 "UpperBolster" 4 "LowerBolster" 3 "UpperLumbar" 2 "MiddleLumbar" 1 "LowerLumbar" 0 "Null" ;
VAL_ 845 PsgrMemFeedback_Rsp 8 "Recall_4" 7 "Recall_3" 6 "Recall_2" 5 "Recall_1" 4 "Store_4" 3 "Store_3" 2 "Store_2" 1 "Store_1" 0 "Inactive" ;
VAL_ 850 SeatBlLoPsgr_Pc_Actl2 127 "Null" ;
VAL_ 850 SeatCshnPsgrRR_Pc_Actl 127 "Null" ;
VAL_ 850 SeatCshnPsgrRL_Pc_Actl 127 "Null" ;
VAL_ 850 SeatCshnPsgrFR_Pc_Actl 127 "Null" ;
VAL_ 850 SeatCshnPsgrFL_Pc_Actl 127 "Null" ;
VAL_ 935 CtaSnsRight_D_Stat 3 "Invalid" 2 "System_Failure" 1 "Blocked" 0 "Clear" ;
VAL_ 935 CtaAlrtRight_D_Stat 1 "On" 0 "Off" ;
VAL_ 935 CtaRight_D_Stat 4 "Invalid" 3 "Disabled" 2 "On" 1 "Trailer_Tow_Off" 0 "Off" ;
VAL_ 935 SodRight_D_Stat 4 "Invalid" 3 "Disabled" 2 "On" 1 "Trailer_Tow_Off" 0 "Off" ;
VAL_ 935 SodSnsRight_D_Stat 3 "Second_Warning_Audio" 2 "System_Failure" 1 "Blocked" 0 "Clear" ;
VAL_ 935 SodAlrtRight_D_Stat 3 "Bulb_Proveout" 2 "Flash" 1 "On" 0 "Off" ;
VAL_ 935 SodDetctRight_D_Stat 4 "Sensor_Blocked" 3 "Sensor_Fault" 2 "Flash_On" 1 "Alert_On" 0 "AlertOff_FlashOff_SensrClr" ;
VAL_ 935 SodInnrRight_D_Stat 3 "Reporting" 2 "Not_Reporting" 1 "System_Standby" 0 "Initialization" ;
VAL_ 935 CtaInnrRight_D_Stat 3 "Reporting" 2 "Not_Reporting" 1 "System_Standby" 0 "Initialization" ;
VAL_ 934 CtaSnsLeft_D_Stat 3 "Invalid" 2 "System_Failure" 1 "Blocked" 0 "Clear" ;
VAL_ 934 SodDetctLeft_D_Stat 4 "Sensor_Blocked" 3 "Sensor_Fault" 2 "Flash_On" 1 "Alert_On" 0 "AlertOff_FlashOff_SensrClr" ;
VAL_ 934 CtaLeft_D_Stat 4 "Invalid" 3 "Disabled" 2 "On" 1 "Trailer_Tow_Off" 0 "Off" ;
VAL_ 934 CtaAlrtLeft_D_Stat 1 "On" 0 "Off" ;
VAL_ 934 SodLeft_D_Stat 4 "Invalid" 3 "Disabled" 2 "On" 1 "Trailer_Tow_Off" 0 "Off" ;
VAL_ 934 SodSnsLeft_D_Stat 3 "Second_Warning_Audio" 2 "System_Failure" 1 "Blocked" 0 "Clear" ;
VAL_ 934 SodAlrtLeft_D_Stat 3 "Bulb_Proveout" 2 "Flash" 1 "On" 0 "Off" ;
VAL_ 934 SodInnrLeft_D_Stat 3 "Reporting" 2 "Not_Reporting" 1 "System_Standby" 0 "Initialization" ;
VAL_ 934 CtaInnrLeft_D_Stat 3 "Reporting" 2 "Not_Reporting" 1 "System_Standby" 0 "Initialization" ;
VAL_ 1091 ParkLampTrlrOut_B_Stat 1 "Out" 0 "Null" ;
VAL_ 1091 StopLampTrlrOut_B_Stat 1 "Out" 0 "Null" ;
VAL_ 1091 TrlrBattChrg_D_Stat 3 "Reverse" 2 "Normal" 1 "Low" 0 "Null" ;
VAL_ 1091 TrlrLampCtl_D_Stat 3 "NotUsed" 2 "TrlrLampCnnctDrvFailure" 1 "TrlrLampNotCnnctDrvFailure" 0 "Null" ;
VAL_ 1091 TurnLampTrlrRr_B_Stat 1 "Out" 0 "Null" ;
VAL_ 1091 TurnLampTrlrRl_B_Stat 1 "Out" 0 "Null" ;
VAL_ 1091 TrlrLampCnnct_B_Actl 1 "Yes" 0 "No" ;
VAL_ 1068 EngStrtInhbt_B_RqBatt 1 "Start_Inhibit" 0 "Dont_Care" ;
VAL_ 1068 BattULoChrg_D_Rq 3 "Low_Battery_Temperature" 2 "Charging_Requested" 1 "Chrg_Requested_HighCurrent" 0 "No_Request" ;
VAL_ 1068 PwSysULoFalt_D_Stat 15 "Not_Used_6" 14 "LowBatterySOC" 13 "PSS_Shed2_Contin" 12 "Not_Used_4" 11 "Not_Used_3" 10 "Not_Used_2" 9 "BattMonitoringSensorFault" 8 "LowBattVoltDuringPwSrcOn" 7 "LowBatt2_PowerSaveMode" 6 "LowBatt1_Warning" 5 "Overvoltage" 4 "Fault_NoOutput" 3 "Fault_ReducedOutput" 2 "Fault_Nonspecific" 1 "Cluster_Proveout" 0 "No_Fault" ;
VAL_ 1068 Shed_T_Eng_Off_B 1 "Active" 0 "Inactive" ;
VAL_ 1068 Shed_Feature_Group_ID 14 "HtdMirr" 13 "HvacRearBlwr_Third" 12 "HvacRearBlwr_Second" 11 "HvacRearBlwr_First" 31 "All LSHED1 Features" 10 "Htd_Windscrn" 9 "SpltHtdBcklight_HtdMirr" 8 "HtdBcklight_HtdMirr" 7 "HtdCoolSeat_FrtDriver" 6 "HtdCoolSeat_FrtPass" 5 "HtdCoolSeat_RearPass" 4 "HtdCoolSeat_RearDriver" 3 "SmartTrlrTowBattCharge" 2 "Htd_StrWhl" 1 "Htd_Washer_Fluid" 0 "No_LSHED1_Features" 15 "Engine_Coolant_Fan" ;
VAL_ 1068 Shed_Drain_Eng_Off_B 1 "Active" 0 "Inactive" ;
VAL_ 1068 Shed_Level_Req 7 "Unused_2" 6 "Loads_On" 5 "SHED_ENG_OFF" 4 "SOON_ENG_OFF" 3 "SHED2_CONTIN" 2 "SHED2_TRANS" 1 "SHED1" 0 "NO_SHED" ;
VAL_ 1068 ChargeMode 7 "Undefined_2" 6 "Undefined_1" 5 "Battery_Identify" 4 "Battery_Refresh" 3 "SlowRegenAllowNoDischarge" 2 "Fast_Regen_Allowed" 1 "Slow_Regen_Allowed" 0 "Conventional_Charging" ;
VAL_ 1068 IdleSpeedIncrease_El 1 "Yes" 0 "No" ;
VAL_ 1068 Batt_Lo_SoC_B 1 "Active" 0 "Inactive" ;
VAL_ 1068 PeriodicElLoad_B_Stat 1 "Active" 0 "Inactive" ;
VAL_ 1068 Batt_Crit_SoC_B 1 "Active" 0 "Inactive" ;
VAL_ 611 AwdDrvMde_D_Stat 7 "Faulty" 6 "NotAvailable" 5 "RockCrawl" 4 "Baja" 3 "MudAndSand" 2 "Weather" 1 "Sport" 0 "Normal" ;
VAL_ 611 NtrlTowAvail_B_Stat 1 "Available" 0 "NotAvailable" ;
VAL_ 611 AwdSys_D_Stat 3 "Faulty" 2 "NotUsed" 1 "_4x4_L_H_Active" 0 "_4x4_L_H_Inactive" ;
VAL_ 611 AwdStat_D_RqDsply 31 "NotUsed9" 30 "NotUsed8" 29 "NotUsed7" 28 "NotUsed6" 27 "NotUsed5" 26 "NotUsed4" 25 "Lkr_Mode_Unavail_TMS" 24 "_4x4_Mode_Unavail_TMS" 23 "Out_of_4Low_Crawl" 22 "AWD_PTU_Oil_Changed" 21 "Change_AWD_PTU_Oil" 20 "Neutral_Tow_Disabled" 19 "Neutral_Tow_Enabled" 18 "AWD_OFF" 17 "_4x4_Off_Road_Speed" 16 "_4x4_Extreme_Off_Road_Mode" 15 "_4x4_Exiting_Off_Road" 14 "_4x4_Off_Road_Mode" 10 "_4x4_Locked_Temporarily" 9 "Shift_In_Progress" 13 "Blocked_Shift_Assist" 12 "_4x4_Auto_Restored" 11 "_4x4_Disabled_Temporarily" 7 "Out_of_4Low__Neutral" 6 "Out_of_4Low__Brake" 5 "Out_of_4Low__Speed" 4 "Into_4Low__Clutch" 3 "Into_4Low__Neutral" 2 "Into_4Low__Brake" 1 "Into_4Low__Speed" 0 "Normal__No_Message" 8 "Out_of_4Low__Clutch" ;
VAL_ 611 AwdLck_D_Stat 9 "Undefined" 8 "Under_External_Torque_Ctrl" 7 "Torque_Limited_by_Cmd" 6 "Fully_Locked_by_Cmd" 5 "Disabled" 4 "Warning" 3 "Fault" 2 "Inactive" 1 "Completely_Opened_by_Cmd" 0 "OK" ;
VAL_ 611 AwdSrvcRqd_B_Rq 1 "On" 0 "Off" ;
VAL_ 611 AwdLck_Tq_Rq 4095 "Fault" 4094 "Unknown" ;
VAL_ 611 AwdOffRoadMode_D_Stats 3 "Invalid" 2 "Extreme_Off_Road" 1 "Off_Road" 0 "Normal_Mode" ;
VAL_ 611 AwdLoLamp_D_RqDsply 3 "Not_Used" 2 "Flash" 1 "On" 0 "Off" ;
VAL_ 611 AwdHiLamp_D_RqDsply 3 "Not_Used" 2 "Flash" 1 "On" 0 "Off" ;
VAL_ 611 AwdAutoLamp_D_RqDsply 3 "Not_Used" 2 "Flash" 1 "On" 0 "Off" ;
VAL_ 611 Awd2wdLamp_D_RqDsply 3 "Not_Used" 2 "Flash" 1 "On" 0 "Off" ;
VAL_ 611 AwdRnge_D_Actl 7 "Unknown" 6 "High_Range_2wd" 5 "High_Range_Auto" 4 "High_Range_Locked" 3 "Neutral" 2 "Low_Range_2wd" 1 "Low_Range_Auto" 0 "Low_Range_Locked" ;
VAL_ 578 immoSecureIdleMode 3 "NotUsed2" 2 "NotUsed1" 1 "Active" 0 "Inactive" ;
VAL_ 578 BattULo_U_Actl 255 "Fault" ;
VAL_ 578 PrkLckCtl_B_Enbl 1 "Enable" 0 "Disable" ;
VAL_ 578 PrkLckCtlMsgTxt_D_Rq 3 "BTSI_DI_3" 2 "BTSI_DI_2" 1 "BTSI_DI_1" 0 "Null_BTSI_DI" ;
VAL_ 578 BrkTrnShifLck_B_Stat 1 "Shift" 0 "NoShift" ;
VAL_ 578 DriverCrankingReq 1 "Crank_Request" 0 "No_Crank_Request" ;
VAL_ 578 EngOff_T_Actl 65535 "Invalid" ;
VAL_ 578 ReFuelSwtchStat_D_Actl 3 "NotUsed2" 2 "NotUsed1" 1 "On" 0 "Off" ;
VAL_ 578 DcacElPw_D_Rq 3 "NotUsed" 2 "AC_HighPower_Requested" 1 "AC_LowPower_Requested" 0 "AC_Power_NotRequested" ;
VAL_ 578 BattULo_I_Actl 16383 "Fault" ;
VAL_ 560 GearLvr_D_ActlDrv 15 "Fault" 14 "Unknown_Position" 13 "Undefined_Treat_as__Fault" 12 "Undefined_Treat_as_Fault" 11 "sixth" 10 "fifth" 9 "fourth" 8 "third" 7 "second" 6 "first" 5 "Low" 4 "Sport_DriveSport" 3 "Drive" 2 "Neutral" 1 "Reverse" 0 "Park" ;
VAL_ 560 SelDrvMdeSwtch_D_Stat3 3 "Faulty" 2 "SwitchState2" 1 "SwitchState1" 0 "NotPressed" ;
VAL_ 560 TrnSrvcRqd_B_Rq 1 "On" 0 "Off" ;
VAL_ 560 GearPos_D_Trg 15 "Unknown" 14 "Reverse" 13 "Undefined_5" 12 "Undefined_4" 11 "Undefined_3" 10 "Tenth" 9 "Ninth" 8 "Eighth" 7 "Seventh" 6 "Sixth" 5 "Fifth" 4 "Fourth" 3 "Third" 2 "Second" 1 "First" 0 "Neutral" ;
VAL_ 560 TrnShifActv_B_Actl 1 "Active" 0 "Inactive" ;
VAL_ 560 GearLvrPos_D_Actl 15 "Fault" 14 "Unknown_Position" 13 "Undefined_Treat_as__Fault" 12 "Undefined_Treat_as_Fault" 11 "sixth" 10 "fifth" 9 "fourth" 8 "third" 7 "second" 6 "first" 5 "Low" 4 "Sport_DriveSport" 3 "Drive" 2 "Neutral" 1 "Reverse" 0 "Park" ;
VAL_ 560 GboxOil_Te_Actl 255 "Fault" 254 "Unknown" ;
VAL_ 359 ElPw_D_StatStrtStop 15 "NotUsed6" 14 "NotUsed5" 13 "NotUsed4" 12 "NotUsed3" 11 "NotUsed2" 10 "NotUsed1" 9 "Supported_Level_4" 8 "Supported_Level_3" 7 "Supported_Level_2" 6 "Supported_Level_1" 5 "Limited_Support" 4 "Fault_Limited" 3 "LV_Event_in_Progress" 2 "Not_Supported_Imminent" 1 "Supported_All" 0 "Not_Supported" ;
VAL_ 359 PrplWhlTot2_Tq_Actl 65535 "Fault" 65534 "NoDataExists" ;
VAL_ 359 PwPckTq_D_Stat 3 "PwPckOn_TqAvailable" 2 "StartInPrgrss_TqNotAvail" 1 "PwPckOn_TqNotAvailable" 0 "PwPckOff_TqNotAvailable" ;
VAL_ 359 Eng_D_Stat 3 "NotUsed" 2 "EngAutoStopped" 1 "EngOn" 0 "EngOff" ;
VAL_ 359 ElPw_D_Stat 7 "NotUsed_3" 6 "NotUsed_2" 5 "NotUsed_1" 4 "Fault_Limited" 3 "LV_Event_In_Progress" 2 "Not_Supported_Imminent" 1 "Supported" 0 "Not_Supported" ;
VAL_ 359 TrnAinTq_D_Qf 3 "OK" 2 "Not_Within_Specifications" 1 "No_Data_Exists" 0 "Faulty" ;
VAL_ 357 CmbbEngTqMn_B_Actl 1 "Yes" 0 "No" ;
VAL_ 357 CmbbDeny_B_ActlPrpl 1 "Yes" 0 "No" ;
VAL_ 357 AccStopMde_D_Rq 3 "Stop_Mode_Active" 2 "EPBApplyOrBrakeReleaseWarn" 1 "Limit_Rolling_Speed" 0 "Stop_Mode_Not_Active" ;
VAL_ 357 BPedDrvAppl_D_QF 3 "OK" 2 "Not_Within_Specifications" 1 "No_Data_Exists" 0 "Faulty" ;
VAL_ 357 PrplTqMnSat_B_Actl 1 "Yes" 0 "No" ;
VAL_ 357 BpedDrvAppl_D_Actl 3 "_Not_Allowed" 2 "Driver_Braking" 1 "Driver_Not_Braking" 0 "Not_Allowed" ;
VAL_ 357 Veh_V_DsplyCcSet 255 "Fault" 254 "Unknown" ;
VAL_ 357 AccEngStat_D_Actl 7 "Undefined_2" 6 "Undefined_1" 5 "ACCSoonCancel_due_Low_Spd" 4 "Shift_Down_Recommendation" 3 "Shift_Up_Recommendation" 2 "ACCNotAllowedToBeActivated" 1 "ACCStandby_due_Auto_Cancel" 0 "Normal_Operation" ;
VAL_ 357 CcMde_D_Actl 7 "TapDownWaiting" 6 "TapUpWaiting" 5 "Resuming_Low" 4 "Resuming_High" 3 "Decelerating" 2 "Accelerating" 1 "Keeping_Speed" 0 "Not_Active" ;
VAL_ 357 CcStat_D_Actl 7 "Undefined_2" 6 "Undefined_1" 5 "Active" 4 "Active_Que_Assist" 3 "Standby" 2 "Standby_Denied" 1 "Denied" 0 "Off" ;
VAL_ 357 CcOvrrdActv_B_Actl 1 "Cruise_Overridden" 0 "Cruise_Req_Not_Overridden" ;
VAL_ 390 AccStopStat_B_Rq 1 "Yes" 0 "No" ;
VAL_ 390 AccResumEnbl_B_Rq 1 "Yes" 0 "No" ;
VAL_ 390 AccBrkPrkEl_B_Rq 1 "Yes" 0 "No" ;
VAL_ 390 Cmbb_B_Enbl 1 "Yes" 0 "No" ;
VAL_ 390 CmbbOvrrd_B_RqDrv 1 "Yes" 0 "No" ;
VAL_ 390 CmbbDeny_B_Actl 1 "Yes" 0 "No" ;
VAL_ 390 CmbbEngTqMn_B_Rq 1 "Yes" 0 "No" ;
VAL_ 390 AccDeny_B_Rq 1 "Yes" 0 "No" ;
VAL_ 390 AccCancl_B_Rq 1 "Yes" 0 "No" ;
VAL_ 390 AccBrkPrchg_B_Rq 1 "Yes" 0 "No" ;
VAL_ 390 AccBrkDecel_B_Rq 1 "Active" 0 "Inactive" ;
VAL_ 1072 TrlrAidCancl_B_Rq_UB 1 "Fresh_data" 0 "Unchanged_data" ;
VAL_ 1072 TrlrAidCancl_B_Rq 1 "Cancel" 0 "Null" ;
VAL_ 1072 HsaMde_D_Rq 3 "Undefined" 2 "Manual" 1 "Automatic" 0 "Off" ;
VAL_ 1072 HsaMde_D_Rq_UB 1 "Fresh_data" 0 "Unchanged_data" ;
VAL_ 1072 Multimedia_System_UB 1 "Fresh_data" 0 "Unchanged_data" ;
VAL_ 1072 Multimedia_System 1 "On" 0 "Off" ;
VAL_ 1072 LscmbbStat_B_Actl 1 "On" 0 "Off" ;
VAL_ 1072 LscmbbStat_B_Actl_UB 1 "Fresh_data" 0 "Unchanged_data" ;
VAL_ 1072 Outside_Air_Temp_Stat_UB 1 "Fresh_data" 0 "Unchanged_data" ;
VAL_ 1072 Outside_Air_Temp_Stat 255 "Invalid" 254 "Unknown" ;
VAL_ 1072 BulbChkActv_B_Stat_UB 1 "Fresh_data" 0 "Unchanged_data" ;
VAL_ 1072 BulbChkActv_B_Stat 1 "Active" 0 "Inactive" ;
VAL_ 1072 Fda_B_Stat_UB 1 "Fresh_data" 0 "Unchanged_data" ;
VAL_ 1072 AccEnbl_B_RqDrv_UB 1 "Fresh_data" 0 "Unchanged_data" ;
VAL_ 1072 AccDeny_B_RqIpc_UB 1 "Fresh_data" 0 "Unchanged_data" ;
VAL_ 1072 OdometerMasterValue_UB 1 "Fresh_data" 0 "Unchanged_data" ;
VAL_ 1072 OdometerMasterValue 16777215 "Invalid" ;
VAL_ 1072 Fda_B_Stat 1 "On" 0 "Off" ;
VAL_ 1072 AccDeny_B_RqIpc 1 "Yes" 0 "No" ;
VAL_ 1072 AccEnbl_B_RqDrv 1 "Adaptive_Cruise" 0 "Normal_Cruise" ;
VAL_ 1072 DrvSlipCtlMde_D_Rq_UB 1 "Fresh_data" 0 "Unchanged_data" ;
VAL_ 1072 DrvSlipCtlMde_D_Rq 3 "App_Specific_Off_Mode_3" 2 "App_Specific_Off_Mode_2" 1 "App_Specific_Off_Mode_1" 0 "Default_Mode" ;
VAL_ 1072 DrvSlipCtlMde_B_Rq_UB 1 "Fresh_data" 0 "Unchanged_data" ;
VAL_ 1072 DrvSlipCtlMde_B_Rq 1 "Pressed" 0 "Not_Pressed" ;
VAL_ 1072 ePRNDL_MODE_UB 1 "Fresh_data" 0 "Unchanged_data" ;
VAL_ 1072 ePRNDL_MODE 1 "On" 0 "Off" ;
VAL_ 1072 TrlrBrkMde_D_Rq 1 "ElectricOverHydraulic" 0 "Electric" ;
VAL_ 1072 TRLR_SWAY_CONFIG_CMD 1 "On" 0 "Off" ;
VAL_ 1072 TRAILER_BRAKE_CONFIG 1 "Yes" 0 "No" ;
VAL_ 1072 TrlrBrkMde_D_Rq_UB 1 "Fresh_data" 0 "Unchanged_data" ;
VAL_ 1072 TRLR_SWAY_CONFIG_CMD_UB 1 "Fresh_data" 0 "Unchanged_data" ;
VAL_ 1072 TRAILER_BRAKE_CONFIG_UB 1 "Fresh_data" 0 "Unchanged_data" ;
VAL_ 1058 DrvSlipCtlMde_B_Rq2_UB 1 "Fresh_data" 0 "Unchanged_data" ;
VAL_ 1058 DrvSlipCtlMde_B_Rq2 1 "Pressed" 0 "Not_Pressed" ;
VAL_ 1058 BattTracWarnLamp_B_Rq_UB 1 "Fresh_data" 0 "Unchanged_data" ;
VAL_ 1058 BattTracWarnLamp_B_Rq 1 "On" 0 "Off" ;
VAL_ 1058 BattTracSrvcRqd_B_Rq_UB 1 "Fresh_data" 0 "Unchanged_data" ;
VAL_ 1058 BattTracSrvcRqd_B_Rq 1 "On" 0 "Off" ;
VAL_ 1058 SeatBlLoPsgr_Pc_Actl_UB 1 "Fresh_data" 0 "Unchanged_data" ;
VAL_ 1058 SeatBlLoPsgr_Pc_Actl 127 "Null" ;
VAL_ 1058 HILL_DESC_SW_UB 1 "Fresh_data" 0 "Unchanged_data" ;
VAL_ 1058 HILL_DESC_SW 1 "On" 0 "Off" ;
VAL_ 1058 EngClntTe_D_Qf 3 "OK" 2 "Not_Within_Specifications" 1 "No_Data_Exists" 0 "Faulty" ;
VAL_ 1058 EngClnt_Te_Actl_UB 1 "Fresh_data" 0 "Unchanged_data" ;
VAL_ 512 PtDrvMde_D_Stat 15 "Faulty" 14 "NotUsed11" 13 "NotUsed10" 12 "NotUsed9" 11 "NotUsed8" 10 "NotUsed7" 9 "NotUsed6" 8 "NotUsed5" 7 "NotUsed4" 6 "Rock" 5 "Baja" 4 "Sand" 3 "TowHaulGradeAssist" 2 "SnowWet" 1 "Sport" 0 "Normal" ;
VAL_ 936 EPASExtAngleStatReq 1 "Request" 0 "NoRequest" ;
VAL_ 936 ExtSteeringAngleReq2 32767 "Invalid" 32766 "Unknown" ;
VAL_ 936 SAPPErrorCoding 32 "Error_32" 31 "Error_31" 30 "Error_30" 29 "Error_29" 28 "Error_28" 27 "Error_27" 26 "Error_26" 25 "Error_25" 24 "Error_24" 23 "Error_23" 22 "Error_22" 21 "Error_21" 20 "Error_20" 19 "Error_19" 18 "Error_18" 17 "Error_17" 16 "Error_16" 15 "Error_15" 14 "Error_14" 13 "Error_13" 12 "Error_12" 11 "Error_11" 10 "Error_10" 9 "Error_9" 8 "Error_8" 7 "Error_7" 6 "Error_6" 5 "Error_5" 4 "Error_4" 3 "Error_3" 2 "Error_2" 1 "Error_1" 0 "Not_Used" ;
VAL_ 76 SecondRowBucklePsngr 3 "Unknown" 2 "Unbelted" 1 "Belted" 0 "Faulty" ;
VAL_ 76 SecondRowBuckleDriver 3 "Unknown" 2 "Unbelted" 1 "Belted" 0 "Faulty" ;
VAL_ 76 FirstRowBuckleDriver 3 "Unknown" 2 "Unbelted" 1 "Belted" 0 "Faulty" ;
VAL_ 76 RILReq 3 "Not_Used" 2 "Plant_Mode" 1 "On" 0 "Off" ;
VAL_ 76 FirstRowBucklePsngr 3 "Unknown" 2 "Unbelted" 1 "Belted" 0 "Faulty" ;
VAL_ 76 RstrnImpactEvntStatus 7 "Invalid" 6 "Not_Used_4" 5 "Threshold_2_Exceeded" 4 "Not_Used_3" 3 "Threshold_1_Exceeded" 2 "Not_Used_2" 1 "Not_Used_1" 0 "Normal" ;
VAL_ 76 PsngrFrntDetct_D_Actl 3 "Unknown" 2 "Empty" 0 "Faulty" 1 "Occupied" ;
VAL_ 76 EDRTriggerEvntSync 1 "Threshold_Exceeded" 0 "Normal" ;
VAL_ 76 PassRstrnInd_Req 3 "ABOnNotIllum_OffNotIllum" 2 "AirbagOnNot_Illum_OffIllum" 1 "AirbagOn_Illum_OffNotIllum" 0 "AirbagOn_Illum_Off_Illum" ;
VAL_ 120 TrlrAidSwtch_D_RqDrv_UB 1 "Fresh_data" 0 "Unchanged_data" ;
VAL_ 120 TrlrAidSwtch_D_RqDrv 3 "Faulty" 2 "NotUsed" 1 "Pressed" 0 "Not_Pressed" ;
VAL_ 120 TrlrAidCtl_U_RqDrv_UB 1 "Fresh_data" 0 "Unchanged_data" ;
VAL_ 120 TrlrAidCtl_U_RqDrv 4095 "Faulty" 4094 "NoDataExists" ;
VAL_ 120 PassRstrnInd_Stat_UB 1 "Fresh_data" 0 "Unchanged_data" ;
VAL_ 120 PassRstrnInd_Stat 7 "Invalid" 6 "Unused_2" 5 "Unused_1" 4 "Both_Indicators_Faulted" 3 "AirbagOff_Indicator_fault" 2 "AirbagOn_Indicator_fault" 1 "Normal" 0 "Not_Supported" ;
VAL_ 120 HtrnWarnLamp_B_Dsply_UB 1 "Fresh_data" 0 "Unchanged_data" ;
VAL_ 120 ECMMILRequest_UB 1 "Fresh_data" 0 "Unchanged_data" ;
VAL_ 120 ECMMILRequest 3 "Not_Used" 2 "Flash" 1 "On" 0 "Off" ;
VAL_ 120 TrnIpcDsplyMde_D_Stat 3 "Reserved_Blank_No_Display" 2 "Flash" 1 "On" 0 "Blank_No_Display" ;
VAL_ 120 TrnIpcDsplyMde_D_Actl 7 "Manual_3" 6 "Manual_2" 5 "Manual_1_Low" 4 "Sport" 3 "Drive" 2 "Neutral" 1 "Reverse" 0 "Park" ;
VAL_ 120 EngSrvcRqd_B_Rq_UB 1 "Fresh_data" 0 "Unchanged_data" ;
VAL_ 120 EngSrvcRqd_B_Rq 1 "Engine_Service_Required" 0 "No_engine_service_required" ;
VAL_ 120 HtrnSrvcRqd_B_Dsply_UB 1 "Fresh_data" 0 "Unchanged_data" ;
VAL_ 120 TrnIpcDsplyMde_D_Stat_UB 1 "Fresh_data" 0 "Unchanged_data" ;
VAL_ 120 TrnIpcDsplyMde_D_Actl_UB 1 "Fresh_data" 0 "Unchanged_data" ;
